VERSION ""

NS_ :

BS_:

BU_: VMCU TECU OBDScanT2 IC3 HPCU EMS ECUspare2 ECUspare1 DACU CIOM BBM

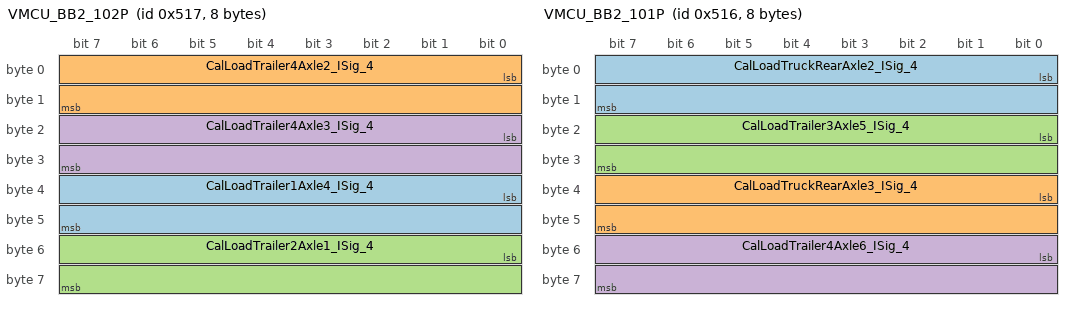
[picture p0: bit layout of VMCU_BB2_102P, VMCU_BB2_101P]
BO_ 1303 VMCU_BB2_102P: 8 VMCU
 SG_ CalLoadTrailer1Axle4_ISig_4 : 32|16@1+ (0.5,0) [0|32767.5] "kg"  IC3,CIOM,BBM
 SG_ CalLoadTrailer4Axle2_ISig_4 : 0|16@1+ (0.5,0) [0|32767.5] "kg"  CIOM,IC3
 SG_ CalLoadTrailer2Axle1_ISig_4 : 48|16@1+ (0.5,0) [0|32767.5] "kg"  CIOM,BBM,IC3
 SG_ CalLoadTrailer4Axle3_ISig_4 : 16|16@1+ (0.5,0) [0|32767.5] "kg"  CIOM,IC3

BO_ 1302 VMCU_BB2_101P: 8 VMCU
 SG_ CalLoadTruckRearAxle2_ISig_4 : 0|16@1+ (0.5,0) [0|32767.5] "kg"  BBM,IC3,CIOM
 SG_ CalLoadTruckRearAxle3_ISig_4 : 32|16@1+ (0.5,0) [0|32767.5] "kg"  BBM,CIOM,IC3
 SG_ CalLoadTrailer3Axle5_ISig_4 : 16|16@1+ (0.5,0) [0|32767.5] "kg"  IC3,CIOM
 SG_ CalLoadTrailer4Axle6_ISig_4 : 48|16@1+ (0.5,0) [0|32767.5] "kg"  IC3,CIOM

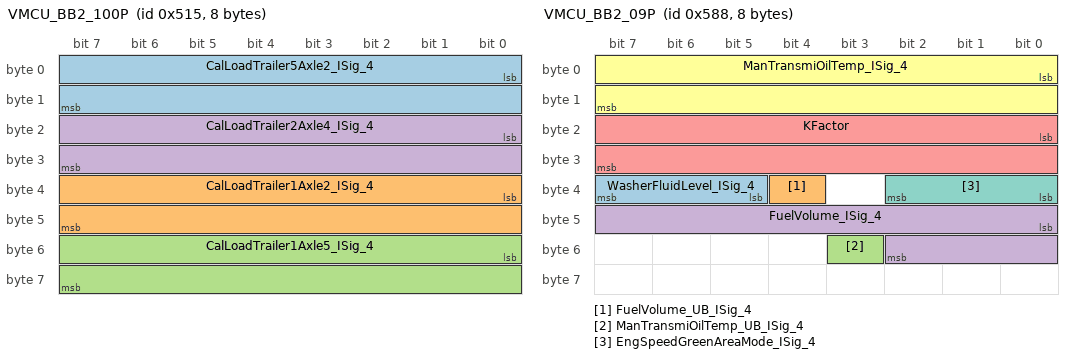
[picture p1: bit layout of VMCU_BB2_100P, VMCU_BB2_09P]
BO_ 1301 VMCU_BB2_100P: 8 VMCU
 SG_ CalLoadTrailer5Axle2_ISig_4 : 0|16@1+ (0.5,0) [0|32767.5] "kg"  CIOM,IC3
 SG_ CalLoadTrailer1Axle2_ISig_4 : 32|16@1+ (0.5,0) [0|32767.5] "kg"  IC3,CIOM,BBM
 SG_ CalLoadTrailer1Axle5_ISig_4 : 48|16@1+ (0.5,0) [0|32767.5] "kg"  IC3,CIOM
 SG_ CalLoadTrailer2Axle4_ISig_4 : 16|16@1+ (0.5,0) [0|32767.5] "kg"  CIOM,BBM,IC3

BO_ 1416 VMCU_BB2_09P: 8 VMCU
 SG_ WasherFluidLevel_ISig_4 : 37|3@1+ (1,0) [0|0] ""  IC3
 SG_ FuelVolume_UB_ISig_4 : 36|1@1+ (1,0) [0|0] ""  IC3
 SG_ ManTransmiOilTemp_UB_ISig_4 : 51|1@1+ (1,0) [0|0] ""  IC3
 SG_ FuelVolume_ISig_4 : 40|11@1+ (1,0) [0|2047] "l"  IC3
 SG_ KFactor : 16|16@1+ (1,0) [0|65535] "NotApplicable"  EMS,TECU,BBM,DACU
 SG_ ManTransmiOilTemp_ISig_4 : 0|16@1+ (0.03125,-273) [-273|1774.96875] "DegreeC"  IC3
 SG_ EngSpeedGreenAreaMode_ISig_4 : 32|3@1+ (1,0) [0|0] ""  IC3

BO_ 1050 VMCU_BB2_08P: 8 VMCU
 SG_ CabRoofSignLightFeedback_stat : 52|2@1+ (1,0) [0|0] ""  CIOM
 SG_ CabExtraSideWrknLightFdbk_stat_I : 4|2@1+ (1,0) [0|0] ""  CIOM,BBM
 SG_ CabWrknLightChassisFdbk_stat_ISi : 10|2@1+ (1,0) [0|0] ""  BBM,CIOM
 SG_ CabTrailerBodyLgthnFdbk_stat : 8|2@1+ (1,0) [0|0] ""  CIOM
 SG_ DiffLockInterWhlStatusSplitBox_I : 56|2@1+ (1,0) [0|0] ""  BBM
 SG_ BodyOrCabWorkingLightFdbk_stat_I : 0|2@1+ (1,0) [0|0] ""  CIOM,BBM
 SG_ WheelBasedVehicleSpeedLowRes_ISi : 32|8@1+ (1,0) [0|255] "Km_per_h"  CIOM
 SG_ AirDryerCoolingFanSpeed_rqst : 16|16@1+ (1,0) [0|65535] "rpm"  EMS
 SG_ CabFrontSpotFeedback_Status : 6|2@1+ (1,0) [0|0] ""  CIOM
 SG_ CabTiltEnableStatus : 2|2@1+ (1,0) [0|0] ""  CIOM
 SG_ TransmReverseDirectionSw_stat_IS : 58|2@1+ (1,0) [0|0] ""  BBM
 SG_ CabRoofSpotFeedback_Status : 12|2@1+ (1,0) [0|0] ""  CIOM
 SG_ CabBeaconLightFeedback_Status_IS : 50|2@1+ (1,0) [0|0] ""  CIOM,BBM
 SG_ ExtraAxleSteeringFunctionStat_IS : 60|3@1+ (1,0) [0|0] ""  CIOM
 SG_ AirDryerCoolingFanSpeed_rqst_UB : 48|1@1+ (1,0) [0|0] ""  EMS
 SG_ CabTiltLockStatus_ISig_4 : 14|2@1+ (1,0) [0|0] ""  BBM,IC3
 SG_ PositionLightRearLamp_stat_ISig_ : 45|3@1+ (1,0) [0|0] ""  IC3

BO_ 931 VMCU_BB2_07P: 8 VMCU
 SG_ Pto1BadCondition : 4|4@1+ (1,0) [0|0] ""  BBM,IC3
 SG_ PtosStatus_UB_ISig_4 : 40|1@1+ (1,0) [0|0] ""  EMS,CIOM,BBM,IC3
 SG_ Pto4BadCondition : 12|4@1+ (1,0) [0|0] ""  IC3,BBM
 SG_ Pto2BadCondition : 8|4@1+ (1,0) [0|0] ""  IC3,BBM
 SG_ PtoRequest : 18|2@1+ (1,0) [0|0] ""  EMS
 SG_ Pto2ConsentRequest : 32|2@1+ (1,0) [0|0] ""  TECU
 SG_ PBStatusDisplay_cmd_ISig_4 : 42|2@1+ (1,0) [0|0] ""  IC3
 SG_ Pto4DrivingRequest : 28|2@1+ (1,0) [0|0] ""  BBM
 SG_ Pto3Indication : 58|2@1+ (1,0) [0|0] ""  CIOM
 SG_ Pto2Status_ISig_4 : 22|2@1+ (1,0) [0|0] ""  IC3,TECU,CIOM,BBM
 SG_ Pto4Status_ISig_4 : 34|2@1+ (1,0) [0|0] ""  CIOM,IC3,BBM
 SG_ RampLevelRequestACK_ISig_4 : 44|2@1+ (1,0) [0|0] ""  CIOM
 SG_ Pto3BadCondition : 0|4@1+ (1,0) [0|0] ""  IC3,BBM
 SG_ PtosStatus_ISig_4 : 36|2@1+ (1,0) [0|0] ""  BBM,CIOM,EMS,IC3
 SG_ FrontWheelDriveAutoStatus_ISig_4 : 46|2@1+ (1,0) [0|0] ""  BBM,IC3
 SG_ Pto1ConsentRequest : 24|2@1+ (1,0) [0|0] ""  TECU
 SG_ Pto4Indication : 60|2@1+ (1,0) [0|0] ""  CIOM
 SG_ Pto1FeedbackStatus_UB_ISig_4 : 41|1@1+ (1,0) [0|0] ""  BBM,IC3
 SG_ Pto1Indication : 53|2@1+ (1,0) [0|0] ""  CIOM
 SG_ Pto3Status_ISig_4 : 16|2@1+ (1,0) [0|0] ""  BBM,IC3,CIOM
 SG_ Pto2Indication : 56|2@1+ (1,0) [0|0] ""  CIOM
 SG_ Pto1FeedbackStatus_ISig_4 : 38|2@1+ (1,0) [0|0] ""  BBM
 SG_ TransferCaseOrSplitboxPTOMode_IS : 26|2@1+ (1,0) [0|0] ""  TECU,BBM
 SG_ DirIndRearLamp_Stat_ISig_4 : 50|3@1+ (1,0) [0|0] ""  IC3
 SG_ Pto1Status_ISig_4 : 20|2@1+ (1,0) [0|0] ""  CIOM,TECU,BBM,IC3
 SG_ Pto3DrivingRequest : 30|2@1+ (1,0) [0|0] ""  BBM

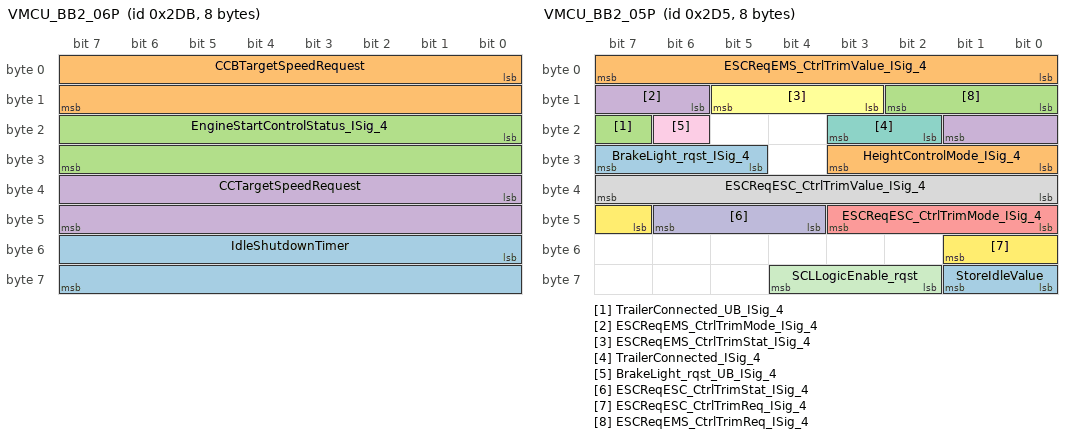
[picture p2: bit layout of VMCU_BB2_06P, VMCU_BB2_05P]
BO_ 731 VMCU_BB2_06P: 8 VMCU
 SG_ IdleShutdownTimer : 48|16@1+ (1,0) [0|65535] "s"  IC3
 SG_ CCBTargetSpeedRequest : 0|16@1+ (0.00390625,0) [0|255.99609375] "Km_per_h"  EMS,TECU
 SG_ EngineStartControlStatus_ISig_4 : 16|16@1+ (1,0) [0|0] ""  IC3,BBM
 SG_ CCTargetSpeedRequest : 32|16@1+ (0.00390625,0) [0|255.99609375] "Km_per_h"  TECU,EMS

BO_ 725 VMCU_BB2_05P: 8 VMCU
 SG_ StoreIdleValue : 56|2@1+ (1,0) [0|0] ""  IC3,EMS
 SG_ HeightControlMode_ISig_4 : 24|4@1+ (1,0) [0|0] ""  IC3
 SG_ TrailerConnected_UB_ISig_4 : 23|1@1+ (1,0) [0|0] ""  IC3,EMS,DACU,TECU,BBM
 SG_ ESCReqEMS_CtrlTrimMode_ISig_4 : 14|4@1+ (1,0) [0|0] ""  EMS,TECU,IC3
 SG_ ESCReqESC_CtrlTrimMode_ISig_4 : 40|4@1+ (1,0) [0|0] ""  CIOM,IC3,BBM
 SG_ ESCReqEMS_CtrlTrimStat_ISig_4 : 11|3@1+ (1,0) [0|0] ""  IC3,EMS,TECU
 SG_ TrailerConnected_ISig_4 : 18|2@1+ (1,0) [0|0] ""  TECU,IC3,EMS,DACU,BBM
 SG_ ESCReqESC_CtrlTrimValue_ISig_4 : 32|8@1+ (10,0) [0|2550] ""  BBM,IC3,CIOM
 SG_ BrakeLight_rqst_UB_ISig_4 : 22|1@1+ (1,0) [0|0] ""  DACU,BBM
 SG_ ESCReqESC_CtrlTrimStat_ISig_4 : 44|3@1+ (1,0) [0|0] ""  CIOM,BBM,IC3
 SG_ SCLLogicEnable_rqst : 58|3@1+ (1,0) [0|0] ""  CIOM
 SG_ ESCReqESC_CtrlTrimReq_ISig_4 : 47|3@1+ (1,0) [0|0] ""  IC3,CIOM,BBM
 SG_ BrakeLight_rqst_ISig_4 : 29|3@1+ (1,0) [0|0] ""  DACU,BBM
 SG_ ESCReqEMS_CtrlTrimValue_ISig_4 : 0|8@1+ (10,0) [0|2550] ""  IC3,TECU,EMS
 SG_ ESCReqEMS_CtrlTrimReq_ISig_4 : 8|3@1+ (1,0) [0|0] ""  IC3,TECU,EMS

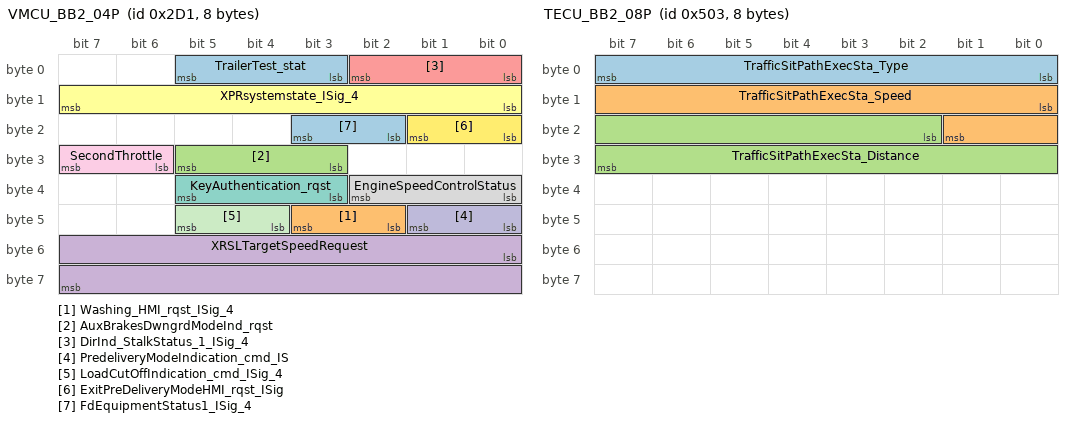
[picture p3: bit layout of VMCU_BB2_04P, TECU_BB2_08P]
BO_ 721 VMCU_BB2_04P: 8 VMCU
 SG_ TrailerTest_stat : 3|3@1+ (1,0) [0|0] ""  IC3
 SG_ Washing_HMI_rqst_ISig_4 : 42|2@1+ (1,0) [0|0] ""  CIOM
 SG_ AuxBrakesDwngrdModeInd_rqst : 27|3@1+ (1,0) [0|0] ""  IC3
 SG_ XRSLTargetSpeedRequest : 48|16@1+ (0.00390625,0) [0|255.99609375] "Km_per_h"  EMS
 SG_ DirInd_StalkStatus_1_ISig_4 : 0|3@1+ (1,0) [0|0] ""  IC3
 SG_ XPRsystemstate_ISig_4 : 8|8@1+ (1,0) [0|255] "NotApplicable"  DACU,BBM
 SG_ KeyAuthentication_rqst : 35|3@1+ (1,0) [0|0] ""  CIOM
 SG_ EngineSpeedControlStatus : 32|3@1+ (1,0) [0|0] ""  CIOM,IC3,BBM
 SG_ SecondThrottle : 30|2@1+ (1,0) [0|0] ""  EMS,DACU,BBM
 SG_ PredeliveryModeIndication_cmd_IS : 40|2@1+ (1,0) [0|0] ""  IC3,CIOM
 SG_ LoadCutOffIndication_cmd_ISig_4 : 44|2@1+ (1,0) [0|0] ""  IC3
 SG_ ExitPreDeliveryModeHMI_rqst_ISig : 16|2@1+ (1,0) [0|0] ""  CIOM
 SG_ FdEquipmentStatus1_ISig_4 : 18|2@1+ (1,0) [0|0] ""  BBM,IC3,CIOM

BO_ 534 VMCU_BB2_03P: 8 VMCU
 SG_ ParkBrakeAlert_ISig_4 : 42|2@1+ (1,0) [0|0] ""  IC3,BBM
 SG_ IntLightMode_CoreRqst_IL_Mode : 48|3@1+ (1,0) [0|0] ""  IC3,CIOM
 SG_ WiperModeStatus_UB_ISig_4 : 55|1@1+ (1,0) [0|0] ""  CIOM,BBM,IC3,DACU
 SG_ SteeringColumnLockErrInd_rqst : 27|3@1+ (1,0) [0|0] ""  IC3
 SG_ ParkingLight_Indication : 30|2@1+ (1,0) [0|0] ""  CIOM
 SG_ DaytimeRunningLight_Indication : 16|2@1+ (1,0) [0|0] ""  CIOM
 SG_ EPBBackupMode_ISig_4 : 44|4@1+ (1,0) [0|0] ""  IC3
 SG_ WiperModeStatus_ISig_4 : 32|3@1+ (1,0) [0|0] ""  CIOM,DACU,IC3,BBM
 SG_ FrontFog_Indication_ISig_4 : 22|2@1+ (1,0) [0|0] ""  CIOM
 SG_ PBReleaseAcceptance_stat_ISig_4 : 37|3@1+ (1,0) [0|0] ""  IC3
 SG_ ParkingBrake_stat_UB_ISig_4 : 54|1@1+ (1,0) [0|0] ""  IC3,EMS,CIOM,DACU,TECU,BBM
 SG_ DrivingLightPlus_Indication : 8|2@1+ (1,0) [0|0] ""  CIOM
 SG_ IntLightMode_CoreRqst_EventFlag : 51|1@1+ (1,0) [0|0] ""  CIOM,IC3
 SG_ ParkingBrake_stat_ISig_4 : 40|2@1+ (1,0) [0|0] ""  EMS,DACU,IC3,CIOM,BBM,TECU
 SG_ DrivingLight_Indication : 4|2@1+ (1,0) [0|0] ""  CIOM
 SG_ MirrorHeatingMode_ISig_4 : 24|3@1+ (1,0) [0|0] ""  CIOM
 SG_ RearFog_Indication : 35|2@1+ (1,0) [0|0] ""  CIOM
 SG_ InteriorLightLevelInd_cmd : 56|8@1+ (1,0) [0|255] "Percent"  CIOM

BO_ 532 VMCU_BB2_02P: 8 VMCU
 SG_ LevelControlInformation_UB_ISig_ : 22|1@1+ (1,0) [0|0] ""  CIOM,IC3,TECU
 SG_ LiftAxle2LiftFuncSelected_ISig_4 : 11|3@1+ (1,0) [0|0] ""  IC3
 SG_ StopLevelChangeAck_ISig_4 : 6|2@1+ (1,0) [0|0] ""  CIOM
 SG_ HeightAdjustmentAllowed_ISig_4 : 38|2@1+ (1,0) [0|0] ""  CIOM
 SG_ LiftAxle2LowerACK_ISig_4 : 27|3@1+ (1,0) [0|0] ""  IC3
 SG_ LiftAxle2UpRequestACK_ISig_4 : 0|3@1+ (1,0) [0|0] ""  CIOM,IC3
 SG_ RideHeightStatus_ISig_4 : 44|4@1+ (1,0) [0|0] ""  CIOM,BBM
 SG_ RideHeightOutsideTargetRange_ISi : 32|3@1+ (1,0) [0|0] ""  IC3,CIOM
 SG_ LoadDistributionFuncSelected_ISi : 56|4@1+ (1,0) [0|0] ""  CIOM
 SG_ RideHeightStorageAck_ISig_4 : 30|2@1+ (1,0) [0|0] ""  CIOM
 SG_ LiftAxle2AutoLiftSelected_ISig_4 : 54|2@1+ (1,0) [0|0] ""  IC3
 SG_ LiftAxle1UpRequestACK_ISig_4 : 3|3@1+ (1,0) [0|0] ""  IC3,CIOM
 SG_ LiftAxle1PositionStatus_ISig_4 : 16|3@1+ (1,0) [0|0] ""  BBM,CIOM,TECU,DACU,IC3
 SG_ LiftAxle1LowerACK_ISig_4 : 24|3@1+ (1,0) [0|0] ""  IC3
 SG_ LiftAxle1AutoLiftSelected_ISig_4 : 52|2@1+ (1,0) [0|0] ""  IC3
 SG_ LiftAxle2PositionStatus_ISig_4 : 19|3@1+ (1,0) [0|0] ""  IC3,BBM,CIOM
 SG_ LevelControlInformation_ISig_4 : 48|4@1+ (1,0) [0|0] ""  TECU,IC3,CIOM
 SG_ LiftAxle1LiftFuncSelected_ISig_4 : 8|3@1+ (1,0) [0|0] ""  IC3
 SG_ LoadDistributionChangeACK_ISig_4 : 35|3@1+ (1,0) [0|0] ""  CIOM,IC3
 SG_ RampLevelStorageAck_ISig_4 : 14|2@1+ (1,0) [0|0] ""  CIOM
 SG_ LoadDistributionSelected_ISig_4 : 60|4@1+ (1,0) [0|0] ""  BBM,CIOM
 SG_ RideHeightFunctionStatus_ISig_4 : 40|4@1+ (1,0) [0|0] ""  CIOM

BO_ 520 VMCU_BB2_01P: 8 VMCU
 SG_ GearSplit_Status_UB_ISig_4 : 13|1@1+ (1,0) [0|0] ""  IC3,BBM
 SG_ TransmLowRangeSenseSwitch_ISig_4 : 34|2@1+ (1,0) [0|0] ""  IC3,EMS
 SG_ TransmSystemPowerDown_rqst : 30|2@1+ (1,0) [0|0] ""  TECU
 SG_ TransmissionNeutralSwitch_ISig_4 : 8|2@1+ (1,0) [0|0] ""  BBM,EMS
 SG_ SecuredNeutralPosition_ISig_4 : 36|2@1+ (1,0) [0|0] ""  EMS,IC3,BBM
 SG_ EngineStopRequest_ISig_4 : 4|2@1+ (1,0) [0|0] ""  EMS
 SG_ TransmissionNeutralSwitch_UB_ISi : 32|1@1+ (1,0) [0|0] ""  EMS,BBM
 SG_ ReverseGearEngaged_ISig_4 : 0|2@1+ (1,0) [0|0] ""  DACU,EMS,CIOM,BBM,IC3
 SG_ TransmSystemPowerDown_rqst_UB : 33|1@1+ (1,0) [0|0] ""  TECU
 SG_ EngineCrankRequest : 14|2@1+ (1,0) [0|0] ""  EMS
 SG_ ParkBrakeActuationStatus_UB_ISig : 39|1@1+ (1,0) [0|0] ""  IC3,TECU,BBM
 SG_ ParkBrakeActuationStatus_ISig_4 : 40|3@1+ (1,0) [0|0] ""  TECU,DACU,BBM,IC3
 SG_ EnginePreheat_rqst : 28|2@1+ (1,0) [0|0] ""  EMS
 SG_ ReverseGearEngaged_UB_ISig_4 : 12|1@1+ (1,0) [0|0] ""  EMS,DACU,IC3,CIOM,BBM
 SG_ AcceleratorPedalPositionBackup : 56|8@1+ (0.4,0) [0|102] "Percent"  EMS,TECU
 SG_ KeyPosition_ISig_4 : 16|3@1+ (1,0) [0|0] ""  CIOM,IC3
 SG_ GearSplit_Status_ISig_4 : 2|2@1+ (1,0) [0|0] ""  IC3,BBM
 SG_ FerryFunctionSwitchChangeACK_ISi : 45|2@1+ (1,0) [0|0] ""  CIOM
 SG_ SecuredNeutralPosition_UB_ISig_4 : 38|1@1+ (1,0) [0|0] ""  BBM,IC3,EMS
 SG_ DirectionIndication_cmd : 24|4@1+ (1,0) [0|0] ""  IC3
 SG_ IdleShutdownWarning : 6|2@1+ (1,0) [0|0] ""  IC3
 SG_ BackToDriveReqACK_ISig_4 : 43|2@1+ (1,0) [0|0] ""  CIOM
 SG_ EngineSystemPowerDownRequest_ISi : 22|2@1+ (1,0) [0|0] ""  EMS,IC3

BO_ 2671902706 TesterFuncDiagMsg_BB2: 8 VMCU
 SG_ FuncDiagDataTester_ISig_4 : 0|64@1+ (1,0) [0|0] ""  IC3,BBM,HPCU,EMS,DACU,CIOM,TECU

BO_ 1283 TECU_BB2_08P: 8 TECU
 SG_ TrafficSitPathExecSta_Type : 0|8@1+ (1,0) [0|0] ""  DACU
 SG_ TrafficSitPathExecSta_Speed : 8|10@1+ (0.25,0) [0|255.75] "Km_per_h"  DACU
 SG_ TrafficSitPathExecSta_Distance : 18|14@1+ (1,0) [0|16383] "m"  DACU

BO_ 1463 TECU_BB2_07P: 8 TECU
 SG_ TECU_Available_Log_ISig_4 : 0|8@1+ (1,0) [0|0] ""  IC3

BO_ 1446 TECU_BB2_06S_FCM: 8 CIOM
 SG_ TECU_BB2_06S_FCS : 0|64@1+ (1,0) [0|0] ""  TECU

BO_ 1445 TECU_BB2_06S: 11 TECU
 SG_ ECU5VIN_stat : 0|88@1+ (1,0) [0|0] ""  CIOM

BO_ 939 TECU_BB2_05S_FCM: 8 CIOM
 SG_ TECU_BB2_05S_FCS : 0|64@1+ (1,0) [0|0] ""  TECU

BO_ 938 TECU_BB2_05S: 16 TECU
 SG_ KeyID_EncryptedGBUnlockAuth : 0|128@1+ (1,0) [0|0] ""  CIOM

BO_ 1480 TECU_BB2_04S_FCM: 8 IC3
 SG_ TECU_BB2_04S_FCS : 0|64@1+ (1,0) [0|0] ""  TECU

BO_ 1479 TECU_BB2_04S: 284 TECU
 SG_ HillDataPkgTECU_ISig_4 : 0|2272@1+ (1,0) [0|0] ""  IC3

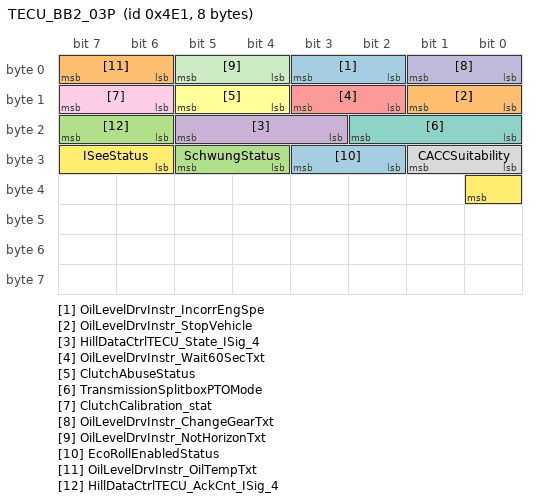
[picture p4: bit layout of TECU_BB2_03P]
BO_ 1249 TECU_BB2_03P: 8 TECU
 SG_ OilLevelDrvInstr_IncorrEngSpe : 2|2@1+ (1,0) [0|0] ""  IC3
 SG_ OilLevelDrvInstr_StopVehicle : 8|2@1+ (1,0) [0|0] ""  IC3
 SG_ SchwungStatus : 28|2@1+ (1,0) [0|0] ""  VMCU
 SG_ HillDataCtrlTECU_State_ISig_4 : 19|3@1+ (1,0) [0|0] ""  IC3
 SG_ OilLevelDrvInstr_Wait60SecTxt : 10|2@1+ (1,0) [0|0] ""  IC3
 SG_ ClutchAbuseStatus : 12|2@1+ (1,0) [0|0] ""  IC3
 SG_ TransmissionSplitboxPTOMode : 16|3@1+ (1,0) [0|0] ""  IC3
 SG_ CACCSuitability : 24|2@1+ (1,0) [0|0] ""  DACU
 SG_ ClutchCalibration_stat : 14|2@1+ (1,0) [0|0] ""  IC3
 SG_ OilLevelDrvInstr_ChangeGearTxt : 0|2@1+ (1,0) [0|0] ""  IC3
 SG_ OilLevelDrvInstr_NotHorizonTxt : 4|2@1+ (1,0) [0|0] ""  IC3
 SG_ ISeeStatus : 30|3@1+ (1,0) [0|0] ""  IC3,DACU
 SG_ EcoRollEnabledStatus : 26|2@1+ (1,0) [0|0] ""  IC3
 SG_ OilLevelDrvInstr_OilTempTxt : 6|2@1+ (1,0) [0|0] ""  IC3
 SG_ HillDataCtrlTECU_AckCnt_ISig_4 : 22|2@1+ (1,0) [0|3] ""  IC3

CM_ SG_ 1303 CalLoadTrailer1Axle4_ISig_4 "65024 - 65279 Error ; 65280 - 65535 Not available";
CM_ SG_ 1303 CalLoadTrailer4Axle2_ISig_4 "65024 - 65279 Error ; 65280 - 65535 Not available";
CM_ SG_ 1303 CalLoadTrailer2Axle1_ISig_4 "65024 - 65279 Error ; 65280 - 65535 Not available";
CM_ SG_ 1303 CalLoadTrailer4Axle3_ISig_4 "65024 - 65279 Error ; 65280 - 65535 Not available";
CM_ SG_ 1302 CalLoadTruckRearAxle2_ISig_4 "65024 - 65279 Error ; 65280 - 65535 Not available";
CM_ SG_ 1302 CalLoadTruckRearAxle3_ISig_4 "65024 - 65279 Error ; 65280 - 65535 Not available";
CM_ SG_ 1302 CalLoadTrailer3Axle5_ISig_4 "65024 - 65279 Error ; 65280 - 65535 Not available";
CM_ SG_ 1302 CalLoadTrailer4Axle6_ISig_4 "65024 - 65279 Error ; 65280 - 65535 Not available";
CM_ SG_ 1301 CalLoadTrailer5Axle2_ISig_4 "65024 - 65279 Error ; 65280 - 65535 Not available";
CM_ SG_ 1301 CalLoadTrailer1Axle2_ISig_4 "65024 - 65279 Error ; 65280 - 65535 Not available";
CM_ SG_ 1301 CalLoadTrailer1Axle5_ISig_4 "65024 - 65279 Error ; 65280 - 65535 Not available";
CM_ SG_ 1301 CalLoadTrailer2Axle4_ISig_4 "65024 - 65279 Error ; 65280 - 65535 Not available";
CM_ SG_ 1416 KFactor "65024 - 65279 Error ; 65280 - 65535 Not available";
CM_ SG_ 1416 ManTransmiOilTemp_ISig_4 "65024 - 65279 Error ; 65280 - 65535 Not available";
CM_ SG_ 1050 WheelBasedVehicleSpeedLowRes_ISi "254 Error ; 255 Not available";
CM_ SG_ 1050 AirDryerCoolingFanSpeed_rqst "65024 - 65279 Error ; 65280 - 65535 Not available";
CM_ SG_ 731 CCBTargetSpeedRequest "65024 - 65279 Error ; 65280 - 65535 Not available";
CM_ SG_ 731 EngineStartControlStatus_ISig_4 "65534 Error ; 65535 Not available";
CM_ SG_ 731 CCTargetSpeedRequest "65024 - 65279 Error ; 65280 - 65535 Not available";
CM_ SG_ 725 ESCReqESC_CtrlTrimValue_ISig_4 "254 Error ; 255 Not available";
CM_ SG_ 725 ESCReqEMS_CtrlTrimValue_ISig_4 "254 Error ; 255 Not available";
CM_ SG_ 721 XRSLTargetSpeedRequest "65024 - 65279 Error ; 65280 - 65535 Not available";
BA_DEF_ BO_  "GenMsgStartDelayTime" INT 0 0;
BA_DEF_ BO_  "GenMsgDelayTime" INT 0 0;
BA_DEF_ BO_  "GenMsgCycleTime" INT 0 0;
BA_DEF_ BO_  "GenMsgSendType" ENUM  "Cyclic","NotUsed","NotUsed","NotUsed","NotUsed","NotUsed","NotUsed","IfActive","NoMsgSendType","NotUsed";
BA_DEF_ SG_  "GenSigStartValue" INT 0 0;
BA_DEF_ SG_  "GenSigCycleTimeActive" INT 0 0;
BA_DEF_ SG_  "GenSigCycleTime" INT 0 0;
BA_DEF_ SG_  "GenSigSendType" ENUM  "Cyclic","OnWrite","OnWriteWithRepetition","OnChange","OnChangeWithRepetition","IfActive","IfActiveWithRepetition","NoSigSendType","NotUsed","NotUsed","NotUsed","NotUsed","NotUsed";
BA_DEF_ BO_  "VFrameFormat" ENUM  "StandardCAN","ExtendedCAN","reserved","J1939PG","reserved","reserved","reserved","reserved","reserved","reserved","reserved","reserved","reserved","reserved","StandardCAN_FD","ExtendedCAN_FD";
BA_DEF_ SG_  "SigType" ENUM  "Default","Range","RangeSigned","ASCII","Discrete","Control","ReferencePGN","DTC","StringDelimiter","StringLength","StringLengthControl";
BA_DEF_ SG_  "SeToolVersion_SIGNAL" STRING ;
BA_DEF_ SG_  "SeToolUniqueID_SIGNAL" STRING ;
BA_DEF_ SG_  "SeToolOwnerSigGroup_SIGNAL" STRING ;
BA_DEF_ SG_  "SeToolOwnerSigGroupID_SIGNAL" STRING ;
BA_DEF_ SG_  "SeToolName_SIGNAL" STRING ;
BA_DEF_ SG_  "SeToolItemID_SIGNAL" STRING ;
BA_DEF_ SG_  "SeToolAncestorID_SIGNAL" STRING ;
BA_DEF_ SG_  "Platform_VMCU1_Sig" ENUM  "No","Yes";
BA_DEF_ SG_  "Platform_FactoryIf_Sig" ENUM  "No","Yes";
BA_DEF_ BO_  "NmAsrMessage" ENUM  "No","Yes";
BA_DEF_ SG_  "NeedsUpdateBit" ENUM  "No","Yes";
BA_DEF_ SG_  "MmAnSignal" ENUM  "No","Yes";
BA_DEF_ SG_  "GenSigMaxLatency" INT 0 65535;
BA_DEF_ SG_  "GenSigILSupport" ENUM  "Yes","No";
BA_DEF_ BO_  "GenMsgILSupport" ENUM  "No","Yes";
BA_DEF_ BO_  "DiagUUDTResponse" ENUM  "No","Yes";
BA_DEF_ BO_  "DiagState" ENUM  "No","Yes";
BA_DEF_ BO_  "DiagResponse" ENUM  "No","Yes";
BA_DEF_ BO_  "DiagRequest" ENUM  "No","Yes";
BA_DEF_ BO_  "DiagConnection" HEX 0 65535;
BA_DEF_ BO_  "CanTpSTmin" INT 0 255;
BA_DEF_ BO_  "CanTpFcFrameId" HEX 0 2147483647;
BA_DEF_ BO_  "CanTpBs" INT 0 255;
BA_DEF_ SG_  "SystemSignalLongSymbol" STRING ;
BA_DEF_REL_ BU_SG_REL_  "GenSigTimeoutTime" INT 0 65535;
BA_DEF_REL_ BU_SG_REL_  "GenSigFirstTimeoutTime" INT 0 65535;
BA_DEF_DEF_  "GenMsgStartDelayTime" 0;
BA_DEF_DEF_  "GenMsgDelayTime" 0;
BA_DEF_DEF_  "GenMsgCycleTime" 0;
BA_DEF_DEF_  "GenMsgSendType" "Cyclic";
BA_DEF_DEF_  "GenSigStartValue" 0;
BA_DEF_DEF_  "GenSigCycleTimeActive" 0;
BA_DEF_DEF_  "GenSigCycleTime" 0;
BA_DEF_DEF_  "GenSigSendType" "Cyclic";
BA_DEF_DEF_  "VFrameFormat" "ExtendedCAN";
BA_DEF_DEF_  "SigType" "Default";
BA_DEF_DEF_  "SeToolVersion_SIGNAL" "";
BA_DEF_DEF_  "SeToolUniqueID_SIGNAL" "";
BA_DEF_DEF_  "SeToolOwnerSigGroup_SIGNAL" "";
BA_DEF_DEF_  "SeToolOwnerSigGroupID_SIGNAL" "";
BA_DEF_DEF_  "SeToolName_SIGNAL" "";
BA_DEF_DEF_  "SeToolItemID_SIGNAL" "";
BA_DEF_DEF_  "SeToolAncestorID_SIGNAL" "";
BA_DEF_DEF_  "Platform_VMCU1_Sig" "No";
BA_DEF_DEF_  "Platform_FactoryIf_Sig" "No";
BA_DEF_DEF_  "NmAsrMessage" "No";
BA_DEF_DEF_  "NeedsUpdateBit" "No";
BA_DEF_DEF_  "MmAnSignal" "No";
BA_DEF_DEF_  "GenSigMaxLatency" 0;
BA_DEF_DEF_  "GenSigILSupport" "Yes";
BA_DEF_DEF_  "GenMsgILSupport" "Yes";
BA_DEF_DEF_  "DiagUUDTResponse" "No";
BA_DEF_DEF_  "DiagState" "No";
BA_DEF_DEF_  "DiagResponse" "No";
BA_DEF_DEF_  "DiagRequest" "No";
BA_DEF_DEF_  "DiagConnection" 0;
BA_DEF_DEF_  "CanTpSTmin" 0;
BA_DEF_DEF_  "CanTpFcFrameId" 2147483647;
BA_DEF_DEF_  "CanTpBs" 255;
BA_DEF_DEF_REL_ "GenSigTimeoutTime" 0;
BA_DEF_DEF_REL_ "GenSigFirstTimeoutTime" 0;
BA_DEF_DEF_  "SystemSignalLongSymbol" "";
BA_ "VFrameFormat" BO_ 1303 0;
BA_ "GenMsgCycleTime" BO_ 1303 1000;
BA_ "GenMsgStartDelayTime" BO_ 1303 120;
BA_ "VFrameFormat" BO_ 1302 0;
BA_ "GenMsgCycleTime" BO_ 1302 1000;
BA_ "GenMsgStartDelayTime" BO_ 1302 115;
BA_ "VFrameFormat" BO_ 1301 0;
BA_ "GenMsgCycleTime" BO_ 1301 1000;
BA_ "GenMsgStartDelayTime" BO_ 1301 105;
BA_ "VFrameFormat" BO_ 1416 0;
BA_ "GenMsgCycleTime" BO_ 1416 500;
BA_ "GenMsgStartDelayTime" BO_ 1416 125;
BA_ "VFrameFormat" BO_ 1050 0;
BA_ "GenMsgCycleTime" BO_ 1050 100;
BA_ "GenMsgStartDelayTime" BO_ 1050 65;
BA_ "VFrameFormat" BO_ 931 0;
BA_ "GenMsgCycleTime" BO_ 931 75;
BA_ "GenMsgStartDelayTime" BO_ 931 25;
BA_ "VFrameFormat" BO_ 731 0;
BA_ "GenMsgCycleTime" BO_ 731 45;
BA_ "GenMsgStartDelayTime" BO_ 731 5;
BA_ "VFrameFormat" BO_ 725 0;
BA_ "GenMsgCycleTime" BO_ 725 45;
BA_ "GenMsgStartDelayTime" BO_ 725 10;
BA_ "VFrameFormat" BO_ 721 0;
BA_ "GenMsgCycleTime" BO_ 721 45;
BA_ "GenMsgStartDelayTime" BO_ 721 25;
BA_ "VFrameFormat" BO_ 534 0;
BA_ "GenMsgCycleTime" BO_ 534 25;
BA_ "GenMsgStartDelayTime" BO_ 534 5;
BA_ "VFrameFormat" BO_ 532 0;
BA_ "GenMsgCycleTime" BO_ 532 25;
BA_ "GenMsgStartDelayTime" BO_ 532 10;
BA_ "VFrameFormat" BO_ 520 0;
BA_ "GenMsgCycleTime" BO_ 520 20;
BA_ "DiagConnection" BO_ 2671902706 62182;
BA_ "DiagState" BO_ 2671902706 1;
BA_ "GenMsgILSupport" BO_ 2671902706 0;
BA_ "GenMsgSendType" BO_ 2671902706 8;
BA_ "VFrameFormat" BO_ 1283 0;
BA_ "GenMsgCycleTime" BO_ 1283 100;
BA_ "GenMsgStartDelayTime" BO_ 1283 15;
BA_ "VFrameFormat" BO_ 1463 0;
BA_ "GenMsgCycleTime" BO_ 1463 5000;
BA_ "GenMsgStartDelayTime" BO_ 1463 235;
BA_ "GenMsgILSupport" BO_ 1446 0;
BA_ "VFrameFormat" BO_ 1446 0;
BA_ "GenMsgSendType" BO_ 1446 8;
BA_ "CanTpFcFrameId" BO_ 1445 1446;
BA_ "VFrameFormat" BO_ 1445 0;
BA_ "GenMsgSendType" BO_ 1445 8;
BA_ "GenMsgDelayTime" BO_ 1445 110;
BA_ "GenMsgILSupport" BO_ 939 0;
BA_ "VFrameFormat" BO_ 939 0;
BA_ "GenMsgSendType" BO_ 939 8;
BA_ "CanTpFcFrameId" BO_ 938 939;
BA_ "VFrameFormat" BO_ 938 0;
BA_ "GenMsgSendType" BO_ 938 8;
BA_ "GenMsgDelayTime" BO_ 938 20;
BA_ "CanTpSTmin" BO_ 1480 5;
BA_ "GenMsgILSupport" BO_ 1480 0;
BA_ "VFrameFormat" BO_ 1480 0;
BA_ "GenMsgSendType" BO_ 1480 8;
BA_ "CanTpFcFrameId" BO_ 1479 1480;
BA_ "CanTpSTmin" BO_ 1479 5;
BA_ "VFrameFormat" BO_ 1479 0;
BA_ "GenMsgSendType" BO_ 1479 8;
BA_ "GenMsgDelayTime" BO_ 1479 2290;
BA_ "GenMsgStartDelayTime" BO_ 1479 50;
BA_ "VFrameFormat" BO_ 1249 0;
BA_ "GenMsgCycleTime" BO_ 1249 500;
BA_ "GenMsgStartDelayTime" BO_ 1249 100;
BA_ "GenSigCycleTime" SG_ 1303 CalLoadTrailer1Axle4_ISig_4 100;
BA_ "GenSigCycleTimeActive" SG_ 1303 CalLoadTrailer1Axle4_ISig_4 100;
BA_ "GenSigStartValue" SG_ 1303 CalLoadTrailer1Axle4_ISig_4 65535;
BA_ "GenSigCycleTime" SG_ 1303 CalLoadTrailer4Axle2_ISig_4 100;
BA_ "GenSigCycleTimeActive" SG_ 1303 CalLoadTrailer4Axle2_ISig_4 100;
BA_ "GenSigStartValue" SG_ 1303 CalLoadTrailer4Axle2_ISig_4 65535;
BA_ "GenSigCycleTime" SG_ 1303 CalLoadTrailer2Axle1_ISig_4 100;
BA_ "GenSigCycleTimeActive" SG_ 1303 CalLoadTrailer2Axle1_ISig_4 100;
BA_ "GenSigStartValue" SG_ 1303 CalLoadTrailer2Axle1_ISig_4 65535;
BA_ "GenSigCycleTime" SG_ 1303 CalLoadTrailer4Axle3_ISig_4 100;
BA_ "GenSigCycleTimeActive" SG_ 1303 CalLoadTrailer4Axle3_ISig_4 100;
BA_ "GenSigStartValue" SG_ 1303 CalLoadTrailer4Axle3_ISig_4 65535;
BA_ "GenSigCycleTime" SG_ 1302 CalLoadTruckRearAxle2_ISig_4 100;
BA_ "GenSigCycleTimeActive" SG_ 1302 CalLoadTruckRearAxle2_ISig_4 100;
BA_ "GenSigStartValue" SG_ 1302 CalLoadTruckRearAxle2_ISig_4 65535;
BA_ "GenSigCycleTime" SG_ 1302 CalLoadTruckRearAxle3_ISig_4 100;
BA_ "GenSigCycleTimeActive" SG_ 1302 CalLoadTruckRearAxle3_ISig_4 100;
BA_ "GenSigStartValue" SG_ 1302 CalLoadTruckRearAxle3_ISig_4 65535;
BA_ "GenSigCycleTime" SG_ 1302 CalLoadTrailer3Axle5_ISig_4 100;
BA_ "GenSigCycleTimeActive" SG_ 1302 CalLoadTrailer3Axle5_ISig_4 100;
BA_ "GenSigStartValue" SG_ 1302 CalLoadTrailer3Axle5_ISig_4 65535;
BA_ "GenSigCycleTime" SG_ 1302 CalLoadTrailer4Axle6_ISig_4 100;
BA_ "GenSigCycleTimeActive" SG_ 1302 CalLoadTrailer4Axle6_ISig_4 100;
BA_ "GenSigStartValue" SG_ 1302 CalLoadTrailer4Axle6_ISig_4 65535;
BA_ "GenSigCycleTime" SG_ 1301 CalLoadTrailer5Axle2_ISig_4 100;
BA_ "GenSigCycleTimeActive" SG_ 1301 CalLoadTrailer5Axle2_ISig_4 100;
BA_ "GenSigStartValue" SG_ 1301 CalLoadTrailer5Axle2_ISig_4 65535;
BA_ "GenSigCycleTime" SG_ 1301 CalLoadTrailer1Axle2_ISig_4 100;
BA_ "GenSigCycleTimeActive" SG_ 1301 CalLoadTrailer1Axle2_ISig_4 100;
BA_ "GenSigStartValue" SG_ 1301 CalLoadTrailer1Axle2_ISig_4 65535;
BA_ "GenSigCycleTime" SG_ 1301 CalLoadTrailer1Axle5_ISig_4 100;
BA_ "GenSigCycleTimeActive" SG_ 1301 CalLoadTrailer1Axle5_ISig_4 100;
BA_ "GenSigStartValue" SG_ 1301 CalLoadTrailer1Axle5_ISig_4 65535;
BA_ "GenSigCycleTime" SG_ 1301 CalLoadTrailer2Axle4_ISig_4 100;
BA_ "GenSigCycleTimeActive" SG_ 1301 CalLoadTrailer2Axle4_ISig_4 100;
BA_ "GenSigStartValue" SG_ 1301 CalLoadTrailer2Axle4_ISig_4 65535;
BA_ "GenSigCycleTime" SG_ 1416 WasherFluidLevel_ISig_4 100;
BA_ "GenSigCycleTimeActive" SG_ 1416 WasherFluidLevel_ISig_4 100;
BA_ "GenSigStartValue" SG_ 1416 WasherFluidLevel_ISig_4 7;
BA_ "GenSigMaxLatency" SG_ 1416 WasherFluidLevel_ISig_4 1110;
BA_ "Platform_VMCU1_Sig" SG_ 1416 WasherFluidLevel_ISig_4 1;
BA_ "SeToolAncestorID_SIGNAL" SG_ 1416 WasherFluidLevel_ISig_4 "x0000001D04104D03";
BA_ "SeToolItemID_SIGNAL" SG_ 1416 WasherFluidLevel_ISig_4 "x0000001D0435D527";
BA_ "SeToolName_SIGNAL" SG_ 1416 WasherFluidLevel_ISig_4 "WasherFluidLevel";
BA_ "SeToolVersion_SIGNAL" SG_ 1416 WasherFluidLevel_ISig_4 "3";
BA_ "GenSigSendType" SG_ 1416 FuelVolume_UB_ISig_4 7;
BA_ "Platform_VMCU1_Sig" SG_ 1416 FuelVolume_UB_ISig_4 1;
BA_ "GenSigSendType" SG_ 1416 ManTransmiOilTemp_UB_ISig_4 7;
BA_ "Platform_VMCU1_Sig" SG_ 1416 ManTransmiOilTemp_UB_ISig_4 1;
BA_ "GenSigCycleTime" SG_ 1416 FuelVolume_ISig_4 100;
BA_ "GenSigCycleTimeActive" SG_ 1416 FuelVolume_ISig_4 100;
BA_ "GenSigStartValue" SG_ 1416 FuelVolume_ISig_4 2047;
BA_ "NeedsUpdateBit" SG_ 1416 FuelVolume_ISig_4 1;
BA_ "Platform_VMCU1_Sig" SG_ 1416 FuelVolume_ISig_4 1;
BA_ "GenSigCycleTime" SG_ 1416 KFactor 100;
BA_ "GenSigCycleTimeActive" SG_ 1416 KFactor 100;
BA_ "GenSigStartValue" SG_ 1416 KFactor 65535;
BA_ "GenSigMaxLatency" SG_ 1416 KFactor 511;
BA_ "Platform_FactoryIf_Sig" SG_ 1416 KFactor 1;
BA_ "Platform_VMCU1_Sig" SG_ 1416 KFactor 1;
BA_ "SeToolAncestorID_SIGNAL" SG_ 1416 KFactor "x0000001D0416ED52";
BA_ "SeToolItemID_SIGNAL" SG_ 1416 KFactor "x0000001D041B55DB";
BA_ "SeToolName_SIGNAL" SG_ 1416 KFactor "K-Factor";
BA_ "SeToolVersion_SIGNAL" SG_ 1416 KFactor "2";
BA_ "GenSigCycleTime" SG_ 1416 ManTransmiOilTemp_ISig_4 100;
BA_ "GenSigCycleTimeActive" SG_ 1416 ManTransmiOilTemp_ISig_4 100;
BA_ "GenSigStartValue" SG_ 1416 ManTransmiOilTemp_ISig_4 65535;
BA_ "NeedsUpdateBit" SG_ 1416 ManTransmiOilTemp_ISig_4 1;
BA_ "Platform_VMCU1_Sig" SG_ 1416 ManTransmiOilTemp_ISig_4 1;
BA_ "GenSigCycleTime" SG_ 1416 EngSpeedGreenAreaMode_ISig_4 100;
BA_ "GenSigCycleTimeActive" SG_ 1416 EngSpeedGreenAreaMode_ISig_4 100;
BA_ "GenSigStartValue" SG_ 1416 EngSpeedGreenAreaMode_ISig_4 7;
BA_ "Platform_VMCU1_Sig" SG_ 1416 EngSpeedGreenAreaMode_ISig_4 1;
BA_ "GenSigCycleTime" SG_ 1050 CabRoofSignLightFeedback_stat 100;
BA_ "GenSigCycleTimeActive" SG_ 1050 CabRoofSignLightFeedback_stat 100;
BA_ "GenSigStartValue" SG_ 1050 CabRoofSignLightFeedback_stat 3;
BA_ "Platform_VMCU1_Sig" SG_ 1050 CabRoofSignLightFeedback_stat 1;
BA_ "SeToolAncestorID_SIGNAL" SG_ 1050 CabRoofSignLightFeedback_stat "x0000001D041B0A30";
BA_ "SeToolItemID_SIGNAL" SG_ 1050 CabRoofSignLightFeedback_stat "x0000001D041B0A30";
BA_ "SeToolName_SIGNAL" SG_ 1050 CabRoofSignLightFeedback_stat "CabRoofSignLightFeedback_Status";
BA_ "SeToolVersion_SIGNAL" SG_ 1050 CabRoofSignLightFeedback_stat "1";
BA_ "GenSigCycleTime" SG_ 1050 CabExtraSideWrknLightFdbk_stat_I 100;
BA_ "GenSigCycleTimeActive" SG_ 1050 CabExtraSideWrknLightFdbk_stat_I 100;
BA_ "GenSigStartValue" SG_ 1050 CabExtraSideWrknLightFdbk_stat_I 3;
BA_ "GenSigMaxLatency" SG_ 1050 CabExtraSideWrknLightFdbk_stat_I 112;
BA_ "Platform_VMCU1_Sig" SG_ 1050 CabExtraSideWrknLightFdbk_stat_I 1;
BA_ "SeToolAncestorID_SIGNAL" SG_ 1050 CabExtraSideWrknLightFdbk_stat_I "x0000001D041B0A4B";
BA_ "SeToolItemID_SIGNAL" SG_ 1050 CabExtraSideWrknLightFdbk_stat_I "x0000001D041B0A4B";
BA_ "SeToolName_SIGNAL" SG_ 1050 CabExtraSideWrknLightFdbk_stat_I "CabExtraSideWorkingFeedback_Status";
BA_ "SeToolVersion_SIGNAL" SG_ 1050 CabExtraSideWrknLightFdbk_stat_I "1";
BA_ "SystemSignalLongSymbol" SG_ 1050 CabExtraSideWrknLightFdbk_stat_I "CabExtraSideWrknLightFdbk_stat_ISig_4";
BA_ "GenSigCycleTime" SG_ 1050 CabWrknLightChassisFdbk_stat_ISi 100;
BA_ "GenSigCycleTimeActive" SG_ 1050 CabWrknLightChassisFdbk_stat_ISi 100;
BA_ "GenSigStartValue" SG_ 1050 CabWrknLightChassisFdbk_stat_ISi 3;
BA_ "GenSigMaxLatency" SG_ 1050 CabWrknLightChassisFdbk_stat_ISi 112;
BA_ "Platform_VMCU1_Sig" SG_ 1050 CabWrknLightChassisFdbk_stat_ISi 1;
BA_ "SeToolAncestorID_SIGNAL" SG_ 1050 CabWrknLightChassisFdbk_stat_ISi "x0000001D041B0A49";
BA_ "SeToolItemID_SIGNAL" SG_ 1050 CabWrknLightChassisFdbk_stat_ISi "x0000001D041B0A49";
BA_ "SeToolName_SIGNAL" SG_ 1050 CabWrknLightChassisFdbk_stat_ISi "CabWorkingLightChassisFeedback_Status";
BA_ "SeToolVersion_SIGNAL" SG_ 1050 CabWrknLightChassisFdbk_stat_ISi "1";
BA_ "SystemSignalLongSymbol" SG_ 1050 CabWrknLightChassisFdbk_stat_ISi "CabWrknLightChassisFdbk_stat_ISig_4";
BA_ "GenSigCycleTime" SG_ 1050 CabTrailerBodyLgthnFdbk_stat 100;
BA_ "GenSigCycleTimeActive" SG_ 1050 CabTrailerBodyLgthnFdbk_stat 100;
BA_ "GenSigStartValue" SG_ 1050 CabTrailerBodyLgthnFdbk_stat 3;
BA_ "GenSigMaxLatency" SG_ 1050 CabTrailerBodyLgthnFdbk_stat 112;
BA_ "Platform_VMCU1_Sig" SG_ 1050 CabTrailerBodyLgthnFdbk_stat 1;
BA_ "SeToolAncestorID_SIGNAL" SG_ 1050 CabTrailerBodyLgthnFdbk_stat "x0000001D04206B2D";
BA_ "SeToolItemID_SIGNAL" SG_ 1050 CabTrailerBodyLgthnFdbk_stat "x0000001D04206B2D";
BA_ "SeToolName_SIGNAL" SG_ 1050 CabTrailerBodyLgthnFdbk_stat "CabTrailerBodyLightingFeedback_Status";
BA_ "SeToolVersion_SIGNAL" SG_ 1050 CabTrailerBodyLgthnFdbk_stat "1";
BA_ "GenSigCycleTime" SG_ 1050 DiffLockInterWhlStatusSplitBox_I 100;
BA_ "GenSigCycleTimeActive" SG_ 1050 DiffLockInterWhlStatusSplitBox_I 100;
BA_ "GenSigStartValue" SG_ 1050 DiffLockInterWhlStatusSplitBox_I 3;
BA_ "Platform_VMCU1_Sig" SG_ 1050 DiffLockInterWhlStatusSplitBox_I 1;
BA_ "SystemSignalLongSymbol" SG_ 1050 DiffLockInterWhlStatusSplitBox_I "DiffLockInterWhlStatusSplitBox_ISig_4";
BA_ "GenSigCycleTime" SG_ 1050 BodyOrCabWorkingLightFdbk_stat_I 100;
BA_ "GenSigCycleTimeActive" SG_ 1050 BodyOrCabWorkingLightFdbk_stat_I 100;
BA_ "GenSigStartValue" SG_ 1050 BodyOrCabWorkingLightFdbk_stat_I 3;
BA_ "GenSigMaxLatency" SG_ 1050 BodyOrCabWorkingLightFdbk_stat_I 112;
BA_ "Platform_VMCU1_Sig" SG_ 1050 BodyOrCabWorkingLightFdbk_stat_I 1;
BA_ "SeToolAncestorID_SIGNAL" SG_ 1050 BodyOrCabWorkingLightFdbk_stat_I "x0000001D041B0A46";
BA_ "SeToolItemID_SIGNAL" SG_ 1050 BodyOrCabWorkingLightFdbk_stat_I "x0000001D041B0A46";
BA_ "SeToolName_SIGNAL" SG_ 1050 BodyOrCabWorkingLightFdbk_stat_I "CabBody/CabWorkingLightFeedback_Status";
BA_ "SeToolVersion_SIGNAL" SG_ 1050 BodyOrCabWorkingLightFdbk_stat_I "1";
BA_ "SystemSignalLongSymbol" SG_ 1050 BodyOrCabWorkingLightFdbk_stat_I "BodyOrCabWorkingLightFdbk_stat_ISig_4";
BA_ "GenSigCycleTime" SG_ 1050 WheelBasedVehicleSpeedLowRes_ISi 100;
BA_ "GenSigCycleTimeActive" SG_ 1050 WheelBasedVehicleSpeedLowRes_ISi 100;
BA_ "GenSigStartValue" SG_ 1050 WheelBasedVehicleSpeedLowRes_ISi 255;
BA_ "GenSigMaxLatency" SG_ 1050 WheelBasedVehicleSpeedLowRes_ISi 112;
BA_ "Platform_VMCU1_Sig" SG_ 1050 WheelBasedVehicleSpeedLowRes_ISi 1;
BA_ "SeToolAncestorID_SIGNAL" SG_ 1050 WheelBasedVehicleSpeedLowRes_ISi "x0000001D041F9CE4";
BA_ "SeToolItemID_SIGNAL" SG_ 1050 WheelBasedVehicleSpeedLowRes_ISi "x0000001D041F9CE4";
BA_ "SeToolName_SIGNAL" SG_ 1050 WheelBasedVehicleSpeedLowRes_ISi "Wheel-BasedVehicleSpeedLowRes";
BA_ "SeToolVersion_SIGNAL" SG_ 1050 WheelBasedVehicleSpeedLowRes_ISi "1";
BA_ "SystemSignalLongSymbol" SG_ 1050 WheelBasedVehicleSpeedLowRes_ISi "WheelBasedVehicleSpeedLowRes_ISig_4";
BA_ "GenSigCycleTime" SG_ 1050 AirDryerCoolingFanSpeed_rqst 100;
BA_ "GenSigCycleTimeActive" SG_ 1050 AirDryerCoolingFanSpeed_rqst 100;
BA_ "GenSigStartValue" SG_ 1050 AirDryerCoolingFanSpeed_rqst 65535;
BA_ "GenSigMaxLatency" SG_ 1050 AirDryerCoolingFanSpeed_rqst 112;
BA_ "NeedsUpdateBit" SG_ 1050 AirDryerCoolingFanSpeed_rqst 1;
BA_ "Platform_VMCU1_Sig" SG_ 1050 AirDryerCoolingFanSpeed_rqst 1;
BA_ "SeToolAncestorID_SIGNAL" SG_ 1050 AirDryerCoolingFanSpeed_rqst "x0000001D0425B656";
BA_ "SeToolItemID_SIGNAL" SG_ 1050 AirDryerCoolingFanSpeed_rqst "x0000001D043C814A";
BA_ "SeToolName_SIGNAL" SG_ 1050 AirDryerCoolingFanSpeed_rqst "AirDryerCoolingFanSpeed_rqst";
BA_ "SeToolVersion_SIGNAL" SG_ 1050 AirDryerCoolingFanSpeed_rqst "2";
BA_ "GenSigCycleTime" SG_ 1050 CabFrontSpotFeedback_Status 100;
BA_ "GenSigCycleTimeActive" SG_ 1050 CabFrontSpotFeedback_Status 100;
BA_ "GenSigStartValue" SG_ 1050 CabFrontSpotFeedback_Status 3;
BA_ "GenSigMaxLatency" SG_ 1050 CabFrontSpotFeedback_Status 112;
BA_ "Platform_VMCU1_Sig" SG_ 1050 CabFrontSpotFeedback_Status 1;
BA_ "SeToolAncestorID_SIGNAL" SG_ 1050 CabFrontSpotFeedback_Status "x0000001D041B0A34";
BA_ "SeToolItemID_SIGNAL" SG_ 1050 CabFrontSpotFeedback_Status "x0000001D041B0A34";
BA_ "SeToolName_SIGNAL" SG_ 1050 CabFrontSpotFeedback_Status "CabFrontSpotFeedback_Status";
BA_ "SeToolVersion_SIGNAL" SG_ 1050 CabFrontSpotFeedback_Status "1";
BA_ "GenSigCycleTime" SG_ 1050 CabTiltEnableStatus 100;
BA_ "GenSigCycleTimeActive" SG_ 1050 CabTiltEnableStatus 100;
BA_ "GenSigStartValue" SG_ 1050 CabTiltEnableStatus 3;
BA_ "GenSigMaxLatency" SG_ 1050 CabTiltEnableStatus 112;
BA_ "Platform_VMCU1_Sig" SG_ 1050 CabTiltEnableStatus 1;
BA_ "SeToolAncestorID_SIGNAL" SG_ 1050 CabTiltEnableStatus "x0000001D04173E71";
BA_ "SeToolItemID_SIGNAL" SG_ 1050 CabTiltEnableStatus "x0000001D0419EA6D";
BA_ "SeToolName_SIGNAL" SG_ 1050 CabTiltEnableStatus "CabTiltEnableStatus";
BA_ "SeToolVersion_SIGNAL" SG_ 1050 CabTiltEnableStatus "2";
BA_ "GenSigCycleTime" SG_ 1050 TransmReverseDirectionSw_stat_IS 100;
BA_ "GenSigCycleTimeActive" SG_ 1050 TransmReverseDirectionSw_stat_IS 100;
BA_ "GenSigStartValue" SG_ 1050 TransmReverseDirectionSw_stat_IS 3;
BA_ "Platform_VMCU1_Sig" SG_ 1050 TransmReverseDirectionSw_stat_IS 1;
BA_ "SystemSignalLongSymbol" SG_ 1050 TransmReverseDirectionSw_stat_IS "TransmReverseDirectionSw_stat_ISig_4";
BA_ "GenSigCycleTime" SG_ 1050 CabRoofSpotFeedback_Status 100;
BA_ "GenSigCycleTimeActive" SG_ 1050 CabRoofSpotFeedback_Status 100;
BA_ "GenSigStartValue" SG_ 1050 CabRoofSpotFeedback_Status 3;
BA_ "GenSigMaxLatency" SG_ 1050 CabRoofSpotFeedback_Status 112;
BA_ "Platform_VMCU1_Sig" SG_ 1050 CabRoofSpotFeedback_Status 1;
BA_ "SeToolAncestorID_SIGNAL" SG_ 1050 CabRoofSpotFeedback_Status "x0000001D041B0A36";
BA_ "SeToolItemID_SIGNAL" SG_ 1050 CabRoofSpotFeedback_Status "x0000001D041B0A36";
BA_ "SeToolName_SIGNAL" SG_ 1050 CabRoofSpotFeedback_Status "CabRoofSpotFeedback_Status";
BA_ "SeToolVersion_SIGNAL" SG_ 1050 CabRoofSpotFeedback_Status "1";
BA_ "GenSigCycleTime" SG_ 1050 CabBeaconLightFeedback_Status_IS 100;
BA_ "GenSigCycleTimeActive" SG_ 1050 CabBeaconLightFeedback_Status_IS 100;
BA_ "GenSigStartValue" SG_ 1050 CabBeaconLightFeedback_Status_IS 3;
BA_ "GenSigMaxLatency" SG_ 1050 CabBeaconLightFeedback_Status_IS 112;
BA_ "Platform_VMCU1_Sig" SG_ 1050 CabBeaconLightFeedback_Status_IS 1;
BA_ "SeToolAncestorID_SIGNAL" SG_ 1050 CabBeaconLightFeedback_Status_IS "x0000001D041B0A09";
BA_ "SeToolItemID_SIGNAL" SG_ 1050 CabBeaconLightFeedback_Status_IS "x0000001D041B0A09";
BA_ "SeToolName_SIGNAL" SG_ 1050 CabBeaconLightFeedback_Status_IS "CabBeaconLightFeedback_Status";
BA_ "SeToolVersion_SIGNAL" SG_ 1050 CabBeaconLightFeedback_Status_IS "1";
BA_ "SystemSignalLongSymbol" SG_ 1050 CabBeaconLightFeedback_Status_IS "CabBeaconLightFeedback_Status_ISig_4";
BA_ "GenSigCycleTime" SG_ 1050 ExtraAxleSteeringFunctionStat_IS 100;
BA_ "GenSigCycleTimeActive" SG_ 1050 ExtraAxleSteeringFunctionStat_IS 100;
BA_ "GenSigStartValue" SG_ 1050 ExtraAxleSteeringFunctionStat_IS 7;
BA_ "Platform_VMCU1_Sig" SG_ 1050 ExtraAxleSteeringFunctionStat_IS 1;
BA_ "SystemSignalLongSymbol" SG_ 1050 ExtraAxleSteeringFunctionStat_IS "ExtraAxleSteeringFunctionStat_ISig_4";
BA_ "GenSigSendType" SG_ 1050 AirDryerCoolingFanSpeed_rqst_UB 7;
BA_ "GenSigCycleTime" SG_ 1050 AirDryerCoolingFanSpeed_rqst_UB 100;
BA_ "GenSigCycleTimeActive" SG_ 1050 AirDryerCoolingFanSpeed_rqst_UB 100;
BA_ "Platform_VMCU1_Sig" SG_ 1050 AirDryerCoolingFanSpeed_rqst_UB 1;
BA_ "GenSigCycleTime" SG_ 1050 CabTiltLockStatus_ISig_4 100;
BA_ "GenSigCycleTimeActive" SG_ 1050 CabTiltLockStatus_ISig_4 100;
BA_ "GenSigStartValue" SG_ 1050 CabTiltLockStatus_ISig_4 3;
BA_ "GenSigMaxLatency" SG_ 1050 CabTiltLockStatus_ISig_4 112;
BA_ "Platform_VMCU1_Sig" SG_ 1050 CabTiltLockStatus_ISig_4 1;
BA_ "SeToolAncestorID_SIGNAL" SG_ 1050 CabTiltLockStatus_ISig_4 "x0000001D04173E82";
BA_ "SeToolItemID_SIGNAL" SG_ 1050 CabTiltLockStatus_ISig_4 "x0000001D041D94E8";
BA_ "SeToolName_SIGNAL" SG_ 1050 CabTiltLockStatus_ISig_4 "CabTiltLockStatus";
BA_ "SeToolVersion_SIGNAL" SG_ 1050 CabTiltLockStatus_ISig_4 "2";
BA_ "GenSigCycleTime" SG_ 1050 PositionLightRearLamp_stat_ISig_ 100;
BA_ "GenSigCycleTimeActive" SG_ 1050 PositionLightRearLamp_stat_ISig_ 100;
BA_ "GenSigStartValue" SG_ 1050 PositionLightRearLamp_stat_ISig_ 7;
BA_ "Platform_VMCU1_Sig" SG_ 1050 PositionLightRearLamp_stat_ISig_ 1;
BA_ "SystemSignalLongSymbol" SG_ 1050 PositionLightRearLamp_stat_ISig_ "PositionLightRearLamp_stat_ISig_4";
BA_ "GenSigCycleTime" SG_ 931 Pto1BadCondition 100;
BA_ "GenSigCycleTimeActive" SG_ 931 Pto1BadCondition 100;
BA_ "GenSigStartValue" SG_ 931 Pto1BadCondition 15;
BA_ "GenSigMaxLatency" SG_ 931 Pto1BadCondition 110;
BA_ "Platform_VMCU1_Sig" SG_ 931 Pto1BadCondition 1;
BA_ "SeToolAncestorID_SIGNAL" SG_ 931 Pto1BadCondition "x0000001D042DDF2A";
BA_ "SeToolItemID_SIGNAL" SG_ 931 Pto1BadCondition "x0000001D042DDF2A";
BA_ "SeToolName_SIGNAL" SG_ 931 Pto1BadCondition "Pto1BadCondition";
BA_ "SeToolVersion_SIGNAL" SG_ 931 Pto1BadCondition "1";
BA_ "GenSigSendType" SG_ 931 PtosStatus_UB_ISig_4 7;
BA_ "Platform_VMCU1_Sig" SG_ 931 PtosStatus_UB_ISig_4 1;
BA_ "GenSigCycleTime" SG_ 931 Pto4BadCondition 100;
BA_ "GenSigCycleTimeActive" SG_ 931 Pto4BadCondition 100;
BA_ "GenSigStartValue" SG_ 931 Pto4BadCondition 15;
BA_ "GenSigMaxLatency" SG_ 931 Pto4BadCondition 110;
BA_ "Platform_VMCU1_Sig" SG_ 931 Pto4BadCondition 1;
BA_ "SeToolAncestorID_SIGNAL" SG_ 931 Pto4BadCondition "x0000001D042DE32A";
BA_ "SeToolItemID_SIGNAL" SG_ 931 Pto4BadCondition "x0000001D042DE32A";
BA_ "SeToolName_SIGNAL" SG_ 931 Pto4BadCondition "Pto4BadCondition";
BA_ "SeToolVersion_SIGNAL" SG_ 931 Pto4BadCondition "1";
BA_ "GenSigCycleTime" SG_ 931 Pto2BadCondition 100;
BA_ "GenSigCycleTimeActive" SG_ 931 Pto2BadCondition 100;
BA_ "GenSigStartValue" SG_ 931 Pto2BadCondition 15;
BA_ "GenSigMaxLatency" SG_ 931 Pto2BadCondition 110;
BA_ "Platform_VMCU1_Sig" SG_ 931 Pto2BadCondition 1;
BA_ "SeToolAncestorID_SIGNAL" SG_ 931 Pto2BadCondition "x0000001D042DE326";
BA_ "SeToolItemID_SIGNAL" SG_ 931 Pto2BadCondition "x0000001D042DE326";
BA_ "SeToolName_SIGNAL" SG_ 931 Pto2BadCondition "Pto2BadCondition";
BA_ "SeToolVersion_SIGNAL" SG_ 931 Pto2BadCondition "1";
BA_ "GenSigCycleTime" SG_ 931 PtoRequest 100;
BA_ "GenSigCycleTimeActive" SG_ 931 PtoRequest 100;
BA_ "GenSigStartValue" SG_ 931 PtoRequest 3;
BA_ "Platform_VMCU1_Sig" SG_ 931 PtoRequest 1;
BA_ "GenSigCycleTime" SG_ 931 Pto2ConsentRequest 100;
BA_ "GenSigCycleTimeActive" SG_ 931 Pto2ConsentRequest 100;
BA_ "GenSigStartValue" SG_ 931 Pto2ConsentRequest 3;
BA_ "GenSigMaxLatency" SG_ 931 Pto2ConsentRequest 110;
BA_ "Platform_VMCU1_Sig" SG_ 931 Pto2ConsentRequest 1;
BA_ "SeToolAncestorID_SIGNAL" SG_ 931 Pto2ConsentRequest "x0000001D04156EA0";
BA_ "SeToolItemID_SIGNAL" SG_ 931 Pto2ConsentRequest "x0000001D043A5C95";
BA_ "SeToolName_SIGNAL" SG_ 931 Pto2ConsentRequest "Pto2ConsentRequest";
BA_ "SeToolVersion_SIGNAL" SG_ 931 Pto2ConsentRequest "2";
BA_ "GenSigCycleTime" SG_ 931 PBStatusDisplay_cmd_ISig_4 100;
BA_ "GenSigCycleTimeActive" SG_ 931 PBStatusDisplay_cmd_ISig_4 100;
BA_ "GenSigStartValue" SG_ 931 PBStatusDisplay_cmd_ISig_4 3;
BA_ "Platform_VMCU1_Sig" SG_ 931 PBStatusDisplay_cmd_ISig_4 1;
BA_ "GenSigCycleTime" SG_ 931 Pto4DrivingRequest 100;
BA_ "GenSigCycleTimeActive" SG_ 931 Pto4DrivingRequest 100;
BA_ "GenSigStartValue" SG_ 931 Pto4DrivingRequest 3;
BA_ "GenSigMaxLatency" SG_ 931 Pto4DrivingRequest 110;
BA_ "Platform_VMCU1_Sig" SG_ 931 Pto4DrivingRequest 1;
BA_ "SeToolAncestorID_SIGNAL" SG_ 931 Pto4DrivingRequest "x0000001D041538FE";
BA_ "SeToolItemID_SIGNAL" SG_ 931 Pto4DrivingRequest "x0000001D041538FE";
BA_ "SeToolName_SIGNAL" SG_ 931 Pto4DrivingRequest "Pto4DrivingRequest";
BA_ "SeToolVersion_SIGNAL" SG_ 931 Pto4DrivingRequest "1";
BA_ "GenSigCycleTime" SG_ 931 Pto3Indication 100;
BA_ "GenSigCycleTimeActive" SG_ 931 Pto3Indication 100;
BA_ "GenSigStartValue" SG_ 931 Pto3Indication 3;
BA_ "Platform_VMCU1_Sig" SG_ 931 Pto3Indication 1;
BA_ "GenSigCycleTime" SG_ 931 Pto2Status_ISig_4 100;
BA_ "GenSigCycleTimeActive" SG_ 931 Pto2Status_ISig_4 100;
BA_ "GenSigStartValue" SG_ 931 Pto2Status_ISig_4 3;
BA_ "GenSigMaxLatency" SG_ 931 Pto2Status_ISig_4 110;
BA_ "Platform_VMCU1_Sig" SG_ 931 Pto2Status_ISig_4 1;
BA_ "SeToolAncestorID_SIGNAL" SG_ 931 Pto2Status_ISig_4 "x0000001D041534A5";
BA_ "SeToolItemID_SIGNAL" SG_ 931 Pto2Status_ISig_4 "x0000001D04321002";
BA_ "SeToolName_SIGNAL" SG_ 931 Pto2Status_ISig_4 "Pto2Status";
BA_ "SeToolVersion_SIGNAL" SG_ 931 Pto2Status_ISig_4 "3";
BA_ "GenSigCycleTime" SG_ 931 Pto4Status_ISig_4 100;
BA_ "GenSigCycleTimeActive" SG_ 931 Pto4Status_ISig_4 100;
BA_ "GenSigStartValue" SG_ 931 Pto4Status_ISig_4 3;
BA_ "GenSigMaxLatency" SG_ 931 Pto4Status_ISig_4 110;
BA_ "Platform_VMCU1_Sig" SG_ 931 Pto4Status_ISig_4 1;
BA_ "SeToolAncestorID_SIGNAL" SG_ 931 Pto4Status_ISig_4 "x0000001D041534AC";
BA_ "SeToolItemID_SIGNAL" SG_ 931 Pto4Status_ISig_4 "x0000001D04321056";
BA_ "SeToolName_SIGNAL" SG_ 931 Pto4Status_ISig_4 "Pto4Status";
BA_ "SeToolVersion_SIGNAL" SG_ 931 Pto4Status_ISig_4 "3";
BA_ "GenSigCycleTime" SG_ 931 RampLevelRequestACK_ISig_4 100;
BA_ "GenSigCycleTimeActive" SG_ 931 RampLevelRequestACK_ISig_4 100;
BA_ "GenSigStartValue" SG_ 931 RampLevelRequestACK_ISig_4 3;
BA_ "Platform_VMCU1_Sig" SG_ 931 RampLevelRequestACK_ISig_4 1;
BA_ "GenSigCycleTime" SG_ 931 Pto3BadCondition 100;
BA_ "GenSigCycleTimeActive" SG_ 931 Pto3BadCondition 100;
BA_ "GenSigStartValue" SG_ 931 Pto3BadCondition 15;
BA_ "GenSigMaxLatency" SG_ 931 Pto3BadCondition 110;
BA_ "Platform_VMCU1_Sig" SG_ 931 Pto3BadCondition 1;
BA_ "SeToolAncestorID_SIGNAL" SG_ 931 Pto3BadCondition "x0000001D042DE328";
BA_ "SeToolItemID_SIGNAL" SG_ 931 Pto3BadCondition "x0000001D042DE328";
BA_ "SeToolName_SIGNAL" SG_ 931 Pto3BadCondition "Pto3BadCondition";
BA_ "SeToolVersion_SIGNAL" SG_ 931 Pto3BadCondition "1";
BA_ "GenSigCycleTime" SG_ 931 PtosStatus_ISig_4 100;
BA_ "GenSigCycleTimeActive" SG_ 931 PtosStatus_ISig_4 100;
BA_ "GenSigStartValue" SG_ 931 PtosStatus_ISig_4 3;
BA_ "GenSigMaxLatency" SG_ 931 PtosStatus_ISig_4 110;
BA_ "NeedsUpdateBit" SG_ 931 PtosStatus_ISig_4 1;
BA_ "Platform_VMCU1_Sig" SG_ 931 PtosStatus_ISig_4 1;
BA_ "SeToolAncestorID_SIGNAL" SG_ 931 PtosStatus_ISig_4 "x0000001D042CA490";
BA_ "SeToolItemID_SIGNAL" SG_ 931 PtosStatus_ISig_4 "x0000001D042CA490";
BA_ "SeToolName_SIGNAL" SG_ 931 PtosStatus_ISig_4 "PtosStatus";
BA_ "SeToolVersion_SIGNAL" SG_ 931 PtosStatus_ISig_4 "1";
BA_ "GenSigCycleTime" SG_ 931 FrontWheelDriveAutoStatus_ISig_4 100;
BA_ "GenSigCycleTimeActive" SG_ 931 FrontWheelDriveAutoStatus_ISig_4 100;
BA_ "GenSigStartValue" SG_ 931 FrontWheelDriveAutoStatus_ISig_4 3;
BA_ "Platform_VMCU1_Sig" SG_ 931 FrontWheelDriveAutoStatus_ISig_4 1;
BA_ "GenSigCycleTime" SG_ 931 Pto1ConsentRequest 100;
BA_ "GenSigCycleTimeActive" SG_ 931 Pto1ConsentRequest 100;
BA_ "GenSigStartValue" SG_ 931 Pto1ConsentRequest 3;
BA_ "GenSigMaxLatency" SG_ 931 Pto1ConsentRequest 110;
BA_ "Platform_VMCU1_Sig" SG_ 931 Pto1ConsentRequest 1;
BA_ "SeToolAncestorID_SIGNAL" SG_ 931 Pto1ConsentRequest "x0000001D04156E9D";
BA_ "SeToolItemID_SIGNAL" SG_ 931 Pto1ConsentRequest "x0000001D043A5C3F";
BA_ "SeToolName_SIGNAL" SG_ 931 Pto1ConsentRequest "Pto1ConsentRequest";
BA_ "SeToolVersion_SIGNAL" SG_ 931 Pto1ConsentRequest "2";
BA_ "GenSigCycleTime" SG_ 931 Pto4Indication 100;
BA_ "GenSigCycleTimeActive" SG_ 931 Pto4Indication 100;
BA_ "GenSigStartValue" SG_ 931 Pto4Indication 3;
BA_ "Platform_VMCU1_Sig" SG_ 931 Pto4Indication 1;
BA_ "GenSigSendType" SG_ 931 Pto1FeedbackStatus_UB_ISig_4 7;
BA_ "Platform_VMCU1_Sig" SG_ 931 Pto1FeedbackStatus_UB_ISig_4 1;
BA_ "GenSigCycleTime" SG_ 931 Pto1Indication 100;
BA_ "GenSigCycleTimeActive" SG_ 931 Pto1Indication 100;
BA_ "GenSigStartValue" SG_ 931 Pto1Indication 3;
BA_ "Platform_VMCU1_Sig" SG_ 931 Pto1Indication 1;
BA_ "GenSigCycleTime" SG_ 931 Pto3Status_ISig_4 100;
BA_ "GenSigCycleTimeActive" SG_ 931 Pto3Status_ISig_4 100;
BA_ "GenSigStartValue" SG_ 931 Pto3Status_ISig_4 3;
BA_ "GenSigMaxLatency" SG_ 931 Pto3Status_ISig_4 110;
BA_ "Platform_VMCU1_Sig" SG_ 931 Pto3Status_ISig_4 1;
BA_ "SeToolAncestorID_SIGNAL" SG_ 931 Pto3Status_ISig_4 "x0000001D041534A7";
BA_ "SeToolItemID_SIGNAL" SG_ 931 Pto3Status_ISig_4 "x0000001D04321034";
BA_ "SeToolName_SIGNAL" SG_ 931 Pto3Status_ISig_4 "Pto3Status";
BA_ "SeToolVersion_SIGNAL" SG_ 931 Pto3Status_ISig_4 "3";
BA_ "GenSigCycleTime" SG_ 931 Pto2Indication 100;
BA_ "GenSigCycleTimeActive" SG_ 931 Pto2Indication 100;
BA_ "GenSigStartValue" SG_ 931 Pto2Indication 3;
BA_ "Platform_VMCU1_Sig" SG_ 931 Pto2Indication 1;
BA_ "GenSigCycleTime" SG_ 931 Pto1FeedbackStatus_ISig_4 100;
BA_ "GenSigCycleTimeActive" SG_ 931 Pto1FeedbackStatus_ISig_4 100;
BA_ "GenSigStartValue" SG_ 931 Pto1FeedbackStatus_ISig_4 3;
BA_ "GenSigMaxLatency" SG_ 931 Pto1FeedbackStatus_ISig_4 110;
BA_ "NeedsUpdateBit" SG_ 931 Pto1FeedbackStatus_ISig_4 1;
BA_ "Platform_VMCU1_Sig" SG_ 931 Pto1FeedbackStatus_ISig_4 1;
BA_ "SeToolAncestorID_SIGNAL" SG_ 931 Pto1FeedbackStatus_ISig_4 "x0000001D041538D8";
BA_ "SeToolItemID_SIGNAL" SG_ 931 Pto1FeedbackStatus_ISig_4 "x0000001D041538D8";
BA_ "SeToolName_SIGNAL" SG_ 931 Pto1FeedbackStatus_ISig_4 "Pto1FeedbackStatus";
BA_ "SeToolVersion_SIGNAL" SG_ 931 Pto1FeedbackStatus_ISig_4 "1";
BA_ "GenSigCycleTime" SG_ 931 TransferCaseOrSplitboxPTOMode_IS 100;
BA_ "GenSigCycleTimeActive" SG_ 931 TransferCaseOrSplitboxPTOMode_IS 100;
BA_ "GenSigStartValue" SG_ 931 TransferCaseOrSplitboxPTOMode_IS 3;
BA_ "Platform_VMCU1_Sig" SG_ 931 TransferCaseOrSplitboxPTOMode_IS 1;
BA_ "SeToolAncestorID_SIGNAL" SG_ 931 TransferCaseOrSplitboxPTOMode_IS "x0000001D0419DC89";
BA_ "SeToolItemID_SIGNAL" SG_ 931 TransferCaseOrSplitboxPTOMode_IS "x0000001D0419DC89";
BA_ "SeToolName_SIGNAL" SG_ 931 TransferCaseOrSplitboxPTOMode_IS "SplitBoxPtoStatus";
BA_ "SeToolVersion_SIGNAL" SG_ 931 TransferCaseOrSplitboxPTOMode_IS "1";
BA_ "SystemSignalLongSymbol" SG_ 931 TransferCaseOrSplitboxPTOMode_IS "TransferCaseOrSplitboxPTOMode_ISig_4";
BA_ "GenSigCycleTime" SG_ 931 DirIndRearLamp_Stat_ISig_4 100;
BA_ "GenSigCycleTimeActive" SG_ 931 DirIndRearLamp_Stat_ISig_4 100;
BA_ "GenSigStartValue" SG_ 931 DirIndRearLamp_Stat_ISig_4 7;
BA_ "Platform_VMCU1_Sig" SG_ 931 DirIndRearLamp_Stat_ISig_4 1;
BA_ "GenSigCycleTime" SG_ 931 Pto1Status_ISig_4 100;
BA_ "GenSigCycleTimeActive" SG_ 931 Pto1Status_ISig_4 100;
BA_ "GenSigStartValue" SG_ 931 Pto1Status_ISig_4 3;
BA_ "GenSigMaxLatency" SG_ 931 Pto1Status_ISig_4 110;
BA_ "Platform_VMCU1_Sig" SG_ 931 Pto1Status_ISig_4 1;
BA_ "SeToolAncestorID_SIGNAL" SG_ 931 Pto1Status_ISig_4 "x0000001D041534A3";
BA_ "SeToolItemID_SIGNAL" SG_ 931 Pto1Status_ISig_4 "x0000001D04320FF9";
BA_ "SeToolName_SIGNAL" SG_ 931 Pto1Status_ISig_4 "Pto1Status";
BA_ "SeToolVersion_SIGNAL" SG_ 931 Pto1Status_ISig_4 "3";
BA_ "GenSigCycleTime" SG_ 931 Pto3DrivingRequest 100;
BA_ "GenSigCycleTimeActive" SG_ 931 Pto3DrivingRequest 100;
BA_ "GenSigStartValue" SG_ 931 Pto3DrivingRequest 3;
BA_ "GenSigMaxLatency" SG_ 931 Pto3DrivingRequest 110;
BA_ "Platform_VMCU1_Sig" SG_ 931 Pto3DrivingRequest 1;
BA_ "SeToolAncestorID_SIGNAL" SG_ 931 Pto3DrivingRequest "x0000001D041538FC";
BA_ "SeToolItemID_SIGNAL" SG_ 931 Pto3DrivingRequest "x0000001D041538FC";
BA_ "SeToolName_SIGNAL" SG_ 931 Pto3DrivingRequest "Pto3DrivingRequest";
BA_ "SeToolVersion_SIGNAL" SG_ 931 Pto3DrivingRequest "1";
BA_ "GenSigCycleTime" SG_ 731 IdleShutdownTimer 100;
BA_ "GenSigCycleTimeActive" SG_ 731 IdleShutdownTimer 100;
BA_ "GenSigStartValue" SG_ 731 IdleShutdownTimer 65535;
BA_ "GenSigCycleTime" SG_ 731 CCBTargetSpeedRequest 100;
BA_ "GenSigCycleTimeActive" SG_ 731 CCBTargetSpeedRequest 100;
BA_ "GenSigStartValue" SG_ 731 CCBTargetSpeedRequest 65535;
BA_ "GenSigMaxLatency" SG_ 731 CCBTargetSpeedRequest 57;
BA_ "Platform_VMCU1_Sig" SG_ 731 CCBTargetSpeedRequest 1;
BA_ "SeToolAncestorID_SIGNAL" SG_ 731 CCBTargetSpeedRequest "x0000001D043FE028";
BA_ "SeToolItemID_SIGNAL" SG_ 731 CCBTargetSpeedRequest "x0000001D043FE028";
BA_ "SeToolName_SIGNAL" SG_ 731 CCBTargetSpeedRequest "CCBTargetSpeedRequest";
BA_ "SeToolVersion_SIGNAL" SG_ 731 CCBTargetSpeedRequest "1";
BA_ "GenSigCycleTime" SG_ 731 EngineStartControlStatus_ISig_4 100;
BA_ "GenSigCycleTimeActive" SG_ 731 EngineStartControlStatus_ISig_4 100;
BA_ "GenSigStartValue" SG_ 731 EngineStartControlStatus_ISig_4 65535;
BA_ "GenSigMaxLatency" SG_ 731 EngineStartControlStatus_ISig_4 57;
BA_ "Platform_VMCU1_Sig" SG_ 731 EngineStartControlStatus_ISig_4 1;
BA_ "SeToolAncestorID_SIGNAL" SG_ 731 EngineStartControlStatus_ISig_4 "x0000001D041E8EE9";
BA_ "SeToolItemID_SIGNAL" SG_ 731 EngineStartControlStatus_ISig_4 "x0000001D0425C909";
BA_ "SeToolName_SIGNAL" SG_ 731 EngineStartControlStatus_ISig_4 "EngineStartControlStatus";
BA_ "SeToolVersion_SIGNAL" SG_ 731 EngineStartControlStatus_ISig_4 "3";
BA_ "GenSigCycleTime" SG_ 731 CCTargetSpeedRequest 100;
BA_ "GenSigCycleTimeActive" SG_ 731 CCTargetSpeedRequest 100;
BA_ "GenSigStartValue" SG_ 731 CCTargetSpeedRequest 65535;
BA_ "GenSigMaxLatency" SG_ 731 CCTargetSpeedRequest 57;
BA_ "Platform_VMCU1_Sig" SG_ 731 CCTargetSpeedRequest 1;
BA_ "SeToolAncestorID_SIGNAL" SG_ 731 CCTargetSpeedRequest "x0000001D043FE024";
BA_ "SeToolItemID_SIGNAL" SG_ 731 CCTargetSpeedRequest "x0000001D043FE024";
BA_ "SeToolName_SIGNAL" SG_ 731 CCTargetSpeedRequest "CCTargetSpeedRequest";
BA_ "SeToolVersion_SIGNAL" SG_ 731 CCTargetSpeedRequest "1";
BA_ "GenSigCycleTime" SG_ 725 StoreIdleValue 100;
BA_ "GenSigCycleTimeActive" SG_ 725 StoreIdleValue 100;
BA_ "GenSigStartValue" SG_ 725 StoreIdleValue 3;
BA_ "Platform_VMCU1_Sig" SG_ 725 StoreIdleValue 1;
BA_ "GenSigCycleTime" SG_ 725 HeightControlMode_ISig_4 100;
BA_ "GenSigCycleTimeActive" SG_ 725 HeightControlMode_ISig_4 100;
BA_ "GenSigStartValue" SG_ 725 HeightControlMode_ISig_4 15;
BA_ "SeToolAncestorID_SIGNAL" SG_ 725 HeightControlMode_ISig_4 "x0000001D04348B44";
BA_ "SeToolItemID_SIGNAL" SG_ 725 HeightControlMode_ISig_4 "x0000001D04348B44";
BA_ "SeToolName_SIGNAL" SG_ 725 HeightControlMode_ISig_4 "LevelFunctionControlReq";
BA_ "SeToolVersion_SIGNAL" SG_ 725 HeightControlMode_ISig_4 "1";
BA_ "GenSigSendType" SG_ 725 TrailerConnected_UB_ISig_4 7;
BA_ "Platform_VMCU1_Sig" SG_ 725 TrailerConnected_UB_ISig_4 1;
BA_ "GenSigCycleTime" SG_ 725 ESCReqEMS_CtrlTrimMode_ISig_4 100;
BA_ "GenSigCycleTimeActive" SG_ 725 ESCReqEMS_CtrlTrimMode_ISig_4 100;
BA_ "GenSigStartValue" SG_ 725 ESCReqEMS_CtrlTrimMode_ISig_4 15;
BA_ "GenSigMaxLatency" SG_ 725 ESCReqEMS_CtrlTrimMode_ISig_4 56;
BA_ "Platform_VMCU1_Sig" SG_ 725 ESCReqEMS_CtrlTrimMode_ISig_4 1;
BA_ "SeToolAncestorID_SIGNAL" SG_ 725 ESCReqEMS_CtrlTrimMode_ISig_4 "x0000001D042A710F";
BA_ "SeToolItemID_SIGNAL" SG_ 725 ESCReqEMS_CtrlTrimMode_ISig_4 "x0000001D042A710F";
BA_ "SeToolName_SIGNAL" SG_ 725 ESCReqEMS_CtrlTrimMode_ISig_4 "CtrlTrimMode";
BA_ "SeToolOwnerSigGroupID_SIGNAL" SG_ 725 ESCReqEMS_CtrlTrimMode_ISig_4 "x0000001D043D5DDC";
BA_ "SeToolOwnerSigGroup_SIGNAL" SG_ 725 ESCReqEMS_CtrlTrimMode_ISig_4 "ESCReqEMS";
BA_ "SeToolVersion_SIGNAL" SG_ 725 ESCReqEMS_CtrlTrimMode_ISig_4 "1";
BA_ "GenSigCycleTime" SG_ 725 ESCReqESC_CtrlTrimMode_ISig_4 100;
BA_ "GenSigCycleTimeActive" SG_ 725 ESCReqESC_CtrlTrimMode_ISig_4 100;
BA_ "GenSigStartValue" SG_ 725 ESCReqESC_CtrlTrimMode_ISig_4 15;
BA_ "GenSigMaxLatency" SG_ 725 ESCReqESC_CtrlTrimMode_ISig_4 56;
BA_ "Platform_VMCU1_Sig" SG_ 725 ESCReqESC_CtrlTrimMode_ISig_4 1;
BA_ "SeToolAncestorID_SIGNAL" SG_ 725 ESCReqESC_CtrlTrimMode_ISig_4 "x0000001D042A710F";
BA_ "SeToolItemID_SIGNAL" SG_ 725 ESCReqESC_CtrlTrimMode_ISig_4 "x0000001D042A710F";
BA_ "SeToolName_SIGNAL" SG_ 725 ESCReqESC_CtrlTrimMode_ISig_4 "CtrlTrimMode";
BA_ "SeToolOwnerSigGroupID_SIGNAL" SG_ 725 ESCReqESC_CtrlTrimMode_ISig_4 "x0000001D043D5DD2";
BA_ "SeToolOwnerSigGroup_SIGNAL" SG_ 725 ESCReqESC_CtrlTrimMode_ISig_4 "ESCReqESC";
BA_ "SeToolVersion_SIGNAL" SG_ 725 ESCReqESC_CtrlTrimMode_ISig_4 "1";
BA_ "GenSigCycleTime" SG_ 725 ESCReqEMS_CtrlTrimStat_ISig_4 100;
BA_ "GenSigCycleTimeActive" SG_ 725 ESCReqEMS_CtrlTrimStat_ISig_4 100;
BA_ "GenSigStartValue" SG_ 725 ESCReqEMS_CtrlTrimStat_ISig_4 7;
BA_ "GenSigMaxLatency" SG_ 725 ESCReqEMS_CtrlTrimStat_ISig_4 56;
BA_ "Platform_VMCU1_Sig" SG_ 725 ESCReqEMS_CtrlTrimStat_ISig_4 1;
BA_ "SeToolAncestorID_SIGNAL" SG_ 725 ESCReqEMS_CtrlTrimStat_ISig_4 "x0000001D042A710D";
BA_ "SeToolItemID_SIGNAL" SG_ 725 ESCReqEMS_CtrlTrimStat_ISig_4 "x0000001D042A710D";
BA_ "SeToolName_SIGNAL" SG_ 725 ESCReqEMS_CtrlTrimStat_ISig_4 "CtrlTrimStat";
BA_ "SeToolOwnerSigGroupID_SIGNAL" SG_ 725 ESCReqEMS_CtrlTrimStat_ISig_4 "x0000001D043D5DDC";
BA_ "SeToolOwnerSigGroup_SIGNAL" SG_ 725 ESCReqEMS_CtrlTrimStat_ISig_4 "ESCReqEMS";
BA_ "SeToolVersion_SIGNAL" SG_ 725 ESCReqEMS_CtrlTrimStat_ISig_4 "1";
BA_ "GenSigCycleTime" SG_ 725 TrailerConnected_ISig_4 100;
BA_ "GenSigCycleTimeActive" SG_ 725 TrailerConnected_ISig_4 100;
BA_ "GenSigStartValue" SG_ 725 TrailerConnected_ISig_4 3;
BA_ "NeedsUpdateBit" SG_ 725 TrailerConnected_ISig_4 1;
BA_ "Platform_VMCU1_Sig" SG_ 725 TrailerConnected_ISig_4 1;
BA_ "GenSigCycleTime" SG_ 725 ESCReqESC_CtrlTrimValue_ISig_4 100;
BA_ "GenSigCycleTimeActive" SG_ 725 ESCReqESC_CtrlTrimValue_ISig_4 100;
BA_ "GenSigStartValue" SG_ 725 ESCReqESC_CtrlTrimValue_ISig_4 255;
BA_ "GenSigMaxLatency" SG_ 725 ESCReqESC_CtrlTrimValue_ISig_4 56;
BA_ "Platform_VMCU1_Sig" SG_ 725 ESCReqESC_CtrlTrimValue_ISig_4 1;
BA_ "SeToolAncestorID_SIGNAL" SG_ 725 ESCReqESC_CtrlTrimValue_ISig_4 "x0000001D042A7114";
BA_ "SeToolItemID_SIGNAL" SG_ 725 ESCReqESC_CtrlTrimValue_ISig_4 "x0000001D042A7114";
BA_ "SeToolName_SIGNAL" SG_ 725 ESCReqESC_CtrlTrimValue_ISig_4 "CtrlTrimValue";
BA_ "SeToolOwnerSigGroupID_SIGNAL" SG_ 725 ESCReqESC_CtrlTrimValue_ISig_4 "x0000001D043D5DD2";
BA_ "SeToolOwnerSigGroup_SIGNAL" SG_ 725 ESCReqESC_CtrlTrimValue_ISig_4 "ESCReqESC";
BA_ "SeToolVersion_SIGNAL" SG_ 725 ESCReqESC_CtrlTrimValue_ISig_4 "1";
BA_ "GenSigSendType" SG_ 725 BrakeLight_rqst_UB_ISig_4 7;
BA_ "Platform_VMCU1_Sig" SG_ 725 BrakeLight_rqst_UB_ISig_4 1;
BA_ "GenSigCycleTime" SG_ 725 ESCReqESC_CtrlTrimStat_ISig_4 100;
BA_ "GenSigCycleTimeActive" SG_ 725 ESCReqESC_CtrlTrimStat_ISig_4 100;
BA_ "GenSigStartValue" SG_ 725 ESCReqESC_CtrlTrimStat_ISig_4 7;
BA_ "GenSigMaxLatency" SG_ 725 ESCReqESC_CtrlTrimStat_ISig_4 56;
BA_ "Platform_VMCU1_Sig" SG_ 725 ESCReqESC_CtrlTrimStat_ISig_4 1;
BA_ "SeToolAncestorID_SIGNAL" SG_ 725 ESCReqESC_CtrlTrimStat_ISig_4 "x0000001D042A710D";
BA_ "SeToolItemID_SIGNAL" SG_ 725 ESCReqESC_CtrlTrimStat_ISig_4 "x0000001D042A710D";
BA_ "SeToolName_SIGNAL" SG_ 725 ESCReqESC_CtrlTrimStat_ISig_4 "CtrlTrimStat";
BA_ "SeToolOwnerSigGroupID_SIGNAL" SG_ 725 ESCReqESC_CtrlTrimStat_ISig_4 "x0000001D043D5DD2";
BA_ "SeToolOwnerSigGroup_SIGNAL" SG_ 725 ESCReqESC_CtrlTrimStat_ISig_4 "ESCReqESC";
BA_ "SeToolVersion_SIGNAL" SG_ 725 ESCReqESC_CtrlTrimStat_ISig_4 "1";
BA_ "GenSigCycleTime" SG_ 725 SCLLogicEnable_rqst 100;
BA_ "GenSigCycleTimeActive" SG_ 725 SCLLogicEnable_rqst 100;
BA_ "GenSigStartValue" SG_ 725 SCLLogicEnable_rqst 7;
BA_ "GenSigMaxLatency" SG_ 725 SCLLogicEnable_rqst 55;
BA_ "Platform_VMCU1_Sig" SG_ 725 SCLLogicEnable_rqst 1;
BA_ "SeToolAncestorID_SIGNAL" SG_ 725 SCLLogicEnable_rqst "x0000001D043B4FEF";
BA_ "SeToolItemID_SIGNAL" SG_ 725 SCLLogicEnable_rqst "x0000001D043FB671";
BA_ "SeToolName_SIGNAL" SG_ 725 SCLLogicEnable_rqst "SCLLogicEnable_rqst";
BA_ "SeToolVersion_SIGNAL" SG_ 725 SCLLogicEnable_rqst "2";
BA_ "GenSigCycleTime" SG_ 725 ESCReqESC_CtrlTrimReq_ISig_4 100;
BA_ "GenSigCycleTimeActive" SG_ 725 ESCReqESC_CtrlTrimReq_ISig_4 100;
BA_ "GenSigStartValue" SG_ 725 ESCReqESC_CtrlTrimReq_ISig_4 7;
BA_ "GenSigMaxLatency" SG_ 725 ESCReqESC_CtrlTrimReq_ISig_4 56;
BA_ "Platform_VMCU1_Sig" SG_ 725 ESCReqESC_CtrlTrimReq_ISig_4 1;
BA_ "SeToolAncestorID_SIGNAL" SG_ 725 ESCReqESC_CtrlTrimReq_ISig_4 "x0000001D042A710B";
BA_ "SeToolItemID_SIGNAL" SG_ 725 ESCReqESC_CtrlTrimReq_ISig_4 "x0000001D042A710B";
BA_ "SeToolName_SIGNAL" SG_ 725 ESCReqESC_CtrlTrimReq_ISig_4 "CtrlTrimReq";
BA_ "SeToolOwnerSigGroupID_SIGNAL" SG_ 725 ESCReqESC_CtrlTrimReq_ISig_4 "x0000001D043D5DD2";
BA_ "SeToolOwnerSigGroup_SIGNAL" SG_ 725 ESCReqESC_CtrlTrimReq_ISig_4 "ESCReqESC";
BA_ "SeToolVersion_SIGNAL" SG_ 725 ESCReqESC_CtrlTrimReq_ISig_4 "1";
BA_ "GenSigCycleTime" SG_ 725 BrakeLight_rqst_ISig_4 100;
BA_ "GenSigCycleTimeActive" SG_ 725 BrakeLight_rqst_ISig_4 100;
BA_ "GenSigStartValue" SG_ 725 BrakeLight_rqst_ISig_4 7;
BA_ "NeedsUpdateBit" SG_ 725 BrakeLight_rqst_ISig_4 1;
BA_ "Platform_VMCU1_Sig" SG_ 725 BrakeLight_rqst_ISig_4 1;
BA_ "GenSigCycleTime" SG_ 725 ESCReqEMS_CtrlTrimValue_ISig_4 100;
BA_ "GenSigCycleTimeActive" SG_ 725 ESCReqEMS_CtrlTrimValue_ISig_4 100;
BA_ "GenSigStartValue" SG_ 725 ESCReqEMS_CtrlTrimValue_ISig_4 255;
BA_ "GenSigMaxLatency" SG_ 725 ESCReqEMS_CtrlTrimValue_ISig_4 56;
BA_ "Platform_VMCU1_Sig" SG_ 725 ESCReqEMS_CtrlTrimValue_ISig_4 1;
BA_ "SeToolAncestorID_SIGNAL" SG_ 725 ESCReqEMS_CtrlTrimValue_ISig_4 "x0000001D042A7114";
BA_ "SeToolItemID_SIGNAL" SG_ 725 ESCReqEMS_CtrlTrimValue_ISig_4 "x0000001D042A7114";
BA_ "SeToolName_SIGNAL" SG_ 725 ESCReqEMS_CtrlTrimValue_ISig_4 "CtrlTrimValue";
BA_ "SeToolOwnerSigGroupID_SIGNAL" SG_ 725 ESCReqEMS_CtrlTrimValue_ISig_4 "x0000001D043D5DDC";
BA_ "SeToolOwnerSigGroup_SIGNAL" SG_ 725 ESCReqEMS_CtrlTrimValue_ISig_4 "ESCReqEMS";
BA_ "SeToolVersion_SIGNAL" SG_ 725 ESCReqEMS_CtrlTrimValue_ISig_4 "1";
BA_ "GenSigCycleTime" SG_ 725 ESCReqEMS_CtrlTrimReq_ISig_4 100;
BA_ "GenSigCycleTimeActive" SG_ 725 ESCReqEMS_CtrlTrimReq_ISig_4 100;
BA_ "GenSigStartValue" SG_ 725 ESCReqEMS_CtrlTrimReq_ISig_4 7;
BA_ "GenSigMaxLatency" SG_ 725 ESCReqEMS_CtrlTrimReq_ISig_4 56;
BA_ "Platform_VMCU1_Sig" SG_ 725 ESCReqEMS_CtrlTrimReq_ISig_4 1;
BA_ "SeToolAncestorID_SIGNAL" SG_ 725 ESCReqEMS_CtrlTrimReq_ISig_4 "x0000001D042A710B";
BA_ "SeToolItemID_SIGNAL" SG_ 725 ESCReqEMS_CtrlTrimReq_ISig_4 "x0000001D042A710B";
BA_ "SeToolName_SIGNAL" SG_ 725 ESCReqEMS_CtrlTrimReq_ISig_4 "CtrlTrimReq";
BA_ "SeToolOwnerSigGroupID_SIGNAL" SG_ 725 ESCReqEMS_CtrlTrimReq_ISig_4 "x0000001D043D5DDC";
BA_ "SeToolOwnerSigGroup_SIGNAL" SG_ 725 ESCReqEMS_CtrlTrimReq_ISig_4 "ESCReqEMS";
BA_ "SeToolVersion_SIGNAL" SG_ 725 ESCReqEMS_CtrlTrimReq_ISig_4 "1";
BA_ "GenSigCycleTime" SG_ 721 TrailerTest_stat 100;
BA_ "GenSigCycleTimeActive" SG_ 721 TrailerTest_stat 100;
BA_ "GenSigStartValue" SG_ 721 TrailerTest_stat 7;
BA_ "GenSigMaxLatency" SG_ 721 TrailerTest_stat 55;
BA_ "Platform_VMCU1_Sig" SG_ 721 TrailerTest_stat 1;
BA_ "SeToolAncestorID_SIGNAL" SG_ 721 TrailerTest_stat "x0000001D042E1ADE";
BA_ "SeToolItemID_SIGNAL" SG_ 721 TrailerTest_stat "x0000001D042E1ADE";
BA_ "SeToolName_SIGNAL" SG_ 721 TrailerTest_stat "TrailerTest_stat";
BA_ "SeToolVersion_SIGNAL" SG_ 721 TrailerTest_stat "1";
BA_ "GenSigCycleTime" SG_ 721 Washing_HMI_rqst_ISig_4 100;
BA_ "GenSigCycleTimeActive" SG_ 721 Washing_HMI_rqst_ISig_4 100;
BA_ "GenSigStartValue" SG_ 721 Washing_HMI_rqst_ISig_4 3;
BA_ "Platform_VMCU1_Sig" SG_ 721 Washing_HMI_rqst_ISig_4 1;
BA_ "GenSigCycleTime" SG_ 721 AuxBrakesDwngrdModeInd_rqst 100;
BA_ "GenSigCycleTimeActive" SG_ 721 AuxBrakesDwngrdModeInd_rqst 100;
BA_ "GenSigStartValue" SG_ 721 AuxBrakesDwngrdModeInd_rqst 7;
BA_ "GenSigMaxLatency" SG_ 721 AuxBrakesDwngrdModeInd_rqst 55;
BA_ "Platform_VMCU1_Sig" SG_ 721 AuxBrakesDwngrdModeInd_rqst 1;
BA_ "SeToolAncestorID_SIGNAL" SG_ 721 AuxBrakesDwngrdModeInd_rqst "x0000001D0414CED7";
BA_ "SeToolItemID_SIGNAL" SG_ 721 AuxBrakesDwngrdModeInd_rqst "x0000001D04327A04";
BA_ "SeToolName_SIGNAL" SG_ 721 AuxBrakesDwngrdModeInd_rqst "AuxBrakesDowngradedModeIndicationReq";
BA_ "SeToolVersion_SIGNAL" SG_ 721 AuxBrakesDwngrdModeInd_rqst "2";
BA_ "GenSigCycleTime" SG_ 721 XRSLTargetSpeedRequest 100;
BA_ "GenSigCycleTimeActive" SG_ 721 XRSLTargetSpeedRequest 100;
BA_ "GenSigStartValue" SG_ 721 XRSLTargetSpeedRequest 65535;
BA_ "Platform_FactoryIf_Sig" SG_ 721 XRSLTargetSpeedRequest 1;
BA_ "Platform_VMCU1_Sig" SG_ 721 XRSLTargetSpeedRequest 1;
BA_ "GenSigCycleTime" SG_ 721 DirInd_StalkStatus_1_ISig_4 100;
BA_ "GenSigCycleTimeActive" SG_ 721 DirInd_StalkStatus_1_ISig_4 100;
BA_ "GenSigStartValue" SG_ 721 DirInd_StalkStatus_1_ISig_4 7;
BA_ "SeToolAncestorID_SIGNAL" SG_ 721 DirInd_StalkStatus_1_ISig_4 "x0000001D04261502";
BA_ "SeToolItemID_SIGNAL" SG_ 721 DirInd_StalkStatus_1_ISig_4 "x0000001D043A8A48";
BA_ "SeToolName_SIGNAL" SG_ 721 DirInd_StalkStatus_1_ISig_4 "DirInd_StalkStatus_1";
BA_ "SeToolVersion_SIGNAL" SG_ 721 DirInd_StalkStatus_1_ISig_4 "3";
BA_ "GenSigCycleTime" SG_ 721 XPRsystemstate_ISig_4 100;
BA_ "GenSigCycleTimeActive" SG_ 721 XPRsystemstate_ISig_4 100;
BA_ "GenSigStartValue" SG_ 721 XPRsystemstate_ISig_4 255;
BA_ "Platform_VMCU1_Sig" SG_ 721 XPRsystemstate_ISig_4 1;
BA_ "GenSigCycleTime" SG_ 721 KeyAuthentication_rqst 100;
BA_ "GenSigCycleTimeActive" SG_ 721 KeyAuthentication_rqst 100;
BA_ "GenSigStartValue" SG_ 721 KeyAuthentication_rqst 7;
BA_ "Platform_VMCU1_Sig" SG_ 721 KeyAuthentication_rqst 1;
BA_ "GenSigCycleTime" SG_ 721 EngineSpeedControlStatus 100;
BA_ "GenSigCycleTimeActive" SG_ 721 EngineSpeedControlStatus 100;
BA_ "GenSigStartValue" SG_ 721 EngineSpeedControlStatus 7;
BA_ "GenSigMaxLatency" SG_ 721 EngineSpeedControlStatus 55;
BA_ "Platform_VMCU1_Sig" SG_ 721 EngineSpeedControlStatus 1;
BA_ "SeToolAncestorID_SIGNAL" SG_ 721 EngineSpeedControlStatus "x0000001D04154AB5";
BA_ "SeToolItemID_SIGNAL" SG_ 721 EngineSpeedControlStatus "x0000001D043DFB57";
BA_ "SeToolName_SIGNAL" SG_ 721 EngineSpeedControlStatus "EngineSpeedControlStatus";
BA_ "SeToolVersion_SIGNAL" SG_ 721 EngineSpeedControlStatus "2";
BA_ "GenSigCycleTime" SG_ 721 SecondThrottle 100;
BA_ "GenSigCycleTimeActive" SG_ 721 SecondThrottle 100;
BA_ "GenSigStartValue" SG_ 721 SecondThrottle 3;
BA_ "GenSigMaxLatency" SG_ 721 SecondThrottle 55;
BA_ "Platform_VMCU1_Sig" SG_ 721 SecondThrottle 1;
BA_ "SeToolAncestorID_SIGNAL" SG_ 721 SecondThrottle "x0000001D0425A500";
BA_ "SeToolItemID_SIGNAL" SG_ 721 SecondThrottle "x0000001D0425A500";
BA_ "SeToolName_SIGNAL" SG_ 721 SecondThrottle "SecondThrottle";
BA_ "SeToolVersion_SIGNAL" SG_ 721 SecondThrottle "1";
BA_ "GenSigCycleTime" SG_ 721 PredeliveryModeIndication_cmd_IS 100;
BA_ "GenSigCycleTimeActive" SG_ 721 PredeliveryModeIndication_cmd_IS 100;
BA_ "GenSigStartValue" SG_ 721 PredeliveryModeIndication_cmd_IS 3;
BA_ "Platform_VMCU1_Sig" SG_ 721 PredeliveryModeIndication_cmd_IS 1;
BA_ "SystemSignalLongSymbol" SG_ 721 PredeliveryModeIndication_cmd_IS "PredeliveryModeIndication_cmd_ISig_4";
BA_ "GenSigCycleTime" SG_ 721 LoadCutOffIndication_cmd_ISig_4 100;
BA_ "GenSigCycleTimeActive" SG_ 721 LoadCutOffIndication_cmd_ISig_4 100;
BA_ "GenSigStartValue" SG_ 721 LoadCutOffIndication_cmd_ISig_4 3;
BA_ "Platform_VMCU1_Sig" SG_ 721 LoadCutOffIndication_cmd_ISig_4 1;
BA_ "GenSigCycleTime" SG_ 721 ExitPreDeliveryModeHMI_rqst_ISig 100;
BA_ "GenSigCycleTimeActive" SG_ 721 ExitPreDeliveryModeHMI_rqst_ISig 100;
BA_ "GenSigStartValue" SG_ 721 ExitPreDeliveryModeHMI_rqst_ISig 3;
BA_ "Platform_VMCU1_Sig" SG_ 721 ExitPreDeliveryModeHMI_rqst_ISig 1;
BA_ "SystemSignalLongSymbol" SG_ 721 ExitPreDeliveryModeHMI_rqst_ISig "ExitPreDeliveryModeHMI_rqst_ISig_4";
BA_ "GenSigCycleTime" SG_ 721 FdEquipmentStatus1_ISig_4 100;
BA_ "GenSigCycleTimeActive" SG_ 721 FdEquipmentStatus1_ISig_4 100;
BA_ "GenSigStartValue" SG_ 721 FdEquipmentStatus1_ISig_4 3;
BA_ "GenSigMaxLatency" SG_ 721 FdEquipmentStatus1_ISig_4 55;
BA_ "Platform_VMCU1_Sig" SG_ 721 FdEquipmentStatus1_ISig_4 1;
BA_ "SeToolAncestorID_SIGNAL" SG_ 721 FdEquipmentStatus1_ISig_4 "x0000001D041709FA";
BA_ "SeToolItemID_SIGNAL" SG_ 721 FdEquipmentStatus1_ISig_4 "x0000001D041709FA";
BA_ "SeToolName_SIGNAL" SG_ 721 FdEquipmentStatus1_ISig_4 "FdEquipmentStatus1";
BA_ "SeToolVersion_SIGNAL" SG_ 721 FdEquipmentStatus1_ISig_4 "1";
BA_ "GenSigCycleTime" SG_ 534 ParkBrakeAlert_ISig_4 100;
BA_ "GenSigCycleTimeActive" SG_ 534 ParkBrakeAlert_ISig_4 100;
BA_ "GenSigStartValue" SG_ 534 ParkBrakeAlert_ISig_4 3;
BA_ "Platform_VMCU1_Sig" SG_ 534 ParkBrakeAlert_ISig_4 1;
BA_ "GenSigCycleTime" SG_ 534 IntLightMode_CoreRqst_IL_Mode 100;
BA_ "GenSigCycleTimeActive" SG_ 534 IntLightMode_CoreRqst_IL_Mode 100;
BA_ "GenSigStartValue" SG_ 534 IntLightMode_CoreRqst_IL_Mode 7;
BA_ "Platform_VMCU1_Sig" SG_ 534 IntLightMode_CoreRqst_IL_Mode 1;
BA_ "GenSigSendType" SG_ 534 WiperModeStatus_UB_ISig_4 7;
BA_ "Platform_VMCU1_Sig" SG_ 534 WiperModeStatus_UB_ISig_4 1;
BA_ "GenSigCycleTime" SG_ 534 SteeringColumnLockErrInd_rqst 100;
BA_ "GenSigCycleTimeActive" SG_ 534 SteeringColumnLockErrInd_rqst 100;
BA_ "GenSigStartValue" SG_ 534 SteeringColumnLockErrInd_rqst 7;
BA_ "GenSigMaxLatency" SG_ 534 SteeringColumnLockErrInd_rqst 29;
BA_ "Platform_VMCU1_Sig" SG_ 534 SteeringColumnLockErrInd_rqst 1;
BA_ "SeToolAncestorID_SIGNAL" SG_ 534 SteeringColumnLockErrInd_rqst "x0000001D0419C337";
BA_ "SeToolItemID_SIGNAL" SG_ 534 SteeringColumnLockErrInd_rqst "x0000001D0419C337";
BA_ "SeToolName_SIGNAL" SG_ 534 SteeringColumnLockErrInd_rqst "SteeringColumnLockErrorIndication_rqst";
BA_ "SeToolVersion_SIGNAL" SG_ 534 SteeringColumnLockErrInd_rqst "1";
BA_ "GenSigCycleTime" SG_ 534 ParkingLight_Indication 100;
BA_ "GenSigCycleTimeActive" SG_ 534 ParkingLight_Indication 100;
BA_ "GenSigStartValue" SG_ 534 ParkingLight_Indication 3;
BA_ "GenSigMaxLatency" SG_ 534 ParkingLight_Indication 29;
BA_ "Platform_VMCU1_Sig" SG_ 534 ParkingLight_Indication 1;
BA_ "SeToolAncestorID_SIGNAL" SG_ 534 ParkingLight_Indication "x0000001D041A7C03";
BA_ "SeToolItemID_SIGNAL" SG_ 534 ParkingLight_Indication "x0000001D043C4080";
BA_ "SeToolName_SIGNAL" SG_ 534 ParkingLight_Indication "ParkingLight_Indication";
BA_ "SeToolVersion_SIGNAL" SG_ 534 ParkingLight_Indication "3";
BA_ "GenSigCycleTime" SG_ 534 DaytimeRunningLight_Indication 100;
BA_ "GenSigCycleTimeActive" SG_ 534 DaytimeRunningLight_Indication 100;
BA_ "GenSigStartValue" SG_ 534 DaytimeRunningLight_Indication 3;
BA_ "GenSigMaxLatency" SG_ 534 DaytimeRunningLight_Indication 29;
BA_ "Platform_VMCU1_Sig" SG_ 534 DaytimeRunningLight_Indication 1;
BA_ "SeToolAncestorID_SIGNAL" SG_ 534 DaytimeRunningLight_Indication "x0000001D041A7C03";
BA_ "SeToolItemID_SIGNAL" SG_ 534 DaytimeRunningLight_Indication "x0000001D043C4080";
BA_ "SeToolName_SIGNAL" SG_ 534 DaytimeRunningLight_Indication "DaytimeRunningLight_Indication";
BA_ "SeToolVersion_SIGNAL" SG_ 534 DaytimeRunningLight_Indication "3";
BA_ "GenSigCycleTime" SG_ 534 EPBBackupMode_ISig_4 100;
BA_ "GenSigCycleTimeActive" SG_ 534 EPBBackupMode_ISig_4 100;
BA_ "GenSigStartValue" SG_ 534 EPBBackupMode_ISig_4 15;
BA_ "Platform_VMCU1_Sig" SG_ 534 EPBBackupMode_ISig_4 1;
BA_ "GenSigCycleTime" SG_ 534 WiperModeStatus_ISig_4 100;
BA_ "GenSigCycleTimeActive" SG_ 534 WiperModeStatus_ISig_4 100;
BA_ "GenSigStartValue" SG_ 534 WiperModeStatus_ISig_4 7;
BA_ "GenSigMaxLatency" SG_ 534 WiperModeStatus_ISig_4 29;
BA_ "NeedsUpdateBit" SG_ 534 WiperModeStatus_ISig_4 1;
BA_ "Platform_VMCU1_Sig" SG_ 534 WiperModeStatus_ISig_4 1;
BA_ "SeToolAncestorID_SIGNAL" SG_ 534 WiperModeStatus_ISig_4 "x0000001D0410D271";
BA_ "SeToolItemID_SIGNAL" SG_ 534 WiperModeStatus_ISig_4 "x0000001D0410D271";
BA_ "SeToolName_SIGNAL" SG_ 534 WiperModeStatus_ISig_4 "WiperModeStatus";
BA_ "SeToolVersion_SIGNAL" SG_ 534 WiperModeStatus_ISig_4 "1";
BA_ "GenSigCycleTime" SG_ 534 FrontFog_Indication_ISig_4 100;
BA_ "GenSigCycleTimeActive" SG_ 534 FrontFog_Indication_ISig_4 100;
BA_ "GenSigStartValue" SG_ 534 FrontFog_Indication_ISig_4 3;
BA_ "GenSigMaxLatency" SG_ 534 FrontFog_Indication_ISig_4 29;
BA_ "Platform_VMCU1_Sig" SG_ 534 FrontFog_Indication_ISig_4 1;
BA_ "SeToolAncestorID_SIGNAL" SG_ 534 FrontFog_Indication_ISig_4 "x0000001D041A7C03";
BA_ "SeToolItemID_SIGNAL" SG_ 534 FrontFog_Indication_ISig_4 "x0000001D043C4080";
BA_ "SeToolName_SIGNAL" SG_ 534 FrontFog_Indication_ISig_4 "FrontFog_Indication";
BA_ "SeToolVersion_SIGNAL" SG_ 534 FrontFog_Indication_ISig_4 "3";
BA_ "GenSigCycleTime" SG_ 534 PBReleaseAcceptance_stat_ISig_4 100;
BA_ "GenSigCycleTimeActive" SG_ 534 PBReleaseAcceptance_stat_ISig_4 100;
BA_ "GenSigStartValue" SG_ 534 PBReleaseAcceptance_stat_ISig_4 7;
BA_ "Platform_VMCU1_Sig" SG_ 534 PBReleaseAcceptance_stat_ISig_4 1;
BA_ "GenSigSendType" SG_ 534 ParkingBrake_stat_UB_ISig_4 7;
BA_ "Platform_VMCU1_Sig" SG_ 534 ParkingBrake_stat_UB_ISig_4 1;
BA_ "GenSigCycleTime" SG_ 534 DrivingLightPlus_Indication 100;
BA_ "GenSigCycleTimeActive" SG_ 534 DrivingLightPlus_Indication 100;
BA_ "GenSigStartValue" SG_ 534 DrivingLightPlus_Indication 3;
BA_ "GenSigMaxLatency" SG_ 534 DrivingLightPlus_Indication 29;
BA_ "Platform_VMCU1_Sig" SG_ 534 DrivingLightPlus_Indication 1;
BA_ "SeToolAncestorID_SIGNAL" SG_ 534 DrivingLightPlus_Indication "x0000001D041A7C03";
BA_ "SeToolItemID_SIGNAL" SG_ 534 DrivingLightPlus_Indication "x0000001D043C4080";
BA_ "SeToolName_SIGNAL" SG_ 534 DrivingLightPlus_Indication "DrivingLightPlus_Indication";
BA_ "SeToolVersion_SIGNAL" SG_ 534 DrivingLightPlus_Indication "3";
BA_ "GenSigCycleTime" SG_ 534 IntLightMode_CoreRqst_EventFlag 100;
BA_ "GenSigCycleTimeActive" SG_ 534 IntLightMode_CoreRqst_EventFlag 100;
BA_ "Platform_VMCU1_Sig" SG_ 534 IntLightMode_CoreRqst_EventFlag 1;
BA_ "GenSigCycleTime" SG_ 534 ParkingBrake_stat_ISig_4 100;
BA_ "GenSigCycleTimeActive" SG_ 534 ParkingBrake_stat_ISig_4 100;
BA_ "GenSigStartValue" SG_ 534 ParkingBrake_stat_ISig_4 3;
BA_ "NeedsUpdateBit" SG_ 534 ParkingBrake_stat_ISig_4 1;
BA_ "Platform_VMCU1_Sig" SG_ 534 ParkingBrake_stat_ISig_4 1;
BA_ "GenSigCycleTime" SG_ 534 DrivingLight_Indication 100;
BA_ "GenSigCycleTimeActive" SG_ 534 DrivingLight_Indication 100;
BA_ "GenSigStartValue" SG_ 534 DrivingLight_Indication 3;
BA_ "GenSigMaxLatency" SG_ 534 DrivingLight_Indication 29;
BA_ "Platform_VMCU1_Sig" SG_ 534 DrivingLight_Indication 1;
BA_ "SeToolAncestorID_SIGNAL" SG_ 534 DrivingLight_Indication "x0000001D041A7C03";
BA_ "SeToolItemID_SIGNAL" SG_ 534 DrivingLight_Indication "x0000001D043C4080";
BA_ "SeToolName_SIGNAL" SG_ 534 DrivingLight_Indication "DrivingLight_Indication";
BA_ "SeToolVersion_SIGNAL" SG_ 534 DrivingLight_Indication "3";
BA_ "GenSigCycleTime" SG_ 534 MirrorHeatingMode_ISig_4 100;
BA_ "GenSigCycleTimeActive" SG_ 534 MirrorHeatingMode_ISig_4 100;
BA_ "GenSigStartValue" SG_ 534 MirrorHeatingMode_ISig_4 7;
BA_ "GenSigMaxLatency" SG_ 534 MirrorHeatingMode_ISig_4 29;
BA_ "Platform_VMCU1_Sig" SG_ 534 MirrorHeatingMode_ISig_4 1;
BA_ "SeToolAncestorID_SIGNAL" SG_ 534 MirrorHeatingMode_ISig_4 "x0000001D0412C1DB";
BA_ "SeToolItemID_SIGNAL" SG_ 534 MirrorHeatingMode_ISig_4 "x0000001D0412C1DB";
BA_ "SeToolName_SIGNAL" SG_ 534 MirrorHeatingMode_ISig_4 "MirrorHeatingMode";
BA_ "SeToolVersion_SIGNAL" SG_ 534 MirrorHeatingMode_ISig_4 "1";
BA_ "GenSigCycleTime" SG_ 534 RearFog_Indication 100;
BA_ "GenSigCycleTimeActive" SG_ 534 RearFog_Indication 100;
BA_ "GenSigStartValue" SG_ 534 RearFog_Indication 3;
BA_ "GenSigMaxLatency" SG_ 534 RearFog_Indication 29;
BA_ "Platform_VMCU1_Sig" SG_ 534 RearFog_Indication 1;
BA_ "SeToolAncestorID_SIGNAL" SG_ 534 RearFog_Indication "x0000001D041A7C03";
BA_ "SeToolItemID_SIGNAL" SG_ 534 RearFog_Indication "x0000001D043C4080";
BA_ "SeToolName_SIGNAL" SG_ 534 RearFog_Indication "RearFog_Indication";
BA_ "SeToolVersion_SIGNAL" SG_ 534 RearFog_Indication "3";
BA_ "GenSigCycleTime" SG_ 534 InteriorLightLevelInd_cmd 100;
BA_ "GenSigCycleTimeActive" SG_ 534 InteriorLightLevelInd_cmd 100;
BA_ "GenSigStartValue" SG_ 534 InteriorLightLevelInd_cmd 255;
BA_ "Platform_VMCU1_Sig" SG_ 534 InteriorLightLevelInd_cmd 1;
BA_ "GenSigSendType" SG_ 532 LevelControlInformation_UB_ISig_ 7;
BA_ "Platform_VMCU1_Sig" SG_ 532 LevelControlInformation_UB_ISig_ 1;
BA_ "SystemSignalLongSymbol" SG_ 532 LevelControlInformation_UB_ISig_ "LevelControlInformation_UB_ISig_4";
BA_ "GenSigCycleTime" SG_ 532 LiftAxle2LiftFuncSelected_ISig_4 100;
BA_ "GenSigCycleTimeActive" SG_ 532 LiftAxle2LiftFuncSelected_ISig_4 100;
BA_ "GenSigStartValue" SG_ 532 LiftAxle2LiftFuncSelected_ISig_4 7;
BA_ "SeToolAncestorID_SIGNAL" SG_ 532 LiftAxle2LiftFuncSelected_ISig_4 "x0000001D04134C4B";
BA_ "SeToolItemID_SIGNAL" SG_ 532 LiftAxle2LiftFuncSelected_ISig_4 "x0000001D04134C4B";
BA_ "SeToolName_SIGNAL" SG_ 532 LiftAxle2LiftFuncSelected_ISig_4 "LiftAxle2LiftAutoFunctionSelected";
BA_ "SeToolVersion_SIGNAL" SG_ 532 LiftAxle2LiftFuncSelected_ISig_4 "1";
BA_ "GenSigCycleTime" SG_ 532 StopLevelChangeAck_ISig_4 100;
BA_ "GenSigCycleTimeActive" SG_ 532 StopLevelChangeAck_ISig_4 100;
BA_ "GenSigStartValue" SG_ 532 StopLevelChangeAck_ISig_4 3;
BA_ "GenSigMaxLatency" SG_ 532 StopLevelChangeAck_ISig_4 28;
BA_ "Platform_VMCU1_Sig" SG_ 532 StopLevelChangeAck_ISig_4 1;
BA_ "SeToolAncestorID_SIGNAL" SG_ 532 StopLevelChangeAck_ISig_4 "x0000001D0412ECBE";
BA_ "SeToolItemID_SIGNAL" SG_ 532 StopLevelChangeAck_ISig_4 "x0000001D0412ECBE";
BA_ "SeToolName_SIGNAL" SG_ 532 StopLevelChangeAck_ISig_4 "StopLevelChangeAck";
BA_ "SeToolVersion_SIGNAL" SG_ 532 StopLevelChangeAck_ISig_4 "1";
BA_ "GenSigCycleTime" SG_ 532 HeightAdjustmentAllowed_ISig_4 100;
BA_ "GenSigCycleTimeActive" SG_ 532 HeightAdjustmentAllowed_ISig_4 100;
BA_ "GenSigStartValue" SG_ 532 HeightAdjustmentAllowed_ISig_4 3;
BA_ "Platform_VMCU1_Sig" SG_ 532 HeightAdjustmentAllowed_ISig_4 1;
BA_ "GenSigCycleTime" SG_ 532 LiftAxle2LowerACK_ISig_4 100;
BA_ "GenSigCycleTimeActive" SG_ 532 LiftAxle2LowerACK_ISig_4 100;
BA_ "GenSigStartValue" SG_ 532 LiftAxle2LowerACK_ISig_4 7;
BA_ "GenSigCycleTime" SG_ 532 LiftAxle2UpRequestACK_ISig_4 100;
BA_ "GenSigCycleTimeActive" SG_ 532 LiftAxle2UpRequestACK_ISig_4 100;
BA_ "GenSigStartValue" SG_ 532 LiftAxle2UpRequestACK_ISig_4 7;
BA_ "GenSigMaxLatency" SG_ 532 LiftAxle2UpRequestACK_ISig_4 28;
BA_ "Platform_VMCU1_Sig" SG_ 532 LiftAxle2UpRequestACK_ISig_4 1;
BA_ "SeToolAncestorID_SIGNAL" SG_ 532 LiftAxle2UpRequestACK_ISig_4 "x0000001D043E0E16";
BA_ "SeToolItemID_SIGNAL" SG_ 532 LiftAxle2UpRequestACK_ISig_4 "x0000001D043E0E16";
BA_ "SeToolName_SIGNAL" SG_ 532 LiftAxle2UpRequestACK_ISig_4 "LiftAxle2UpRequestACK";
BA_ "SeToolVersion_SIGNAL" SG_ 532 LiftAxle2UpRequestACK_ISig_4 "1";
BA_ "GenSigCycleTime" SG_ 532 RideHeightStatus_ISig_4 100;
BA_ "GenSigCycleTimeActive" SG_ 532 RideHeightStatus_ISig_4 100;
BA_ "GenSigStartValue" SG_ 532 RideHeightStatus_ISig_4 15;
BA_ "GenSigMaxLatency" SG_ 532 RideHeightStatus_ISig_4 28;
BA_ "Platform_VMCU1_Sig" SG_ 532 RideHeightStatus_ISig_4 1;
BA_ "SeToolAncestorID_SIGNAL" SG_ 532 RideHeightStatus_ISig_4 "x0000001D041304DF";
BA_ "SeToolItemID_SIGNAL" SG_ 532 RideHeightStatus_ISig_4 "x0000001D0442415B";
BA_ "SeToolName_SIGNAL" SG_ 532 RideHeightStatus_ISig_4 "RideHeightStatus";
BA_ "SeToolVersion_SIGNAL" SG_ 532 RideHeightStatus_ISig_4 "3";
BA_ "GenSigCycleTime" SG_ 532 RideHeightOutsideTargetRange_ISi 100;
BA_ "GenSigCycleTimeActive" SG_ 532 RideHeightOutsideTargetRange_ISi 100;
BA_ "GenSigStartValue" SG_ 532 RideHeightOutsideTargetRange_ISi 7;
BA_ "GenSigMaxLatency" SG_ 532 RideHeightOutsideTargetRange_ISi 28;
BA_ "Platform_VMCU1_Sig" SG_ 532 RideHeightOutsideTargetRange_ISi 1;
BA_ "SeToolAncestorID_SIGNAL" SG_ 532 RideHeightOutsideTargetRange_ISi "x0000001D041F15D9";
BA_ "SeToolItemID_SIGNAL" SG_ 532 RideHeightOutsideTargetRange_ISi "x0000001D041F15D9";
BA_ "SeToolName_SIGNAL" SG_ 532 RideHeightOutsideTargetRange_ISi "RideHeightOutsideTargetRange";
BA_ "SeToolVersion_SIGNAL" SG_ 532 RideHeightOutsideTargetRange_ISi "1";
BA_ "SystemSignalLongSymbol" SG_ 532 RideHeightOutsideTargetRange_ISi "RideHeightOutsideTargetRange_ISig_4";
BA_ "GenSigCycleTime" SG_ 532 LoadDistributionFuncSelected_ISi 100;
BA_ "GenSigCycleTimeActive" SG_ 532 LoadDistributionFuncSelected_ISi 100;
BA_ "GenSigStartValue" SG_ 532 LoadDistributionFuncSelected_ISi 15;
BA_ "GenSigMaxLatency" SG_ 532 LoadDistributionFuncSelected_ISi 28;
BA_ "Platform_VMCU1_Sig" SG_ 532 LoadDistributionFuncSelected_ISi 1;
BA_ "SeToolAncestorID_SIGNAL" SG_ 532 LoadDistributionFuncSelected_ISi "x0000001D04355313";
BA_ "SeToolItemID_SIGNAL" SG_ 532 LoadDistributionFuncSelected_ISi "x0000001D043AB18A";
BA_ "SeToolName_SIGNAL" SG_ 532 LoadDistributionFuncSelected_ISi "LoadDistributionRequested";
BA_ "SeToolVersion_SIGNAL" SG_ 532 LoadDistributionFuncSelected_ISi "2";
BA_ "SystemSignalLongSymbol" SG_ 532 LoadDistributionFuncSelected_ISi "LoadDistributionFuncSelected_ISig_4";
BA_ "GenSigCycleTime" SG_ 532 RideHeightStorageAck_ISig_4 100;
BA_ "GenSigCycleTimeActive" SG_ 532 RideHeightStorageAck_ISig_4 100;
BA_ "GenSigStartValue" SG_ 532 RideHeightStorageAck_ISig_4 3;
BA_ "GenSigMaxLatency" SG_ 532 RideHeightStorageAck_ISig_4 28;
BA_ "Platform_VMCU1_Sig" SG_ 532 RideHeightStorageAck_ISig_4 1;
BA_ "SeToolAncestorID_SIGNAL" SG_ 532 RideHeightStorageAck_ISig_4 "x0000001D0421D044";
BA_ "SeToolItemID_SIGNAL" SG_ 532 RideHeightStorageAck_ISig_4 "x0000001D0421D044";
BA_ "SeToolName_SIGNAL" SG_ 532 RideHeightStorageAck_ISig_4 "RideHeightStorageAck";
BA_ "SeToolVersion_SIGNAL" SG_ 532 RideHeightStorageAck_ISig_4 "1";
BA_ "GenSigCycleTime" SG_ 532 LiftAxle2AutoLiftSelected_ISig_4 100;
BA_ "GenSigCycleTimeActive" SG_ 532 LiftAxle2AutoLiftSelected_ISig_4 100;
BA_ "GenSigStartValue" SG_ 532 LiftAxle2AutoLiftSelected_ISig_4 3;
BA_ "GenSigCycleTime" SG_ 532 LiftAxle1UpRequestACK_ISig_4 100;
BA_ "GenSigCycleTimeActive" SG_ 532 LiftAxle1UpRequestACK_ISig_4 100;
BA_ "GenSigStartValue" SG_ 532 LiftAxle1UpRequestACK_ISig_4 7;
BA_ "GenSigMaxLatency" SG_ 532 LiftAxle1UpRequestACK_ISig_4 28;
BA_ "Platform_VMCU1_Sig" SG_ 532 LiftAxle1UpRequestACK_ISig_4 1;
BA_ "SeToolAncestorID_SIGNAL" SG_ 532 LiftAxle1UpRequestACK_ISig_4 "x0000001D043E0DFD";
BA_ "SeToolItemID_SIGNAL" SG_ 532 LiftAxle1UpRequestACK_ISig_4 "x0000001D043E0DFD";
BA_ "SeToolName_SIGNAL" SG_ 532 LiftAxle1UpRequestACK_ISig_4 "LiftAxle1UpRequestACK";
BA_ "SeToolVersion_SIGNAL" SG_ 532 LiftAxle1UpRequestACK_ISig_4 "1";
BA_ "GenSigCycleTime" SG_ 532 LiftAxle1PositionStatus_ISig_4 100;
BA_ "GenSigCycleTimeActive" SG_ 532 LiftAxle1PositionStatus_ISig_4 100;
BA_ "GenSigStartValue" SG_ 532 LiftAxle1PositionStatus_ISig_4 7;
BA_ "GenSigMaxLatency" SG_ 532 LiftAxle1PositionStatus_ISig_4 28;
BA_ "Platform_VMCU1_Sig" SG_ 532 LiftAxle1PositionStatus_ISig_4 1;
BA_ "SeToolAncestorID_SIGNAL" SG_ 532 LiftAxle1PositionStatus_ISig_4 "x0000001D04131A08";
BA_ "SeToolItemID_SIGNAL" SG_ 532 LiftAxle1PositionStatus_ISig_4 "x0000001D0423C412";
BA_ "SeToolName_SIGNAL" SG_ 532 LiftAxle1PositionStatus_ISig_4 "LiftAxle1PositionStatus";
BA_ "SeToolVersion_SIGNAL" SG_ 532 LiftAxle1PositionStatus_ISig_4 "2";
BA_ "GenSigCycleTime" SG_ 532 LiftAxle1LowerACK_ISig_4 100;
BA_ "GenSigCycleTimeActive" SG_ 532 LiftAxle1LowerACK_ISig_4 100;
BA_ "GenSigStartValue" SG_ 532 LiftAxle1LowerACK_ISig_4 7;
BA_ "GenSigCycleTime" SG_ 532 LiftAxle1AutoLiftSelected_ISig_4 100;
BA_ "GenSigCycleTimeActive" SG_ 532 LiftAxle1AutoLiftSelected_ISig_4 100;
BA_ "GenSigStartValue" SG_ 532 LiftAxle1AutoLiftSelected_ISig_4 3;
BA_ "GenSigCycleTime" SG_ 532 LiftAxle2PositionStatus_ISig_4 100;
BA_ "GenSigCycleTimeActive" SG_ 532 LiftAxle2PositionStatus_ISig_4 100;
BA_ "GenSigStartValue" SG_ 532 LiftAxle2PositionStatus_ISig_4 7;
BA_ "GenSigMaxLatency" SG_ 532 LiftAxle2PositionStatus_ISig_4 28;
BA_ "Platform_VMCU1_Sig" SG_ 532 LiftAxle2PositionStatus_ISig_4 1;
BA_ "SeToolAncestorID_SIGNAL" SG_ 532 LiftAxle2PositionStatus_ISig_4 "x0000001D04131A0A";
BA_ "SeToolItemID_SIGNAL" SG_ 532 LiftAxle2PositionStatus_ISig_4 "x0000001D04295880";
BA_ "SeToolName_SIGNAL" SG_ 532 LiftAxle2PositionStatus_ISig_4 "LiftAxle2PositionStatus";
BA_ "SeToolVersion_SIGNAL" SG_ 532 LiftAxle2PositionStatus_ISig_4 "3";
BA_ "GenSigCycleTime" SG_ 532 LevelControlInformation_ISig_4 100;
BA_ "GenSigCycleTimeActive" SG_ 532 LevelControlInformation_ISig_4 100;
BA_ "GenSigStartValue" SG_ 532 LevelControlInformation_ISig_4 15;
BA_ "GenSigMaxLatency" SG_ 532 LevelControlInformation_ISig_4 28;
BA_ "NeedsUpdateBit" SG_ 532 LevelControlInformation_ISig_4 1;
BA_ "Platform_VMCU1_Sig" SG_ 532 LevelControlInformation_ISig_4 1;
BA_ "SeToolAncestorID_SIGNAL" SG_ 532 LevelControlInformation_ISig_4 "x0000001D04290369";
BA_ "SeToolItemID_SIGNAL" SG_ 532 LevelControlInformation_ISig_4 "x0000001D04290369";
BA_ "SeToolName_SIGNAL" SG_ 532 LevelControlInformation_ISig_4 "LevelControlInformation";
BA_ "SeToolVersion_SIGNAL" SG_ 532 LevelControlInformation_ISig_4 "1";
BA_ "GenSigCycleTime" SG_ 532 LiftAxle1LiftFuncSelected_ISig_4 100;
BA_ "GenSigCycleTimeActive" SG_ 532 LiftAxle1LiftFuncSelected_ISig_4 100;
BA_ "GenSigStartValue" SG_ 532 LiftAxle1LiftFuncSelected_ISig_4 7;
BA_ "SeToolAncestorID_SIGNAL" SG_ 532 LiftAxle1LiftFuncSelected_ISig_4 "x0000001D04134C43";
BA_ "SeToolItemID_SIGNAL" SG_ 532 LiftAxle1LiftFuncSelected_ISig_4 "x0000001D04134C43";
BA_ "SeToolName_SIGNAL" SG_ 532 LiftAxle1LiftFuncSelected_ISig_4 "LiftAxle1LiftAutoFunctionSelected";
BA_ "SeToolVersion_SIGNAL" SG_ 532 LiftAxle1LiftFuncSelected_ISig_4 "1";
BA_ "GenSigCycleTime" SG_ 532 LoadDistributionChangeACK_ISig_4 100;
BA_ "GenSigCycleTimeActive" SG_ 532 LoadDistributionChangeACK_ISig_4 100;
BA_ "GenSigStartValue" SG_ 532 LoadDistributionChangeACK_ISig_4 7;
BA_ "GenSigMaxLatency" SG_ 532 LoadDistributionChangeACK_ISig_4 28;
BA_ "Platform_VMCU1_Sig" SG_ 532 LoadDistributionChangeACK_ISig_4 1;
BA_ "SeToolAncestorID_SIGNAL" SG_ 532 LoadDistributionChangeACK_ISig_4 "x0000001D04176D2D";
BA_ "SeToolItemID_SIGNAL" SG_ 532 LoadDistributionChangeACK_ISig_4 "x0000001D0440C942";
BA_ "SeToolName_SIGNAL" SG_ 532 LoadDistributionChangeACK_ISig_4 "LoadDistributionChangeAck";
BA_ "SeToolVersion_SIGNAL" SG_ 532 LoadDistributionChangeACK_ISig_4 "2";
BA_ "GenSigCycleTime" SG_ 532 RampLevelStorageAck_ISig_4 100;
BA_ "GenSigCycleTimeActive" SG_ 532 RampLevelStorageAck_ISig_4 100;
BA_ "GenSigStartValue" SG_ 532 RampLevelStorageAck_ISig_4 3;
BA_ "GenSigMaxLatency" SG_ 532 RampLevelStorageAck_ISig_4 28;
BA_ "Platform_VMCU1_Sig" SG_ 532 RampLevelStorageAck_ISig_4 1;
BA_ "SeToolAncestorID_SIGNAL" SG_ 532 RampLevelStorageAck_ISig_4 "x0000001D0421FE10";
BA_ "SeToolItemID_SIGNAL" SG_ 532 RampLevelStorageAck_ISig_4 "x0000001D0421FE10";
BA_ "SeToolName_SIGNAL" SG_ 532 RampLevelStorageAck_ISig_4 "RampLevelStorageAck";
BA_ "SeToolVersion_SIGNAL" SG_ 532 RampLevelStorageAck_ISig_4 "1";
BA_ "GenSigCycleTime" SG_ 532 LoadDistributionSelected_ISig_4 100;
BA_ "GenSigCycleTimeActive" SG_ 532 LoadDistributionSelected_ISig_4 100;
BA_ "GenSigStartValue" SG_ 532 LoadDistributionSelected_ISig_4 15;
BA_ "GenSigMaxLatency" SG_ 532 LoadDistributionSelected_ISig_4 112;
BA_ "Platform_VMCU1_Sig" SG_ 532 LoadDistributionSelected_ISig_4 1;
BA_ "GenSigCycleTime" SG_ 532 RideHeightFunctionStatus_ISig_4 100;
BA_ "GenSigCycleTimeActive" SG_ 532 RideHeightFunctionStatus_ISig_4 100;
BA_ "GenSigStartValue" SG_ 532 RideHeightFunctionStatus_ISig_4 15;
BA_ "GenSigMaxLatency" SG_ 532 RideHeightFunctionStatus_ISig_4 28;
BA_ "Platform_VMCU1_Sig" SG_ 532 RideHeightFunctionStatus_ISig_4 1;
BA_ "SeToolAncestorID_SIGNAL" SG_ 532 RideHeightFunctionStatus_ISig_4 "x0000001D042186C7";
BA_ "SeToolItemID_SIGNAL" SG_ 532 RideHeightFunctionStatus_ISig_4 "x0000001D043FB877";
BA_ "SeToolName_SIGNAL" SG_ 532 RideHeightFunctionStatus_ISig_4 "RideHeightFunctionStatus";
BA_ "SeToolVersion_SIGNAL" SG_ 532 RideHeightFunctionStatus_ISig_4 "2";
BA_ "GenSigSendType" SG_ 520 GearSplit_Status_UB_ISig_4 7;
BA_ "Platform_VMCU1_Sig" SG_ 520 GearSplit_Status_UB_ISig_4 1;
BA_ "GenSigCycleTime" SG_ 520 TransmLowRangeSenseSwitch_ISig_4 100;
BA_ "GenSigCycleTimeActive" SG_ 520 TransmLowRangeSenseSwitch_ISig_4 100;
BA_ "GenSigStartValue" SG_ 520 TransmLowRangeSenseSwitch_ISig_4 3;
BA_ "Platform_VMCU1_Sig" SG_ 520 TransmLowRangeSenseSwitch_ISig_4 1;
BA_ "GenSigCycleTime" SG_ 520 TransmSystemPowerDown_rqst 100;
BA_ "GenSigCycleTimeActive" SG_ 520 TransmSystemPowerDown_rqst 100;
BA_ "GenSigStartValue" SG_ 520 TransmSystemPowerDown_rqst 3;
BA_ "GenSigMaxLatency" SG_ 520 TransmSystemPowerDown_rqst 26;
BA_ "NeedsUpdateBit" SG_ 520 TransmSystemPowerDown_rqst 1;
BA_ "Platform_VMCU1_Sig" SG_ 520 TransmSystemPowerDown_rqst 1;
BA_ "SeToolAncestorID_SIGNAL" SG_ 520 TransmSystemPowerDown_rqst "x0000001D0437CB03";
BA_ "SeToolItemID_SIGNAL" SG_ 520 TransmSystemPowerDown_rqst "x0000001D0437CB03";
BA_ "SeToolName_SIGNAL" SG_ 520 TransmSystemPowerDown_rqst "TransmissionSystemPowerDownRequest";
BA_ "SeToolVersion_SIGNAL" SG_ 520 TransmSystemPowerDown_rqst "1";
BA_ "GenSigCycleTime" SG_ 520 TransmissionNeutralSwitch_ISig_4 100;
BA_ "GenSigCycleTimeActive" SG_ 520 TransmissionNeutralSwitch_ISig_4 100;
BA_ "GenSigStartValue" SG_ 520 TransmissionNeutralSwitch_ISig_4 3;
BA_ "GenSigMaxLatency" SG_ 520 TransmissionNeutralSwitch_ISig_4 26;
BA_ "NeedsUpdateBit" SG_ 520 TransmissionNeutralSwitch_ISig_4 1;
BA_ "Platform_VMCU1_Sig" SG_ 520 TransmissionNeutralSwitch_ISig_4 1;
BA_ "SeToolAncestorID_SIGNAL" SG_ 520 TransmissionNeutralSwitch_ISig_4 "x0000001D0412E2B6";
BA_ "SeToolItemID_SIGNAL" SG_ 520 TransmissionNeutralSwitch_ISig_4 "x0000001D042FD0C5";
BA_ "SeToolName_SIGNAL" SG_ 520 TransmissionNeutralSwitch_ISig_4 "TransmissionNeutralSwitch";
BA_ "SeToolVersion_SIGNAL" SG_ 520 TransmissionNeutralSwitch_ISig_4 "2";
BA_ "GenSigCycleTime" SG_ 520 SecuredNeutralPosition_ISig_4 100;
BA_ "GenSigCycleTimeActive" SG_ 520 SecuredNeutralPosition_ISig_4 100;
BA_ "GenSigStartValue" SG_ 520 SecuredNeutralPosition_ISig_4 3;
BA_ "NeedsUpdateBit" SG_ 520 SecuredNeutralPosition_ISig_4 1;
BA_ "Platform_FactoryIf_Sig" SG_ 520 SecuredNeutralPosition_ISig_4 1;
BA_ "Platform_VMCU1_Sig" SG_ 520 SecuredNeutralPosition_ISig_4 1;
BA_ "SeToolAncestorID_SIGNAL" SG_ 520 SecuredNeutralPosition_ISig_4 "x0000001D04127A25";
BA_ "SeToolItemID_SIGNAL" SG_ 520 SecuredNeutralPosition_ISig_4 "x0000001D043C813E";
BA_ "SeToolName_SIGNAL" SG_ 520 SecuredNeutralPosition_ISig_4 "SecuredNeutralPosition";
BA_ "SeToolVersion_SIGNAL" SG_ 520 SecuredNeutralPosition_ISig_4 "2";
BA_ "GenSigCycleTime" SG_ 520 EngineStopRequest_ISig_4 100;
BA_ "GenSigCycleTimeActive" SG_ 520 EngineStopRequest_ISig_4 100;
BA_ "GenSigStartValue" SG_ 520 EngineStopRequest_ISig_4 3;
BA_ "GenSigMaxLatency" SG_ 520 EngineStopRequest_ISig_4 26;
BA_ "Platform_FactoryIf_Sig" SG_ 520 EngineStopRequest_ISig_4 1;
BA_ "Platform_VMCU1_Sig" SG_ 520 EngineStopRequest_ISig_4 1;
BA_ "SeToolAncestorID_SIGNAL" SG_ 520 EngineStopRequest_ISig_4 "x0000001D042883AC";
BA_ "SeToolItemID_SIGNAL" SG_ 520 EngineStopRequest_ISig_4 "x0000001D042883AC";
BA_ "SeToolName_SIGNAL" SG_ 520 EngineStopRequest_ISig_4 "EngineStopRequest";
BA_ "SeToolVersion_SIGNAL" SG_ 520 EngineStopRequest_ISig_4 "1";
BA_ "GenSigSendType" SG_ 520 TransmissionNeutralSwitch_UB_ISi 7;
BA_ "Platform_VMCU1_Sig" SG_ 520 TransmissionNeutralSwitch_UB_ISi 1;
BA_ "SystemSignalLongSymbol" SG_ 520 TransmissionNeutralSwitch_UB_ISi "TransmissionNeutralSwitch_UB_ISig_4";
BA_ "GenSigCycleTime" SG_ 520 ReverseGearEngaged_ISig_4 100;
BA_ "GenSigCycleTimeActive" SG_ 520 ReverseGearEngaged_ISig_4 100;
BA_ "GenSigStartValue" SG_ 520 ReverseGearEngaged_ISig_4 3;
BA_ "GenSigMaxLatency" SG_ 520 ReverseGearEngaged_ISig_4 26;
BA_ "NeedsUpdateBit" SG_ 520 ReverseGearEngaged_ISig_4 1;
BA_ "Platform_VMCU1_Sig" SG_ 520 ReverseGearEngaged_ISig_4 1;
BA_ "SeToolAncestorID_SIGNAL" SG_ 520 ReverseGearEngaged_ISig_4 "x0000001D0413A2F1";
BA_ "SeToolItemID_SIGNAL" SG_ 520 ReverseGearEngaged_ISig_4 "x0000001D0413A2F1";
BA_ "SeToolName_SIGNAL" SG_ 520 ReverseGearEngaged_ISig_4 "ReverseGearEngaged";
BA_ "SeToolVersion_SIGNAL" SG_ 520 ReverseGearEngaged_ISig_4 "1";
BA_ "GenSigSendType" SG_ 520 TransmSystemPowerDown_rqst_UB 7;
BA_ "Platform_VMCU1_Sig" SG_ 520 TransmSystemPowerDown_rqst_UB 1;
BA_ "GenSigCycleTime" SG_ 520 EngineCrankRequest 100;
BA_ "GenSigCycleTimeActive" SG_ 520 EngineCrankRequest 100;
BA_ "GenSigStartValue" SG_ 520 EngineCrankRequest 3;
BA_ "GenSigMaxLatency" SG_ 520 EngineCrankRequest 26;
BA_ "Platform_FactoryIf_Sig" SG_ 520 EngineCrankRequest 1;
BA_ "Platform_VMCU1_Sig" SG_ 520 EngineCrankRequest 1;
BA_ "SeToolAncestorID_SIGNAL" SG_ 520 EngineCrankRequest "x0000001D0418E20E";
BA_ "SeToolItemID_SIGNAL" SG_ 520 EngineCrankRequest "x0000001D0421DFDE";
BA_ "SeToolName_SIGNAL" SG_ 520 EngineCrankRequest "EngineCrankRequest";
BA_ "SeToolVersion_SIGNAL" SG_ 520 EngineCrankRequest "2";
BA_ "GenSigSendType" SG_ 520 ParkBrakeActuationStatus_UB_ISig 7;
BA_ "Platform_VMCU1_Sig" SG_ 520 ParkBrakeActuationStatus_UB_ISig 1;
BA_ "SystemSignalLongSymbol" SG_ 520 ParkBrakeActuationStatus_UB_ISig "ParkBrakeActuationStatus_UB_ISig_4";
BA_ "GenSigCycleTime" SG_ 520 ParkBrakeActuationStatus_ISig_4 100;
BA_ "GenSigCycleTimeActive" SG_ 520 ParkBrakeActuationStatus_ISig_4 100;
BA_ "GenSigStartValue" SG_ 520 ParkBrakeActuationStatus_ISig_4 7;
BA_ "NeedsUpdateBit" SG_ 520 ParkBrakeActuationStatus_ISig_4 1;
BA_ "Platform_VMCU1_Sig" SG_ 520 ParkBrakeActuationStatus_ISig_4 1;
BA_ "SeToolAncestorID_SIGNAL" SG_ 520 ParkBrakeActuationStatus_ISig_4 "x0000001D041497B7";
BA_ "SeToolItemID_SIGNAL" SG_ 520 ParkBrakeActuationStatus_ISig_4 "x0000001D0433084A";
BA_ "SeToolName_SIGNAL" SG_ 520 ParkBrakeActuationStatus_ISig_4 "ParkBrakeActuationStatus";
BA_ "SeToolVersion_SIGNAL" SG_ 520 ParkBrakeActuationStatus_ISig_4 "2";
BA_ "GenSigCycleTime" SG_ 520 EnginePreheat_rqst 100;
BA_ "GenSigCycleTimeActive" SG_ 520 EnginePreheat_rqst 100;
BA_ "GenSigStartValue" SG_ 520 EnginePreheat_rqst 3;
BA_ "GenSigMaxLatency" SG_ 520 EnginePreheat_rqst 26;
BA_ "Platform_VMCU1_Sig" SG_ 520 EnginePreheat_rqst 1;
BA_ "SeToolAncestorID_SIGNAL" SG_ 520 EnginePreheat_rqst "x0000001D0419A3FC";
BA_ "SeToolItemID_SIGNAL" SG_ 520 EnginePreheat_rqst "x0000001D04218951";
BA_ "SeToolName_SIGNAL" SG_ 520 EnginePreheat_rqst "EnginePreheat_rqst";
BA_ "SeToolVersion_SIGNAL" SG_ 520 EnginePreheat_rqst "2";
BA_ "GenSigSendType" SG_ 520 ReverseGearEngaged_UB_ISig_4 7;
BA_ "Platform_VMCU1_Sig" SG_ 520 ReverseGearEngaged_UB_ISig_4 1;
BA_ "GenSigCycleTime" SG_ 520 AcceleratorPedalPositionBackup 100;
BA_ "GenSigCycleTimeActive" SG_ 520 AcceleratorPedalPositionBackup 100;
BA_ "GenSigStartValue" SG_ 520 AcceleratorPedalPositionBackup 255;
BA_ "Platform_VMCU1_Sig" SG_ 520 AcceleratorPedalPositionBackup 1;
BA_ "GenSigCycleTime" SG_ 520 KeyPosition_ISig_4 100;
BA_ "GenSigCycleTimeActive" SG_ 520 KeyPosition_ISig_4 100;
BA_ "GenSigStartValue" SG_ 520 KeyPosition_ISig_4 7;
BA_ "GenSigMaxLatency" SG_ 520 KeyPosition_ISig_4 26;
BA_ "Platform_VMCU1_Sig" SG_ 520 KeyPosition_ISig_4 1;
BA_ "SeToolAncestorID_SIGNAL" SG_ 520 KeyPosition_ISig_4 "x0000001D0410D5F7";
BA_ "SeToolItemID_SIGNAL" SG_ 520 KeyPosition_ISig_4 "x0000001D0410D5F7";
BA_ "SeToolName_SIGNAL" SG_ 520 KeyPosition_ISig_4 "KeyPosition";
BA_ "SeToolVersion_SIGNAL" SG_ 520 KeyPosition_ISig_4 "1";
BA_ "GenSigCycleTime" SG_ 520 GearSplit_Status_ISig_4 100;
BA_ "GenSigCycleTimeActive" SG_ 520 GearSplit_Status_ISig_4 100;
BA_ "GenSigStartValue" SG_ 520 GearSplit_Status_ISig_4 3;
BA_ "NeedsUpdateBit" SG_ 520 GearSplit_Status_ISig_4 1;
BA_ "Platform_VMCU1_Sig" SG_ 520 GearSplit_Status_ISig_4 1;
BA_ "GenSigCycleTime" SG_ 520 FerryFunctionSwitchChangeACK_ISi 100;
BA_ "GenSigCycleTimeActive" SG_ 520 FerryFunctionSwitchChangeACK_ISi 100;
BA_ "GenSigStartValue" SG_ 520 FerryFunctionSwitchChangeACK_ISi 3;
BA_ "Platform_VMCU1_Sig" SG_ 520 FerryFunctionSwitchChangeACK_ISi 1;
BA_ "SystemSignalLongSymbol" SG_ 520 FerryFunctionSwitchChangeACK_ISi "FerryFunctionSwitchChangeACK_ISig_4";
BA_ "GenSigSendType" SG_ 520 SecuredNeutralPosition_UB_ISig_4 7;
BA_ "Platform_FactoryIf_Sig" SG_ 520 SecuredNeutralPosition_UB_ISig_4 1;
BA_ "Platform_VMCU1_Sig" SG_ 520 SecuredNeutralPosition_UB_ISig_4 1;
BA_ "GenSigCycleTime" SG_ 520 DirectionIndication_cmd 100;
BA_ "GenSigCycleTimeActive" SG_ 520 DirectionIndication_cmd 100;
BA_ "GenSigStartValue" SG_ 520 DirectionIndication_cmd 15;
BA_ "GenSigMaxLatency" SG_ 520 DirectionIndication_cmd 26;
BA_ "Platform_VMCU1_Sig" SG_ 520 DirectionIndication_cmd 1;
BA_ "SeToolAncestorID_SIGNAL" SG_ 520 DirectionIndication_cmd "x0000001D042C9D17";
BA_ "SeToolItemID_SIGNAL" SG_ 520 DirectionIndication_cmd "x0000001D0433EF63";
BA_ "SeToolName_SIGNAL" SG_ 520 DirectionIndication_cmd "DirectionIndication_cmd";
BA_ "SeToolVersion_SIGNAL" SG_ 520 DirectionIndication_cmd "2";
BA_ "GenSigCycleTime" SG_ 520 IdleShutdownWarning 100;
BA_ "GenSigCycleTimeActive" SG_ 520 IdleShutdownWarning 100;
BA_ "GenSigStartValue" SG_ 520 IdleShutdownWarning 3;
BA_ "GenSigMaxLatency" SG_ 520 IdleShutdownWarning 26;
BA_ "Platform_VMCU1_Sig" SG_ 520 IdleShutdownWarning 1;
BA_ "SeToolAncestorID_SIGNAL" SG_ 520 IdleShutdownWarning "x0000001D0417E7DE";
BA_ "SeToolItemID_SIGNAL" SG_ 520 IdleShutdownWarning "x0000001D0417E7DE";
BA_ "SeToolName_SIGNAL" SG_ 520 IdleShutdownWarning "IdleShutdownWarning";
BA_ "SeToolVersion_SIGNAL" SG_ 520 IdleShutdownWarning "1";
BA_ "GenSigCycleTime" SG_ 520 BackToDriveReqACK_ISig_4 100;
BA_ "GenSigCycleTimeActive" SG_ 520 BackToDriveReqACK_ISig_4 100;
BA_ "GenSigStartValue" SG_ 520 BackToDriveReqACK_ISig_4 3;
BA_ "Platform_VMCU1_Sig" SG_ 520 BackToDriveReqACK_ISig_4 1;
BA_ "GenSigCycleTime" SG_ 520 EngineSystemPowerDownRequest_ISi 100;
BA_ "GenSigCycleTimeActive" SG_ 520 EngineSystemPowerDownRequest_ISi 100;
BA_ "GenSigStartValue" SG_ 520 EngineSystemPowerDownRequest_ISi 3;
BA_ "GenSigMaxLatency" SG_ 520 EngineSystemPowerDownRequest_ISi 26;
BA_ "Platform_FactoryIf_Sig" SG_ 520 EngineSystemPowerDownRequest_ISi 1;
BA_ "Platform_VMCU1_Sig" SG_ 520 EngineSystemPowerDownRequest_ISi 1;
BA_ "SeToolAncestorID_SIGNAL" SG_ 520 EngineSystemPowerDownRequest_ISi "x0000001D0436C642";
BA_ "SeToolItemID_SIGNAL" SG_ 520 EngineSystemPowerDownRequest_ISi "x0000001D0436C642";
BA_ "SeToolName_SIGNAL" SG_ 520 EngineSystemPowerDownRequest_ISi "EngineSystemPowerDownRequest";
BA_ "SeToolVersion_SIGNAL" SG_ 520 EngineSystemPowerDownRequest_ISi "1";
BA_ "SystemSignalLongSymbol" SG_ 520 EngineSystemPowerDownRequest_ISi "EngineSystemPowerDownRequest_ISig_4";
BA_ "GenSigSendType" SG_ 2671902706 FuncDiagDataTester_ISig_4 7;
BA_ "Platform_VMCU1_Sig" SG_ 2671902706 FuncDiagDataTester_ISig_4 1;
BA_ "GenSigCycleTime" SG_ 1283 TrafficSitPathExecSta_Type 100;
BA_ "GenSigCycleTimeActive" SG_ 1283 TrafficSitPathExecSta_Type 100;
BA_ "GenSigStartValue" SG_ 1283 TrafficSitPathExecSta_Type 255;
BA_ "GenSigCycleTime" SG_ 1283 TrafficSitPathExecSta_Speed 100;
BA_ "GenSigCycleTimeActive" SG_ 1283 TrafficSitPathExecSta_Speed 100;
BA_ "GenSigStartValue" SG_ 1283 TrafficSitPathExecSta_Speed 1023;
BA_ "GenSigCycleTime" SG_ 1283 TrafficSitPathExecSta_Distance 100;
BA_ "GenSigCycleTimeActive" SG_ 1283 TrafficSitPathExecSta_Distance 100;
BA_ "GenSigStartValue" SG_ 1283 TrafficSitPathExecSta_Distance 16383;
BA_ "GenSigCycleTime" SG_ 1463 TECU_Available_Log_ISig_4 100;
BA_ "GenSigCycleTimeActive" SG_ 1463 TECU_Available_Log_ISig_4 100;
BA_ "GenSigStartValue" SG_ 1463 TECU_Available_Log_ISig_4 255;
BA_ "GenSigSendType" SG_ 1446 TECU_BB2_06S_FCS 7;
BA_ "GenSigSendType" SG_ 1445 ECU5VIN_stat 1;
BA_ "GenSigMaxLatency" SG_ 1445 ECU5VIN_stat 1000;
BA_ "GenSigSendType" SG_ 939 TECU_BB2_05S_FCS 7;
BA_ "GenSigSendType" SG_ 938 KeyID_EncryptedGBUnlockAuth 1;
BA_ "GenSigMaxLatency" SG_ 938 KeyID_EncryptedGBUnlockAuth 1000;
BA_ "GenSigSendType" SG_ 1480 TECU_BB2_04S_FCS 7;
BA_ "Platform_VMCU1_Sig" SG_ 1480 TECU_BB2_04S_FCS 1;
BA_ "GenSigSendType" SG_ 1479 HillDataPkgTECU_ISig_4 1;
BA_ "GenSigMaxLatency" SG_ 1479 HillDataPkgTECU_ISig_4 2500;
BA_ "Platform_VMCU1_Sig" SG_ 1479 HillDataPkgTECU_ISig_4 1;
BA_ "GenSigCycleTime" SG_ 1249 OilLevelDrvInstr_IncorrEngSpe 100;
BA_ "GenSigCycleTimeActive" SG_ 1249 OilLevelDrvInstr_IncorrEngSpe 100;
BA_ "GenSigStartValue" SG_ 1249 OilLevelDrvInstr_IncorrEngSpe 3;
BA_ "Platform_VMCU1_Sig" SG_ 1249 OilLevelDrvInstr_IncorrEngSpe 1;
BA_ "GenSigCycleTime" SG_ 1249 OilLevelDrvInstr_StopVehicle 100;
BA_ "GenSigCycleTimeActive" SG_ 1249 OilLevelDrvInstr_StopVehicle 100;
BA_ "GenSigStartValue" SG_ 1249 OilLevelDrvInstr_StopVehicle 3;
BA_ "Platform_VMCU1_Sig" SG_ 1249 OilLevelDrvInstr_StopVehicle 1;
BA_ "GenSigCycleTime" SG_ 1249 SchwungStatus 100;
BA_ "GenSigCycleTimeActive" SG_ 1249 SchwungStatus 100;
BA_ "GenSigStartValue" SG_ 1249 SchwungStatus 3;
BA_ "GenSigCycleTime" SG_ 1249 HillDataCtrlTECU_State_ISig_4 100;
BA_ "GenSigCycleTimeActive" SG_ 1249 HillDataCtrlTECU_State_ISig_4 100;
BA_ "GenSigStartValue" SG_ 1249 HillDataCtrlTECU_State_ISig_4 7;
BA_ "Platform_VMCU1_Sig" SG_ 1249 HillDataCtrlTECU_State_ISig_4 1;
BA_ "GenSigCycleTime" SG_ 1249 OilLevelDrvInstr_Wait60SecTxt 100;
BA_ "GenSigCycleTimeActive" SG_ 1249 OilLevelDrvInstr_Wait60SecTxt 100;
BA_ "GenSigStartValue" SG_ 1249 OilLevelDrvInstr_Wait60SecTxt 3;
BA_ "Platform_VMCU1_Sig" SG_ 1249 OilLevelDrvInstr_Wait60SecTxt 1;
BA_ "GenSigCycleTime" SG_ 1249 ClutchAbuseStatus 100;
BA_ "GenSigCycleTimeActive" SG_ 1249 ClutchAbuseStatus 100;
BA_ "GenSigStartValue" SG_ 1249 ClutchAbuseStatus 3;
BA_ "Platform_VMCU1_Sig" SG_ 1249 ClutchAbuseStatus 1;
BA_ "GenSigCycleTime" SG_ 1249 TransmissionSplitboxPTOMode 100;
BA_ "GenSigCycleTimeActive" SG_ 1249 TransmissionSplitboxPTOMode 100;
BA_ "GenSigStartValue" SG_ 1249 TransmissionSplitboxPTOMode 7;
BA_ "GenSigCycleTime" SG_ 1249 CACCSuitability 100;
BA_ "GenSigCycleTimeActive" SG_ 1249 CACCSuitability 100;
BA_ "GenSigStartValue" SG_ 1249 CACCSuitability 3;
BA_ "GenSigCycleTime" SG_ 1249 ClutchCalibration_stat 100;
BA_ "GenSigCycleTimeActive" SG_ 1249 ClutchCalibration_stat 100;
BA_ "GenSigStartValue" SG_ 1249 ClutchCalibration_stat 3;
BA_ "GenSigCycleTime" SG_ 1249 OilLevelDrvInstr_ChangeGearTxt 100;
BA_ "GenSigCycleTimeActive" SG_ 1249 OilLevelDrvInstr_ChangeGearTxt 100;
BA_ "GenSigStartValue" SG_ 1249 OilLevelDrvInstr_ChangeGearTxt 3;
BA_ "Platform_VMCU1_Sig" SG_ 1249 OilLevelDrvInstr_ChangeGearTxt 1;
BA_ "GenSigCycleTime" SG_ 1249 OilLevelDrvInstr_NotHorizonTxt 100;
BA_ "GenSigCycleTimeActive" SG_ 1249 OilLevelDrvInstr_NotHorizonTxt 100;
BA_ "GenSigStartValue" SG_ 1249 OilLevelDrvInstr_NotHorizonTxt 3;
BA_ "Platform_VMCU1_Sig" SG_ 1249 OilLevelDrvInstr_NotHorizonTxt 1;
BA_ "GenSigCycleTime" SG_ 1249 ISeeStatus 100;
BA_ "GenSigCycleTimeActive" SG_ 1249 ISeeStatus 100;
BA_ "GenSigStartValue" SG_ 1249 ISeeStatus 7;
BA_ "GenSigCycleTime" SG_ 1249 EcoRollEnabledStatus 100;
BA_ "GenSigCycleTimeActive" SG_ 1249 EcoRollEnabledStatus 100;
BA_ "GenSigStartValue" SG_ 1249 EcoRollEnabledStatus 3;
BA_ "GenSigCycleTime" SG_ 1249 OilLevelDrvInstr_OilTempTxt 100;
BA_ "GenSigCycleTimeActive" SG_ 1249 OilLevelDrvInstr_OilTempTxt 100;
BA_ "GenSigStartValue" SG_ 1249 OilLevelDrvInstr_OilTempTxt 3;
BA_ "Platform_VMCU1_Sig" SG_ 1249 OilLevelDrvInstr_OilTempTxt 1;
BA_ "GenSigCycleTime" SG_ 1249 HillDataCtrlTECU_AckCnt_ISig_4 100;
BA_ "GenSigCycleTimeActive" SG_ 1249 HillDataCtrlTECU_AckCnt_ISig_4 100;
BA_ "Platform_VMCU1_Sig" SG_ 1249 HillDataCtrlTECU_AckCnt_ISig_4 1;
BA_REL_ "GenSigFirstTimeoutTime" BU_SG_REL_ IC3 SG_ 1303 CalLoadTrailer1Axle4_ISig_4 24000;
BA_REL_ "GenSigTimeoutTime" BU_SG_REL_ IC3 SG_ 1303 CalLoadTrailer1Axle4_ISig_4 6000;
BA_REL_ "GenSigFirstTimeoutTime" BU_SG_REL_ CIOM SG_ 1303 CalLoadTrailer1Axle4_ISig_4 24000;
BA_REL_ "GenSigTimeoutTime" BU_SG_REL_ CIOM SG_ 1303 CalLoadTrailer1Axle4_ISig_4 6000;
BA_REL_ "GenSigFirstTimeoutTime" BU_SG_REL_ BBM SG_ 1303 CalLoadTrailer1Axle4_ISig_4 24000;
BA_REL_ "GenSigTimeoutTime" BU_SG_REL_ BBM SG_ 1303 CalLoadTrailer1Axle4_ISig_4 6000;
BA_REL_ "GenSigFirstTimeoutTime" BU_SG_REL_ CIOM SG_ 1303 CalLoadTrailer4Axle2_ISig_4 24000;
BA_REL_ "GenSigTimeoutTime" BU_SG_REL_ CIOM SG_ 1303 CalLoadTrailer4Axle2_ISig_4 6000;
BA_REL_ "GenSigFirstTimeoutTime" BU_SG_REL_ IC3 SG_ 1303 CalLoadTrailer4Axle2_ISig_4 24000;
BA_REL_ "GenSigTimeoutTime" BU_SG_REL_ IC3 SG_ 1303 CalLoadTrailer4Axle2_ISig_4 6000;
BA_REL_ "GenSigFirstTimeoutTime" BU_SG_REL_ CIOM SG_ 1303 CalLoadTrailer2Axle1_ISig_4 24000;
BA_REL_ "GenSigTimeoutTime" BU_SG_REL_ CIOM SG_ 1303 CalLoadTrailer2Axle1_ISig_4 6000;
BA_REL_ "GenSigFirstTimeoutTime" BU_SG_REL_ BBM SG_ 1303 CalLoadTrailer2Axle1_ISig_4 24000;
BA_REL_ "GenSigTimeoutTime" BU_SG_REL_ BBM SG_ 1303 CalLoadTrailer2Axle1_ISig_4 6000;
BA_REL_ "GenSigFirstTimeoutTime" BU_SG_REL_ IC3 SG_ 1303 CalLoadTrailer2Axle1_ISig_4 24000;
BA_REL_ "GenSigTimeoutTime" BU_SG_REL_ IC3 SG_ 1303 CalLoadTrailer2Axle1_ISig_4 6000;
BA_REL_ "GenSigFirstTimeoutTime" BU_SG_REL_ CIOM SG_ 1303 CalLoadTrailer4Axle3_ISig_4 24000;
BA_REL_ "GenSigTimeoutTime" BU_SG_REL_ CIOM SG_ 1303 CalLoadTrailer4Axle3_ISig_4 6000;
BA_REL_ "GenSigFirstTimeoutTime" BU_SG_REL_ IC3 SG_ 1303 CalLoadTrailer4Axle3_ISig_4 24000;
BA_REL_ "GenSigTimeoutTime" BU_SG_REL_ IC3 SG_ 1303 CalLoadTrailer4Axle3_ISig_4 6000;
BA_REL_ "GenSigFirstTimeoutTime" BU_SG_REL_ BBM SG_ 1302 CalLoadTruckRearAxle2_ISig_4 24000;
BA_REL_ "GenSigTimeoutTime" BU_SG_REL_ BBM SG_ 1302 CalLoadTruckRearAxle2_ISig_4 6000;
BA_REL_ "GenSigFirstTimeoutTime" BU_SG_REL_ IC3 SG_ 1302 CalLoadTruckRearAxle2_ISig_4 24000;
BA_REL_ "GenSigTimeoutTime" BU_SG_REL_ IC3 SG_ 1302 CalLoadTruckRearAxle2_ISig_4 6000;
BA_REL_ "GenSigFirstTimeoutTime" BU_SG_REL_ CIOM SG_ 1302 CalLoadTruckRearAxle2_ISig_4 24000;
BA_REL_ "GenSigTimeoutTime" BU_SG_REL_ CIOM SG_ 1302 CalLoadTruckRearAxle2_ISig_4 6000;
BA_REL_ "GenSigFirstTimeoutTime" BU_SG_REL_ BBM SG_ 1302 CalLoadTruckRearAxle3_ISig_4 24000;
BA_REL_ "GenSigTimeoutTime" BU_SG_REL_ BBM SG_ 1302 CalLoadTruckRearAxle3_ISig_4 6000;
BA_REL_ "GenSigFirstTimeoutTime" BU_SG_REL_ CIOM SG_ 1302 CalLoadTruckRearAxle3_ISig_4 24000;
BA_REL_ "GenSigTimeoutTime" BU_SG_REL_ CIOM SG_ 1302 CalLoadTruckRearAxle3_ISig_4 6000;
BA_REL_ "GenSigFirstTimeoutTime" BU_SG_REL_ IC3 SG_ 1302 CalLoadTruckRearAxle3_ISig_4 24000;
BA_REL_ "GenSigTimeoutTime" BU_SG_REL_ IC3 SG_ 1302 CalLoadTruckRearAxle3_ISig_4 6000;
BA_REL_ "GenSigFirstTimeoutTime" BU_SG_REL_ IC3 SG_ 1302 CalLoadTrailer3Axle5_ISig_4 24000;
BA_REL_ "GenSigTimeoutTime" BU_SG_REL_ IC3 SG_ 1302 CalLoadTrailer3Axle5_ISig_4 6000;
BA_REL_ "GenSigFirstTimeoutTime" BU_SG_REL_ CIOM SG_ 1302 CalLoadTrailer3Axle5_ISig_4 24000;
BA_REL_ "GenSigTimeoutTime" BU_SG_REL_ CIOM SG_ 1302 CalLoadTrailer3Axle5_ISig_4 6000;
BA_REL_ "GenSigFirstTimeoutTime" BU_SG_REL_ IC3 SG_ 1302 CalLoadTrailer4Axle6_ISig_4 24000;
BA_REL_ "GenSigTimeoutTime" BU_SG_REL_ IC3 SG_ 1302 CalLoadTrailer4Axle6_ISig_4 6000;
BA_REL_ "GenSigFirstTimeoutTime" BU_SG_REL_ CIOM SG_ 1302 CalLoadTrailer4Axle6_ISig_4 24000;
BA_REL_ "GenSigTimeoutTime" BU_SG_REL_ CIOM SG_ 1302 CalLoadTrailer4Axle6_ISig_4 6000;
BA_REL_ "GenSigFirstTimeoutTime" BU_SG_REL_ CIOM SG_ 1301 CalLoadTrailer5Axle2_ISig_4 24000;
BA_REL_ "GenSigTimeoutTime" BU_SG_REL_ CIOM SG_ 1301 CalLoadTrailer5Axle2_ISig_4 6000;
BA_REL_ "GenSigFirstTimeoutTime" BU_SG_REL_ IC3 SG_ 1301 CalLoadTrailer5Axle2_ISig_4 24000;
BA_REL_ "GenSigTimeoutTime" BU_SG_REL_ IC3 SG_ 1301 CalLoadTrailer5Axle2_ISig_4 6000;
BA_REL_ "GenSigFirstTimeoutTime" BU_SG_REL_ IC3 SG_ 1301 CalLoadTrailer1Axle2_ISig_4 24000;
BA_REL_ "GenSigTimeoutTime" BU_SG_REL_ IC3 SG_ 1301 CalLoadTrailer1Axle2_ISig_4 6000;
BA_REL_ "GenSigFirstTimeoutTime" BU_SG_REL_ CIOM SG_ 1301 CalLoadTrailer1Axle2_ISig_4 24000;
BA_REL_ "GenSigTimeoutTime" BU_SG_REL_ CIOM SG_ 1301 CalLoadTrailer1Axle2_ISig_4 6000;
BA_REL_ "GenSigFirstTimeoutTime" BU_SG_REL_ BBM SG_ 1301 CalLoadTrailer1Axle2_ISig_4 24000;
BA_REL_ "GenSigTimeoutTime" BU_SG_REL_ BBM SG_ 1301 CalLoadTrailer1Axle2_ISig_4 6000;
BA_REL_ "GenSigFirstTimeoutTime" BU_SG_REL_ IC3 SG_ 1301 CalLoadTrailer1Axle5_ISig_4 24000;
BA_REL_ "GenSigTimeoutTime" BU_SG_REL_ IC3 SG_ 1301 CalLoadTrailer1Axle5_ISig_4 6000;
BA_REL_ "GenSigFirstTimeoutTime" BU_SG_REL_ CIOM SG_ 1301 CalLoadTrailer1Axle5_ISig_4 24000;
BA_REL_ "GenSigTimeoutTime" BU_SG_REL_ CIOM SG_ 1301 CalLoadTrailer1Axle5_ISig_4 6000;
BA_REL_ "GenSigFirstTimeoutTime" BU_SG_REL_ CIOM SG_ 1301 CalLoadTrailer2Axle4_ISig_4 24000;
BA_REL_ "GenSigTimeoutTime" BU_SG_REL_ CIOM SG_ 1301 CalLoadTrailer2Axle4_ISig_4 6000;
BA_REL_ "GenSigFirstTimeoutTime" BU_SG_REL_ BBM SG_ 1301 CalLoadTrailer2Axle4_ISig_4 24000;
BA_REL_ "GenSigTimeoutTime" BU_SG_REL_ BBM SG_ 1301 CalLoadTrailer2Axle4_ISig_4 6000;
BA_REL_ "GenSigFirstTimeoutTime" BU_SG_REL_ IC3 SG_ 1301 CalLoadTrailer2Axle4_ISig_4 24000;
BA_REL_ "GenSigTimeoutTime" BU_SG_REL_ IC3 SG_ 1301 CalLoadTrailer2Axle4_ISig_4 6000;
BA_REL_ "GenSigFirstTimeoutTime" BU_SG_REL_ IC3 SG_ 1416 WasherFluidLevel_ISig_4 12000;
BA_REL_ "GenSigTimeoutTime" BU_SG_REL_ IC3 SG_ 1416 WasherFluidLevel_ISig_4 3000;
BA_REL_ "GenSigFirstTimeoutTime" BU_SG_REL_ IC3 SG_ 1416 FuelVolume_ISig_4 12000;
BA_REL_ "GenSigTimeoutTime" BU_SG_REL_ IC3 SG_ 1416 FuelVolume_ISig_4 3000;
BA_REL_ "GenSigFirstTimeoutTime" BU_SG_REL_ EMS SG_ 1416 KFactor 12000;
BA_REL_ "GenSigTimeoutTime" BU_SG_REL_ EMS SG_ 1416 KFactor 3000;
BA_REL_ "GenSigFirstTimeoutTime" BU_SG_REL_ TECU SG_ 1416 KFactor 12000;
BA_REL_ "GenSigTimeoutTime" BU_SG_REL_ TECU SG_ 1416 KFactor 3000;
BA_REL_ "GenSigFirstTimeoutTime" BU_SG_REL_ BBM SG_ 1416 KFactor 12000;
BA_REL_ "GenSigTimeoutTime" BU_SG_REL_ BBM SG_ 1416 KFactor 3000;
BA_REL_ "GenSigFirstTimeoutTime" BU_SG_REL_ DACU SG_ 1416 KFactor 12000;
BA_REL_ "GenSigTimeoutTime" BU_SG_REL_ DACU SG_ 1416 KFactor 3000;
BA_REL_ "GenSigFirstTimeoutTime" BU_SG_REL_ IC3 SG_ 1416 ManTransmiOilTemp_ISig_4 12000;
BA_REL_ "GenSigTimeoutTime" BU_SG_REL_ IC3 SG_ 1416 ManTransmiOilTemp_ISig_4 3000;
BA_REL_ "GenSigFirstTimeoutTime" BU_SG_REL_ IC3 SG_ 1416 EngSpeedGreenAreaMode_ISig_4 12000;
BA_REL_ "GenSigTimeoutTime" BU_SG_REL_ IC3 SG_ 1416 EngSpeedGreenAreaMode_ISig_4 3000;
BA_REL_ "GenSigFirstTimeoutTime" BU_SG_REL_ CIOM SG_ 1050 CabRoofSignLightFeedback_stat 6000;
BA_REL_ "GenSigTimeoutTime" BU_SG_REL_ CIOM SG_ 1050 CabRoofSignLightFeedback_stat 6000;
BA_REL_ "GenSigFirstTimeoutTime" BU_SG_REL_ CIOM SG_ 1050 CabExtraSideWrknLightFdbk_stat_I 6000;
BA_REL_ "GenSigTimeoutTime" BU_SG_REL_ CIOM SG_ 1050 CabExtraSideWrknLightFdbk_stat_I 6000;
BA_REL_ "GenSigFirstTimeoutTime" BU_SG_REL_ BBM SG_ 1050 CabExtraSideWrknLightFdbk_stat_I 3000;
BA_REL_ "GenSigTimeoutTime" BU_SG_REL_ BBM SG_ 1050 CabExtraSideWrknLightFdbk_stat_I 600;
BA_REL_ "GenSigFirstTimeoutTime" BU_SG_REL_ BBM SG_ 1050 CabWrknLightChassisFdbk_stat_ISi 3000;
BA_REL_ "GenSigTimeoutTime" BU_SG_REL_ BBM SG_ 1050 CabWrknLightChassisFdbk_stat_ISi 600;
BA_REL_ "GenSigFirstTimeoutTime" BU_SG_REL_ CIOM SG_ 1050 CabWrknLightChassisFdbk_stat_ISi 6000;
BA_REL_ "GenSigTimeoutTime" BU_SG_REL_ CIOM SG_ 1050 CabWrknLightChassisFdbk_stat_ISi 6000;
BA_REL_ "GenSigFirstTimeoutTime" BU_SG_REL_ CIOM SG_ 1050 CabTrailerBodyLgthnFdbk_stat 6000;
BA_REL_ "GenSigTimeoutTime" BU_SG_REL_ CIOM SG_ 1050 CabTrailerBodyLgthnFdbk_stat 6000;
BA_REL_ "GenSigFirstTimeoutTime" BU_SG_REL_ BBM SG_ 1050 DiffLockInterWhlStatusSplitBox_I 3000;
BA_REL_ "GenSigTimeoutTime" BU_SG_REL_ BBM SG_ 1050 DiffLockInterWhlStatusSplitBox_I 600;
BA_REL_ "GenSigFirstTimeoutTime" BU_SG_REL_ CIOM SG_ 1050 BodyOrCabWorkingLightFdbk_stat_I 6000;
BA_REL_ "GenSigTimeoutTime" BU_SG_REL_ CIOM SG_ 1050 BodyOrCabWorkingLightFdbk_stat_I 6000;
BA_REL_ "GenSigFirstTimeoutTime" BU_SG_REL_ BBM SG_ 1050 BodyOrCabWorkingLightFdbk_stat_I 3000;
BA_REL_ "GenSigTimeoutTime" BU_SG_REL_ BBM SG_ 1050 BodyOrCabWorkingLightFdbk_stat_I 600;
BA_REL_ "GenSigFirstTimeoutTime" BU_SG_REL_ CIOM SG_ 1050 WheelBasedVehicleSpeedLowRes_ISi 6000;
BA_REL_ "GenSigTimeoutTime" BU_SG_REL_ CIOM SG_ 1050 WheelBasedVehicleSpeedLowRes_ISi 6000;
BA_REL_ "GenSigFirstTimeoutTime" BU_SG_REL_ EMS SG_ 1050 AirDryerCoolingFanSpeed_rqst 6000;
BA_REL_ "GenSigTimeoutTime" BU_SG_REL_ EMS SG_ 1050 AirDryerCoolingFanSpeed_rqst 1500;
BA_REL_ "GenSigFirstTimeoutTime" BU_SG_REL_ CIOM SG_ 1050 CabFrontSpotFeedback_Status 6000;
BA_REL_ "GenSigTimeoutTime" BU_SG_REL_ CIOM SG_ 1050 CabFrontSpotFeedback_Status 6000;
BA_REL_ "GenSigFirstTimeoutTime" BU_SG_REL_ CIOM SG_ 1050 CabTiltEnableStatus 6000;
BA_REL_ "GenSigTimeoutTime" BU_SG_REL_ CIOM SG_ 1050 CabTiltEnableStatus 6000;
BA_REL_ "GenSigFirstTimeoutTime" BU_SG_REL_ BBM SG_ 1050 TransmReverseDirectionSw_stat_IS 3000;
BA_REL_ "GenSigTimeoutTime" BU_SG_REL_ BBM SG_ 1050 TransmReverseDirectionSw_stat_IS 600;
BA_REL_ "GenSigFirstTimeoutTime" BU_SG_REL_ CIOM SG_ 1050 CabRoofSpotFeedback_Status 6000;
BA_REL_ "GenSigTimeoutTime" BU_SG_REL_ CIOM SG_ 1050 CabRoofSpotFeedback_Status 6000;
BA_REL_ "GenSigFirstTimeoutTime" BU_SG_REL_ CIOM SG_ 1050 CabBeaconLightFeedback_Status_IS 6000;
BA_REL_ "GenSigTimeoutTime" BU_SG_REL_ CIOM SG_ 1050 CabBeaconLightFeedback_Status_IS 6000;
BA_REL_ "GenSigFirstTimeoutTime" BU_SG_REL_ BBM SG_ 1050 CabBeaconLightFeedback_Status_IS 3000;
BA_REL_ "GenSigTimeoutTime" BU_SG_REL_ BBM SG_ 1050 CabBeaconLightFeedback_Status_IS 600;
BA_REL_ "GenSigFirstTimeoutTime" BU_SG_REL_ CIOM SG_ 1050 ExtraAxleSteeringFunctionStat_IS 6000;
BA_REL_ "GenSigTimeoutTime" BU_SG_REL_ CIOM SG_ 1050 ExtraAxleSteeringFunctionStat_IS 6000;
BA_REL_ "GenSigFirstTimeoutTime" BU_SG_REL_ BBM SG_ 1050 CabTiltLockStatus_ISig_4 3000;
BA_REL_ "GenSigTimeoutTime" BU_SG_REL_ BBM SG_ 1050 CabTiltLockStatus_ISig_4 600;
BA_REL_ "GenSigFirstTimeoutTime" BU_SG_REL_ IC3 SG_ 1050 CabTiltLockStatus_ISig_4 3000;
BA_REL_ "GenSigTimeoutTime" BU_SG_REL_ IC3 SG_ 1050 CabTiltLockStatus_ISig_4 600;
BA_REL_ "GenSigFirstTimeoutTime" BU_SG_REL_ IC3 SG_ 1050 PositionLightRearLamp_stat_ISig_ 3000;
BA_REL_ "GenSigTimeoutTime" BU_SG_REL_ IC3 SG_ 1050 PositionLightRearLamp_stat_ISig_ 600;
BA_REL_ "GenSigFirstTimeoutTime" BU_SG_REL_ BBM SG_ 931 Pto1BadCondition 3000;
BA_REL_ "GenSigTimeoutTime" BU_SG_REL_ BBM SG_ 931 Pto1BadCondition 450;
BA_REL_ "GenSigFirstTimeoutTime" BU_SG_REL_ IC3 SG_ 931 Pto1BadCondition 3000;
BA_REL_ "GenSigTimeoutTime" BU_SG_REL_ IC3 SG_ 931 Pto1BadCondition 450;
BA_REL_ "GenSigFirstTimeoutTime" BU_SG_REL_ IC3 SG_ 931 Pto4BadCondition 3000;
BA_REL_ "GenSigTimeoutTime" BU_SG_REL_ IC3 SG_ 931 Pto4BadCondition 450;
BA_REL_ "GenSigFirstTimeoutTime" BU_SG_REL_ BBM SG_ 931 Pto4BadCondition 3000;
BA_REL_ "GenSigTimeoutTime" BU_SG_REL_ BBM SG_ 931 Pto4BadCondition 450;
BA_REL_ "GenSigFirstTimeoutTime" BU_SG_REL_ IC3 SG_ 931 Pto2BadCondition 3000;
BA_REL_ "GenSigTimeoutTime" BU_SG_REL_ IC3 SG_ 931 Pto2BadCondition 450;
BA_REL_ "GenSigFirstTimeoutTime" BU_SG_REL_ BBM SG_ 931 Pto2BadCondition 3000;
BA_REL_ "GenSigTimeoutTime" BU_SG_REL_ BBM SG_ 931 Pto2BadCondition 450;
BA_REL_ "GenSigFirstTimeoutTime" BU_SG_REL_ EMS SG_ 931 PtoRequest 3000;
BA_REL_ "GenSigTimeoutTime" BU_SG_REL_ EMS SG_ 931 PtoRequest 450;
BA_REL_ "GenSigFirstTimeoutTime" BU_SG_REL_ TECU SG_ 931 Pto2ConsentRequest 3000;
BA_REL_ "GenSigTimeoutTime" BU_SG_REL_ TECU SG_ 931 Pto2ConsentRequest 450;
BA_REL_ "GenSigFirstTimeoutTime" BU_SG_REL_ IC3 SG_ 931 PBStatusDisplay_cmd_ISig_4 3000;
BA_REL_ "GenSigTimeoutTime" BU_SG_REL_ IC3 SG_ 931 PBStatusDisplay_cmd_ISig_4 450;
BA_REL_ "GenSigFirstTimeoutTime" BU_SG_REL_ BBM SG_ 931 Pto4DrivingRequest 3000;
BA_REL_ "GenSigTimeoutTime" BU_SG_REL_ BBM SG_ 931 Pto4DrivingRequest 450;
BA_REL_ "GenSigFirstTimeoutTime" BU_SG_REL_ CIOM SG_ 931 Pto3Indication 3000;
BA_REL_ "GenSigTimeoutTime" BU_SG_REL_ CIOM SG_ 931 Pto3Indication 450;
BA_REL_ "GenSigFirstTimeoutTime" BU_SG_REL_ IC3 SG_ 931 Pto2Status_ISig_4 3000;
BA_REL_ "GenSigTimeoutTime" BU_SG_REL_ IC3 SG_ 931 Pto2Status_ISig_4 450;
BA_REL_ "GenSigFirstTimeoutTime" BU_SG_REL_ TECU SG_ 931 Pto2Status_ISig_4 3000;
BA_REL_ "GenSigTimeoutTime" BU_SG_REL_ TECU SG_ 931 Pto2Status_ISig_4 450;
BA_REL_ "GenSigFirstTimeoutTime" BU_SG_REL_ CIOM SG_ 931 Pto2Status_ISig_4 3000;
BA_REL_ "GenSigTimeoutTime" BU_SG_REL_ CIOM SG_ 931 Pto2Status_ISig_4 450;
BA_REL_ "GenSigFirstTimeoutTime" BU_SG_REL_ BBM SG_ 931 Pto2Status_ISig_4 3000;
BA_REL_ "GenSigTimeoutTime" BU_SG_REL_ BBM SG_ 931 Pto2Status_ISig_4 450;
BA_REL_ "GenSigFirstTimeoutTime" BU_SG_REL_ CIOM SG_ 931 Pto4Status_ISig_4 3000;
BA_REL_ "GenSigTimeoutTime" BU_SG_REL_ CIOM SG_ 931 Pto4Status_ISig_4 450;
BA_REL_ "GenSigFirstTimeoutTime" BU_SG_REL_ IC3 SG_ 931 Pto4Status_ISig_4 3000;
BA_REL_ "GenSigTimeoutTime" BU_SG_REL_ IC3 SG_ 931 Pto4Status_ISig_4 450;
BA_REL_ "GenSigFirstTimeoutTime" BU_SG_REL_ BBM SG_ 931 Pto4Status_ISig_4 3000;
BA_REL_ "GenSigTimeoutTime" BU_SG_REL_ BBM SG_ 931 Pto4Status_ISig_4 450;
BA_REL_ "GenSigFirstTimeoutTime" BU_SG_REL_ CIOM SG_ 931 RampLevelRequestACK_ISig_4 3000;
BA_REL_ "GenSigTimeoutTime" BU_SG_REL_ CIOM SG_ 931 RampLevelRequestACK_ISig_4 450;
BA_REL_ "GenSigFirstTimeoutTime" BU_SG_REL_ IC3 SG_ 931 Pto3BadCondition 3000;
BA_REL_ "GenSigTimeoutTime" BU_SG_REL_ IC3 SG_ 931 Pto3BadCondition 450;
BA_REL_ "GenSigFirstTimeoutTime" BU_SG_REL_ BBM SG_ 931 Pto3BadCondition 3000;
BA_REL_ "GenSigTimeoutTime" BU_SG_REL_ BBM SG_ 931 Pto3BadCondition 450;
BA_REL_ "GenSigFirstTimeoutTime" BU_SG_REL_ BBM SG_ 931 PtosStatus_ISig_4 3000;
BA_REL_ "GenSigTimeoutTime" BU_SG_REL_ BBM SG_ 931 PtosStatus_ISig_4 600;
BA_REL_ "GenSigFirstTimeoutTime" BU_SG_REL_ CIOM SG_ 931 PtosStatus_ISig_4 3000;
BA_REL_ "GenSigTimeoutTime" BU_SG_REL_ CIOM SG_ 931 PtosStatus_ISig_4 600;
BA_REL_ "GenSigFirstTimeoutTime" BU_SG_REL_ EMS SG_ 931 PtosStatus_ISig_4 3000;
BA_REL_ "GenSigTimeoutTime" BU_SG_REL_ EMS SG_ 931 PtosStatus_ISig_4 600;
BA_REL_ "GenSigFirstTimeoutTime" BU_SG_REL_ IC3 SG_ 931 PtosStatus_ISig_4 3000;
BA_REL_ "GenSigTimeoutTime" BU_SG_REL_ IC3 SG_ 931 PtosStatus_ISig_4 450;
BA_REL_ "GenSigFirstTimeoutTime" BU_SG_REL_ BBM SG_ 931 FrontWheelDriveAutoStatus_ISig_4 3000;
BA_REL_ "GenSigTimeoutTime" BU_SG_REL_ BBM SG_ 931 FrontWheelDriveAutoStatus_ISig_4 450;
BA_REL_ "GenSigFirstTimeoutTime" BU_SG_REL_ IC3 SG_ 931 FrontWheelDriveAutoStatus_ISig_4 3000;
BA_REL_ "GenSigTimeoutTime" BU_SG_REL_ IC3 SG_ 931 FrontWheelDriveAutoStatus_ISig_4 450;
BA_REL_ "GenSigFirstTimeoutTime" BU_SG_REL_ TECU SG_ 931 Pto1ConsentRequest 3000;
BA_REL_ "GenSigTimeoutTime" BU_SG_REL_ TECU SG_ 931 Pto1ConsentRequest 450;
BA_REL_ "GenSigFirstTimeoutTime" BU_SG_REL_ CIOM SG_ 931 Pto4Indication 3000;
BA_REL_ "GenSigTimeoutTime" BU_SG_REL_ CIOM SG_ 931 Pto4Indication 450;
BA_REL_ "GenSigFirstTimeoutTime" BU_SG_REL_ CIOM SG_ 931 Pto1Indication 3000;
BA_REL_ "GenSigTimeoutTime" BU_SG_REL_ CIOM SG_ 931 Pto1Indication 450;
BA_REL_ "GenSigFirstTimeoutTime" BU_SG_REL_ BBM SG_ 931 Pto3Status_ISig_4 3000;
BA_REL_ "GenSigTimeoutTime" BU_SG_REL_ BBM SG_ 931 Pto3Status_ISig_4 450;
BA_REL_ "GenSigFirstTimeoutTime" BU_SG_REL_ IC3 SG_ 931 Pto3Status_ISig_4 3000;
BA_REL_ "GenSigTimeoutTime" BU_SG_REL_ IC3 SG_ 931 Pto3Status_ISig_4 450;
BA_REL_ "GenSigFirstTimeoutTime" BU_SG_REL_ CIOM SG_ 931 Pto3Status_ISig_4 3000;
BA_REL_ "GenSigTimeoutTime" BU_SG_REL_ CIOM SG_ 931 Pto3Status_ISig_4 450;
BA_REL_ "GenSigFirstTimeoutTime" BU_SG_REL_ CIOM SG_ 931 Pto2Indication 3000;
BA_REL_ "GenSigTimeoutTime" BU_SG_REL_ CIOM SG_ 931 Pto2Indication 450;
BA_REL_ "GenSigFirstTimeoutTime" BU_SG_REL_ BBM SG_ 931 Pto1FeedbackStatus_ISig_4 3000;
BA_REL_ "GenSigTimeoutTime" BU_SG_REL_ BBM SG_ 931 Pto1FeedbackStatus_ISig_4 500;
BA_REL_ "GenSigFirstTimeoutTime" BU_SG_REL_ TECU SG_ 931 TransferCaseOrSplitboxPTOMode_IS 3000;
BA_REL_ "GenSigTimeoutTime" BU_SG_REL_ TECU SG_ 931 TransferCaseOrSplitboxPTOMode_IS 450;
BA_REL_ "GenSigFirstTimeoutTime" BU_SG_REL_ BBM SG_ 931 TransferCaseOrSplitboxPTOMode_IS 3000;
BA_REL_ "GenSigTimeoutTime" BU_SG_REL_ BBM SG_ 931 TransferCaseOrSplitboxPTOMode_IS 450;
BA_REL_ "GenSigFirstTimeoutTime" BU_SG_REL_ IC3 SG_ 931 DirIndRearLamp_Stat_ISig_4 3000;
BA_REL_ "GenSigTimeoutTime" BU_SG_REL_ IC3 SG_ 931 DirIndRearLamp_Stat_ISig_4 450;
BA_REL_ "GenSigFirstTimeoutTime" BU_SG_REL_ CIOM SG_ 931 Pto1Status_ISig_4 3000;
BA_REL_ "GenSigTimeoutTime" BU_SG_REL_ CIOM SG_ 931 Pto1Status_ISig_4 450;
BA_REL_ "GenSigFirstTimeoutTime" BU_SG_REL_ TECU SG_ 931 Pto1Status_ISig_4 3000;
BA_REL_ "GenSigTimeoutTime" BU_SG_REL_ TECU SG_ 931 Pto1Status_ISig_4 450;
BA_REL_ "GenSigFirstTimeoutTime" BU_SG_REL_ BBM SG_ 931 Pto1Status_ISig_4 3000;
BA_REL_ "GenSigTimeoutTime" BU_SG_REL_ BBM SG_ 931 Pto1Status_ISig_4 450;
BA_REL_ "GenSigFirstTimeoutTime" BU_SG_REL_ IC3 SG_ 931 Pto1Status_ISig_4 3000;
BA_REL_ "GenSigTimeoutTime" BU_SG_REL_ IC3 SG_ 931 Pto1Status_ISig_4 450;
BA_REL_ "GenSigFirstTimeoutTime" BU_SG_REL_ BBM SG_ 931 Pto3DrivingRequest 3000;
BA_REL_ "GenSigTimeoutTime" BU_SG_REL_ BBM SG_ 931 Pto3DrivingRequest 450;
BA_REL_ "GenSigFirstTimeoutTime" BU_SG_REL_ IC3 SG_ 731 IdleShutdownTimer 3000;
BA_REL_ "GenSigTimeoutTime" BU_SG_REL_ IC3 SG_ 731 IdleShutdownTimer 270;
BA_REL_ "GenSigFirstTimeoutTime" BU_SG_REL_ EMS SG_ 731 CCBTargetSpeedRequest 3000;
BA_REL_ "GenSigTimeoutTime" BU_SG_REL_ EMS SG_ 731 CCBTargetSpeedRequest 270;
BA_REL_ "GenSigFirstTimeoutTime" BU_SG_REL_ TECU SG_ 731 CCBTargetSpeedRequest 3000;
BA_REL_ "GenSigTimeoutTime" BU_SG_REL_ TECU SG_ 731 CCBTargetSpeedRequest 270;
BA_REL_ "GenSigFirstTimeoutTime" BU_SG_REL_ IC3 SG_ 731 EngineStartControlStatus_ISig_4 3000;
BA_REL_ "GenSigTimeoutTime" BU_SG_REL_ IC3 SG_ 731 EngineStartControlStatus_ISig_4 270;
BA_REL_ "GenSigFirstTimeoutTime" BU_SG_REL_ BBM SG_ 731 EngineStartControlStatus_ISig_4 3000;
BA_REL_ "GenSigTimeoutTime" BU_SG_REL_ BBM SG_ 731 EngineStartControlStatus_ISig_4 270;
BA_REL_ "GenSigFirstTimeoutTime" BU_SG_REL_ TECU SG_ 731 CCTargetSpeedRequest 3000;
BA_REL_ "GenSigTimeoutTime" BU_SG_REL_ TECU SG_ 731 CCTargetSpeedRequest 270;
BA_REL_ "GenSigFirstTimeoutTime" BU_SG_REL_ EMS SG_ 731 CCTargetSpeedRequest 3000;
BA_REL_ "GenSigTimeoutTime" BU_SG_REL_ EMS SG_ 731 CCTargetSpeedRequest 270;
BA_REL_ "GenSigFirstTimeoutTime" BU_SG_REL_ IC3 SG_ 725 StoreIdleValue 3000;
BA_REL_ "GenSigTimeoutTime" BU_SG_REL_ IC3 SG_ 725 StoreIdleValue 270;
BA_REL_ "GenSigFirstTimeoutTime" BU_SG_REL_ EMS SG_ 725 StoreIdleValue 3000;
BA_REL_ "GenSigTimeoutTime" BU_SG_REL_ EMS SG_ 725 StoreIdleValue 270;
BA_REL_ "GenSigFirstTimeoutTime" BU_SG_REL_ IC3 SG_ 725 HeightControlMode_ISig_4 3000;
BA_REL_ "GenSigTimeoutTime" BU_SG_REL_ IC3 SG_ 725 HeightControlMode_ISig_4 270;
BA_REL_ "GenSigFirstTimeoutTime" BU_SG_REL_ EMS SG_ 725 ESCReqEMS_CtrlTrimMode_ISig_4 3000;
BA_REL_ "GenSigTimeoutTime" BU_SG_REL_ EMS SG_ 725 ESCReqEMS_CtrlTrimMode_ISig_4 270;
BA_REL_ "GenSigFirstTimeoutTime" BU_SG_REL_ TECU SG_ 725 ESCReqEMS_CtrlTrimMode_ISig_4 3000;
BA_REL_ "GenSigTimeoutTime" BU_SG_REL_ TECU SG_ 725 ESCReqEMS_CtrlTrimMode_ISig_4 300;
BA_REL_ "GenSigFirstTimeoutTime" BU_SG_REL_ IC3 SG_ 725 ESCReqEMS_CtrlTrimMode_ISig_4 3000;
BA_REL_ "GenSigTimeoutTime" BU_SG_REL_ IC3 SG_ 725 ESCReqEMS_CtrlTrimMode_ISig_4 270;
BA_REL_ "GenSigFirstTimeoutTime" BU_SG_REL_ CIOM SG_ 725 ESCReqESC_CtrlTrimMode_ISig_4 3000;
BA_REL_ "GenSigTimeoutTime" BU_SG_REL_ CIOM SG_ 725 ESCReqESC_CtrlTrimMode_ISig_4 270;
BA_REL_ "GenSigFirstTimeoutTime" BU_SG_REL_ IC3 SG_ 725 ESCReqESC_CtrlTrimMode_ISig_4 3000;
BA_REL_ "GenSigTimeoutTime" BU_SG_REL_ IC3 SG_ 725 ESCReqESC_CtrlTrimMode_ISig_4 270;
BA_REL_ "GenSigFirstTimeoutTime" BU_SG_REL_ BBM SG_ 725 ESCReqESC_CtrlTrimMode_ISig_4 3000;
BA_REL_ "GenSigTimeoutTime" BU_SG_REL_ BBM SG_ 725 ESCReqESC_CtrlTrimMode_ISig_4 270;
BA_REL_ "GenSigFirstTimeoutTime" BU_SG_REL_ IC3 SG_ 725 ESCReqEMS_CtrlTrimStat_ISig_4 3000;
BA_REL_ "GenSigTimeoutTime" BU_SG_REL_ IC3 SG_ 725 ESCReqEMS_CtrlTrimStat_ISig_4 270;
BA_REL_ "GenSigFirstTimeoutTime" BU_SG_REL_ EMS SG_ 725 ESCReqEMS_CtrlTrimStat_ISig_4 3000;
BA_REL_ "GenSigTimeoutTime" BU_SG_REL_ EMS SG_ 725 ESCReqEMS_CtrlTrimStat_ISig_4 270;
BA_REL_ "GenSigFirstTimeoutTime" BU_SG_REL_ TECU SG_ 725 ESCReqEMS_CtrlTrimStat_ISig_4 3000;
BA_REL_ "GenSigTimeoutTime" BU_SG_REL_ TECU SG_ 725 ESCReqEMS_CtrlTrimStat_ISig_4 300;
BA_REL_ "GenSigFirstTimeoutTime" BU_SG_REL_ TECU SG_ 725 TrailerConnected_ISig_4 3000;
BA_REL_ "GenSigTimeoutTime" BU_SG_REL_ TECU SG_ 725 TrailerConnected_ISig_4 500;
BA_REL_ "GenSigFirstTimeoutTime" BU_SG_REL_ IC3 SG_ 725 TrailerConnected_ISig_4 3000;
BA_REL_ "GenSigTimeoutTime" BU_SG_REL_ IC3 SG_ 725 TrailerConnected_ISig_4 500;
BA_REL_ "GenSigFirstTimeoutTime" BU_SG_REL_ EMS SG_ 725 TrailerConnected_ISig_4 3000;
BA_REL_ "GenSigTimeoutTime" BU_SG_REL_ EMS SG_ 725 TrailerConnected_ISig_4 500;
BA_REL_ "GenSigFirstTimeoutTime" BU_SG_REL_ DACU SG_ 725 TrailerConnected_ISig_4 3000;
BA_REL_ "GenSigTimeoutTime" BU_SG_REL_ DACU SG_ 725 TrailerConnected_ISig_4 500;
BA_REL_ "GenSigFirstTimeoutTime" BU_SG_REL_ BBM SG_ 725 TrailerConnected_ISig_4 3000;
BA_REL_ "GenSigTimeoutTime" BU_SG_REL_ BBM SG_ 725 TrailerConnected_ISig_4 500;
BA_REL_ "GenSigFirstTimeoutTime" BU_SG_REL_ BBM SG_ 725 ESCReqESC_CtrlTrimValue_ISig_4 3000;
BA_REL_ "GenSigTimeoutTime" BU_SG_REL_ BBM SG_ 725 ESCReqESC_CtrlTrimValue_ISig_4 270;
BA_REL_ "GenSigFirstTimeoutTime" BU_SG_REL_ IC3 SG_ 725 ESCReqESC_CtrlTrimValue_ISig_4 3000;
BA_REL_ "GenSigTimeoutTime" BU_SG_REL_ IC3 SG_ 725 ESCReqESC_CtrlTrimValue_ISig_4 270;
BA_REL_ "GenSigFirstTimeoutTime" BU_SG_REL_ CIOM SG_ 725 ESCReqESC_CtrlTrimValue_ISig_4 3000;
BA_REL_ "GenSigTimeoutTime" BU_SG_REL_ CIOM SG_ 725 ESCReqESC_CtrlTrimValue_ISig_4 270;
BA_REL_ "GenSigFirstTimeoutTime" BU_SG_REL_ CIOM SG_ 725 ESCReqESC_CtrlTrimStat_ISig_4 3000;
BA_REL_ "GenSigTimeoutTime" BU_SG_REL_ CIOM SG_ 725 ESCReqESC_CtrlTrimStat_ISig_4 270;
BA_REL_ "GenSigFirstTimeoutTime" BU_SG_REL_ BBM SG_ 725 ESCReqESC_CtrlTrimStat_ISig_4 3000;
BA_REL_ "GenSigTimeoutTime" BU_SG_REL_ BBM SG_ 725 ESCReqESC_CtrlTrimStat_ISig_4 270;
BA_REL_ "GenSigFirstTimeoutTime" BU_SG_REL_ IC3 SG_ 725 ESCReqESC_CtrlTrimStat_ISig_4 3000;
BA_REL_ "GenSigTimeoutTime" BU_SG_REL_ IC3 SG_ 725 ESCReqESC_CtrlTrimStat_ISig_4 270;
BA_REL_ "GenSigFirstTimeoutTime" BU_SG_REL_ CIOM SG_ 725 SCLLogicEnable_rqst 3000;
BA_REL_ "GenSigTimeoutTime" BU_SG_REL_ CIOM SG_ 725 SCLLogicEnable_rqst 270;
BA_REL_ "GenSigFirstTimeoutTime" BU_SG_REL_ IC3 SG_ 725 ESCReqESC_CtrlTrimReq_ISig_4 3000;
BA_REL_ "GenSigTimeoutTime" BU_SG_REL_ IC3 SG_ 725 ESCReqESC_CtrlTrimReq_ISig_4 270;
BA_REL_ "GenSigFirstTimeoutTime" BU_SG_REL_ CIOM SG_ 725 ESCReqESC_CtrlTrimReq_ISig_4 3000;
BA_REL_ "GenSigTimeoutTime" BU_SG_REL_ CIOM SG_ 725 ESCReqESC_CtrlTrimReq_ISig_4 270;
BA_REL_ "GenSigFirstTimeoutTime" BU_SG_REL_ BBM SG_ 725 ESCReqESC_CtrlTrimReq_ISig_4 3000;
BA_REL_ "GenSigTimeoutTime" BU_SG_REL_ BBM SG_ 725 ESCReqESC_CtrlTrimReq_ISig_4 270;
BA_REL_ "GenSigFirstTimeoutTime" BU_SG_REL_ DACU SG_ 725 BrakeLight_rqst_ISig_4 3000;
BA_REL_ "GenSigTimeoutTime" BU_SG_REL_ DACU SG_ 725 BrakeLight_rqst_ISig_4 500;
BA_REL_ "GenSigFirstTimeoutTime" BU_SG_REL_ BBM SG_ 725 BrakeLight_rqst_ISig_4 3000;
BA_REL_ "GenSigTimeoutTime" BU_SG_REL_ BBM SG_ 725 BrakeLight_rqst_ISig_4 500;
BA_REL_ "GenSigFirstTimeoutTime" BU_SG_REL_ IC3 SG_ 725 ESCReqEMS_CtrlTrimValue_ISig_4 3000;
BA_REL_ "GenSigTimeoutTime" BU_SG_REL_ IC3 SG_ 725 ESCReqEMS_CtrlTrimValue_ISig_4 270;
BA_REL_ "GenSigFirstTimeoutTime" BU_SG_REL_ TECU SG_ 725 ESCReqEMS_CtrlTrimValue_ISig_4 3000;
BA_REL_ "GenSigTimeoutTime" BU_SG_REL_ TECU SG_ 725 ESCReqEMS_CtrlTrimValue_ISig_4 300;
BA_REL_ "GenSigFirstTimeoutTime" BU_SG_REL_ EMS SG_ 725 ESCReqEMS_CtrlTrimValue_ISig_4 3000;
BA_REL_ "GenSigTimeoutTime" BU_SG_REL_ EMS SG_ 725 ESCReqEMS_CtrlTrimValue_ISig_4 270;
BA_REL_ "GenSigFirstTimeoutTime" BU_SG_REL_ IC3 SG_ 725 ESCReqEMS_CtrlTrimReq_ISig_4 3000;
BA_REL_ "GenSigTimeoutTime" BU_SG_REL_ IC3 SG_ 725 ESCReqEMS_CtrlTrimReq_ISig_4 270;
BA_REL_ "GenSigFirstTimeoutTime" BU_SG_REL_ TECU SG_ 725 ESCReqEMS_CtrlTrimReq_ISig_4 3000;
BA_REL_ "GenSigTimeoutTime" BU_SG_REL_ TECU SG_ 725 ESCReqEMS_CtrlTrimReq_ISig_4 300;
BA_REL_ "GenSigFirstTimeoutTime" BU_SG_REL_ EMS SG_ 725 ESCReqEMS_CtrlTrimReq_ISig_4 3000;
BA_REL_ "GenSigTimeoutTime" BU_SG_REL_ EMS SG_ 725 ESCReqEMS_CtrlTrimReq_ISig_4 270;
BA_REL_ "GenSigFirstTimeoutTime" BU_SG_REL_ IC3 SG_ 721 TrailerTest_stat 3000;
BA_REL_ "GenSigTimeoutTime" BU_SG_REL_ IC3 SG_ 721 TrailerTest_stat 270;
BA_REL_ "GenSigFirstTimeoutTime" BU_SG_REL_ CIOM SG_ 721 Washing_HMI_rqst_ISig_4 3000;
BA_REL_ "GenSigTimeoutTime" BU_SG_REL_ CIOM SG_ 721 Washing_HMI_rqst_ISig_4 270;
BA_REL_ "GenSigFirstTimeoutTime" BU_SG_REL_ IC3 SG_ 721 AuxBrakesDwngrdModeInd_rqst 3000;
BA_REL_ "GenSigTimeoutTime" BU_SG_REL_ IC3 SG_ 721 AuxBrakesDwngrdModeInd_rqst 270;
BA_REL_ "GenSigFirstTimeoutTime" BU_SG_REL_ EMS SG_ 721 XRSLTargetSpeedRequest 3000;
BA_REL_ "GenSigTimeoutTime" BU_SG_REL_ EMS SG_ 721 XRSLTargetSpeedRequest 270;
BA_REL_ "GenSigFirstTimeoutTime" BU_SG_REL_ IC3 SG_ 721 DirInd_StalkStatus_1_ISig_4 3000;
BA_REL_ "GenSigTimeoutTime" BU_SG_REL_ IC3 SG_ 721 DirInd_StalkStatus_1_ISig_4 270;
BA_REL_ "GenSigFirstTimeoutTime" BU_SG_REL_ DACU SG_ 721 XPRsystemstate_ISig_4 3000;
BA_REL_ "GenSigTimeoutTime" BU_SG_REL_ DACU SG_ 721 XPRsystemstate_ISig_4 270;
BA_REL_ "GenSigFirstTimeoutTime" BU_SG_REL_ BBM SG_ 721 XPRsystemstate_ISig_4 3000;
BA_REL_ "GenSigTimeoutTime" BU_SG_REL_ BBM SG_ 721 XPRsystemstate_ISig_4 270;
BA_REL_ "GenSigFirstTimeoutTime" BU_SG_REL_ CIOM SG_ 721 KeyAuthentication_rqst 3000;
BA_REL_ "GenSigTimeoutTime" BU_SG_REL_ CIOM SG_ 721 KeyAuthentication_rqst 270;
BA_REL_ "GenSigFirstTimeoutTime" BU_SG_REL_ CIOM SG_ 721 EngineSpeedControlStatus 3000;
BA_REL_ "GenSigTimeoutTime" BU_SG_REL_ CIOM SG_ 721 EngineSpeedControlStatus 270;
BA_REL_ "GenSigFirstTimeoutTime" BU_SG_REL_ IC3 SG_ 721 EngineSpeedControlStatus 3000;
BA_REL_ "GenSigTimeoutTime" BU_SG_REL_ IC3 SG_ 721 EngineSpeedControlStatus 270;
BA_REL_ "GenSigFirstTimeoutTime" BU_SG_REL_ BBM SG_ 721 EngineSpeedControlStatus 3000;
BA_REL_ "GenSigTimeoutTime" BU_SG_REL_ BBM SG_ 721 EngineSpeedControlStatus 270;
BA_REL_ "GenSigFirstTimeoutTime" BU_SG_REL_ EMS SG_ 721 SecondThrottle 3000;
BA_REL_ "GenSigTimeoutTime" BU_SG_REL_ EMS SG_ 721 SecondThrottle 270;
BA_REL_ "GenSigFirstTimeoutTime" BU_SG_REL_ DACU SG_ 721 SecondThrottle 3000;
BA_REL_ "GenSigTimeoutTime" BU_SG_REL_ DACU SG_ 721 SecondThrottle 270;
BA_REL_ "GenSigFirstTimeoutTime" BU_SG_REL_ BBM SG_ 721 SecondThrottle 3000;
BA_REL_ "GenSigTimeoutTime" BU_SG_REL_ BBM SG_ 721 SecondThrottle 270;
BA_REL_ "GenSigFirstTimeoutTime" BU_SG_REL_ IC3 SG_ 721 PredeliveryModeIndication_cmd_IS 3000;
BA_REL_ "GenSigTimeoutTime" BU_SG_REL_ IC3 SG_ 721 PredeliveryModeIndication_cmd_IS 270;
BA_REL_ "GenSigFirstTimeoutTime" BU_SG_REL_ CIOM SG_ 721 PredeliveryModeIndication_cmd_IS 3000;
BA_REL_ "GenSigTimeoutTime" BU_SG_REL_ CIOM SG_ 721 PredeliveryModeIndication_cmd_IS 270;
BA_REL_ "GenSigFirstTimeoutTime" BU_SG_REL_ IC3 SG_ 721 LoadCutOffIndication_cmd_ISig_4 3000;
BA_REL_ "GenSigTimeoutTime" BU_SG_REL_ IC3 SG_ 721 LoadCutOffIndication_cmd_ISig_4 270;
BA_REL_ "GenSigFirstTimeoutTime" BU_SG_REL_ CIOM SG_ 721 ExitPreDeliveryModeHMI_rqst_ISig 3000;
BA_REL_ "GenSigTimeoutTime" BU_SG_REL_ CIOM SG_ 721 ExitPreDeliveryModeHMI_rqst_ISig 270;
BA_REL_ "GenSigFirstTimeoutTime" BU_SG_REL_ BBM SG_ 721 FdEquipmentStatus1_ISig_4 3000;
BA_REL_ "GenSigTimeoutTime" BU_SG_REL_ BBM SG_ 721 FdEquipmentStatus1_ISig_4 270;
BA_REL_ "GenSigFirstTimeoutTime" BU_SG_REL_ IC3 SG_ 721 FdEquipmentStatus1_ISig_4 3000;
BA_REL_ "GenSigTimeoutTime" BU_SG_REL_ IC3 SG_ 721 FdEquipmentStatus1_ISig_4 270;
BA_REL_ "GenSigFirstTimeoutTime" BU_SG_REL_ CIOM SG_ 721 FdEquipmentStatus1_ISig_4 3000;
BA_REL_ "GenSigTimeoutTime" BU_SG_REL_ CIOM SG_ 721 FdEquipmentStatus1_ISig_4 270;
BA_REL_ "GenSigFirstTimeoutTime" BU_SG_REL_ IC3 SG_ 534 ParkBrakeAlert_ISig_4 3000;
BA_REL_ "GenSigTimeoutTime" BU_SG_REL_ IC3 SG_ 534 ParkBrakeAlert_ISig_4 150;
BA_REL_ "GenSigFirstTimeoutTime" BU_SG_REL_ BBM SG_ 534 ParkBrakeAlert_ISig_4 3000;
BA_REL_ "GenSigTimeoutTime" BU_SG_REL_ BBM SG_ 534 ParkBrakeAlert_ISig_4 150;
BA_REL_ "GenSigFirstTimeoutTime" BU_SG_REL_ IC3 SG_ 534 IntLightMode_CoreRqst_IL_Mode 3000;
BA_REL_ "GenSigTimeoutTime" BU_SG_REL_ IC3 SG_ 534 IntLightMode_CoreRqst_IL_Mode 150;
BA_REL_ "GenSigFirstTimeoutTime" BU_SG_REL_ CIOM SG_ 534 IntLightMode_CoreRqst_IL_Mode 6000;
BA_REL_ "GenSigTimeoutTime" BU_SG_REL_ CIOM SG_ 534 IntLightMode_CoreRqst_IL_Mode 6000;
BA_REL_ "GenSigFirstTimeoutTime" BU_SG_REL_ IC3 SG_ 534 SteeringColumnLockErrInd_rqst 3000;
BA_REL_ "GenSigTimeoutTime" BU_SG_REL_ IC3 SG_ 534 SteeringColumnLockErrInd_rqst 150;
BA_REL_ "GenSigFirstTimeoutTime" BU_SG_REL_ CIOM SG_ 534 ParkingLight_Indication 6000;
BA_REL_ "GenSigTimeoutTime" BU_SG_REL_ CIOM SG_ 534 ParkingLight_Indication 6000;
BA_REL_ "GenSigFirstTimeoutTime" BU_SG_REL_ CIOM SG_ 534 DaytimeRunningLight_Indication 6000;
BA_REL_ "GenSigTimeoutTime" BU_SG_REL_ CIOM SG_ 534 DaytimeRunningLight_Indication 6000;
BA_REL_ "GenSigFirstTimeoutTime" BU_SG_REL_ IC3 SG_ 534 EPBBackupMode_ISig_4 3000;
BA_REL_ "GenSigTimeoutTime" BU_SG_REL_ IC3 SG_ 534 EPBBackupMode_ISig_4 150;
BA_REL_ "GenSigFirstTimeoutTime" BU_SG_REL_ CIOM SG_ 534 WiperModeStatus_ISig_4 3000;
BA_REL_ "GenSigTimeoutTime" BU_SG_REL_ CIOM SG_ 534 WiperModeStatus_ISig_4 500;
BA_REL_ "GenSigFirstTimeoutTime" BU_SG_REL_ DACU SG_ 534 WiperModeStatus_ISig_4 3000;
BA_REL_ "GenSigTimeoutTime" BU_SG_REL_ DACU SG_ 534 WiperModeStatus_ISig_4 500;
BA_REL_ "GenSigFirstTimeoutTime" BU_SG_REL_ IC3 SG_ 534 WiperModeStatus_ISig_4 3000;
BA_REL_ "GenSigTimeoutTime" BU_SG_REL_ IC3 SG_ 534 WiperModeStatus_ISig_4 500;
BA_REL_ "GenSigFirstTimeoutTime" BU_SG_REL_ BBM SG_ 534 WiperModeStatus_ISig_4 3000;
BA_REL_ "GenSigTimeoutTime" BU_SG_REL_ BBM SG_ 534 WiperModeStatus_ISig_4 500;
BA_REL_ "GenSigFirstTimeoutTime" BU_SG_REL_ CIOM SG_ 534 FrontFog_Indication_ISig_4 6000;
BA_REL_ "GenSigTimeoutTime" BU_SG_REL_ CIOM SG_ 534 FrontFog_Indication_ISig_4 6000;
BA_REL_ "GenSigFirstTimeoutTime" BU_SG_REL_ IC3 SG_ 534 PBReleaseAcceptance_stat_ISig_4 3000;
BA_REL_ "GenSigTimeoutTime" BU_SG_REL_ IC3 SG_ 534 PBReleaseAcceptance_stat_ISig_4 150;
BA_REL_ "GenSigFirstTimeoutTime" BU_SG_REL_ CIOM SG_ 534 DrivingLightPlus_Indication 6000;
BA_REL_ "GenSigTimeoutTime" BU_SG_REL_ CIOM SG_ 534 DrivingLightPlus_Indication 6000;
BA_REL_ "GenSigFirstTimeoutTime" BU_SG_REL_ CIOM SG_ 534 IntLightMode_CoreRqst_EventFlag 6000;
BA_REL_ "GenSigTimeoutTime" BU_SG_REL_ CIOM SG_ 534 IntLightMode_CoreRqst_EventFlag 6000;
BA_REL_ "GenSigFirstTimeoutTime" BU_SG_REL_ IC3 SG_ 534 IntLightMode_CoreRqst_EventFlag 3000;
BA_REL_ "GenSigTimeoutTime" BU_SG_REL_ IC3 SG_ 534 IntLightMode_CoreRqst_EventFlag 150;
BA_REL_ "GenSigFirstTimeoutTime" BU_SG_REL_ EMS SG_ 534 ParkingBrake_stat_ISig_4 3000;
BA_REL_ "GenSigTimeoutTime" BU_SG_REL_ EMS SG_ 534 ParkingBrake_stat_ISig_4 500;
BA_REL_ "GenSigFirstTimeoutTime" BU_SG_REL_ DACU SG_ 534 ParkingBrake_stat_ISig_4 3000;
BA_REL_ "GenSigTimeoutTime" BU_SG_REL_ DACU SG_ 534 ParkingBrake_stat_ISig_4 500;
BA_REL_ "GenSigFirstTimeoutTime" BU_SG_REL_ IC3 SG_ 534 ParkingBrake_stat_ISig_4 3000;
BA_REL_ "GenSigTimeoutTime" BU_SG_REL_ IC3 SG_ 534 ParkingBrake_stat_ISig_4 500;
BA_REL_ "GenSigFirstTimeoutTime" BU_SG_REL_ CIOM SG_ 534 ParkingBrake_stat_ISig_4 3000;
BA_REL_ "GenSigTimeoutTime" BU_SG_REL_ CIOM SG_ 534 ParkingBrake_stat_ISig_4 500;
BA_REL_ "GenSigFirstTimeoutTime" BU_SG_REL_ BBM SG_ 534 ParkingBrake_stat_ISig_4 3000;
BA_REL_ "GenSigTimeoutTime" BU_SG_REL_ BBM SG_ 534 ParkingBrake_stat_ISig_4 500;
BA_REL_ "GenSigFirstTimeoutTime" BU_SG_REL_ TECU SG_ 534 ParkingBrake_stat_ISig_4 3000;
BA_REL_ "GenSigTimeoutTime" BU_SG_REL_ TECU SG_ 534 ParkingBrake_stat_ISig_4 500;
BA_REL_ "GenSigFirstTimeoutTime" BU_SG_REL_ CIOM SG_ 534 DrivingLight_Indication 6000;
BA_REL_ "GenSigTimeoutTime" BU_SG_REL_ CIOM SG_ 534 DrivingLight_Indication 6000;
BA_REL_ "GenSigFirstTimeoutTime" BU_SG_REL_ CIOM SG_ 534 MirrorHeatingMode_ISig_4 6000;
BA_REL_ "GenSigTimeoutTime" BU_SG_REL_ CIOM SG_ 534 MirrorHeatingMode_ISig_4 6000;
BA_REL_ "GenSigFirstTimeoutTime" BU_SG_REL_ CIOM SG_ 534 RearFog_Indication 6000;
BA_REL_ "GenSigTimeoutTime" BU_SG_REL_ CIOM SG_ 534 RearFog_Indication 6000;
BA_REL_ "GenSigFirstTimeoutTime" BU_SG_REL_ CIOM SG_ 534 InteriorLightLevelInd_cmd 6000;
BA_REL_ "GenSigTimeoutTime" BU_SG_REL_ CIOM SG_ 534 InteriorLightLevelInd_cmd 6000;
BA_REL_ "GenSigFirstTimeoutTime" BU_SG_REL_ IC3 SG_ 532 LiftAxle2LiftFuncSelected_ISig_4 3000;
BA_REL_ "GenSigTimeoutTime" BU_SG_REL_ IC3 SG_ 532 LiftAxle2LiftFuncSelected_ISig_4 150;
BA_REL_ "GenSigFirstTimeoutTime" BU_SG_REL_ CIOM SG_ 532 StopLevelChangeAck_ISig_4 3000;
BA_REL_ "GenSigTimeoutTime" BU_SG_REL_ CIOM SG_ 532 StopLevelChangeAck_ISig_4 150;
BA_REL_ "GenSigFirstTimeoutTime" BU_SG_REL_ CIOM SG_ 532 HeightAdjustmentAllowed_ISig_4 3000;
BA_REL_ "GenSigTimeoutTime" BU_SG_REL_ CIOM SG_ 532 HeightAdjustmentAllowed_ISig_4 150;
BA_REL_ "GenSigFirstTimeoutTime" BU_SG_REL_ IC3 SG_ 532 LiftAxle2LowerACK_ISig_4 3000;
BA_REL_ "GenSigTimeoutTime" BU_SG_REL_ IC3 SG_ 532 LiftAxle2LowerACK_ISig_4 150;
BA_REL_ "GenSigFirstTimeoutTime" BU_SG_REL_ CIOM SG_ 532 LiftAxle2UpRequestACK_ISig_4 3000;
BA_REL_ "GenSigTimeoutTime" BU_SG_REL_ CIOM SG_ 532 LiftAxle2UpRequestACK_ISig_4 150;
BA_REL_ "GenSigFirstTimeoutTime" BU_SG_REL_ IC3 SG_ 532 LiftAxle2UpRequestACK_ISig_4 3000;
BA_REL_ "GenSigTimeoutTime" BU_SG_REL_ IC3 SG_ 532 LiftAxle2UpRequestACK_ISig_4 150;
BA_REL_ "GenSigFirstTimeoutTime" BU_SG_REL_ CIOM SG_ 532 RideHeightStatus_ISig_4 3000;
BA_REL_ "GenSigTimeoutTime" BU_SG_REL_ CIOM SG_ 532 RideHeightStatus_ISig_4 150;
BA_REL_ "GenSigFirstTimeoutTime" BU_SG_REL_ BBM SG_ 532 RideHeightStatus_ISig_4 3000;
BA_REL_ "GenSigTimeoutTime" BU_SG_REL_ BBM SG_ 532 RideHeightStatus_ISig_4 150;
BA_REL_ "GenSigFirstTimeoutTime" BU_SG_REL_ IC3 SG_ 532 RideHeightOutsideTargetRange_ISi 3000;
BA_REL_ "GenSigTimeoutTime" BU_SG_REL_ IC3 SG_ 532 RideHeightOutsideTargetRange_ISi 150;
BA_REL_ "GenSigFirstTimeoutTime" BU_SG_REL_ CIOM SG_ 532 RideHeightOutsideTargetRange_ISi 3000;
BA_REL_ "GenSigTimeoutTime" BU_SG_REL_ CIOM SG_ 532 RideHeightOutsideTargetRange_ISi 150;
BA_REL_ "GenSigFirstTimeoutTime" BU_SG_REL_ CIOM SG_ 532 LoadDistributionFuncSelected_ISi 3000;
BA_REL_ "GenSigTimeoutTime" BU_SG_REL_ CIOM SG_ 532 LoadDistributionFuncSelected_ISi 150;
BA_REL_ "GenSigFirstTimeoutTime" BU_SG_REL_ CIOM SG_ 532 RideHeightStorageAck_ISig_4 3000;
BA_REL_ "GenSigTimeoutTime" BU_SG_REL_ CIOM SG_ 532 RideHeightStorageAck_ISig_4 150;
BA_REL_ "GenSigFirstTimeoutTime" BU_SG_REL_ IC3 SG_ 532 LiftAxle2AutoLiftSelected_ISig_4 3000;
BA_REL_ "GenSigTimeoutTime" BU_SG_REL_ IC3 SG_ 532 LiftAxle2AutoLiftSelected_ISig_4 150;
BA_REL_ "GenSigFirstTimeoutTime" BU_SG_REL_ IC3 SG_ 532 LiftAxle1UpRequestACK_ISig_4 3000;
BA_REL_ "GenSigTimeoutTime" BU_SG_REL_ IC3 SG_ 532 LiftAxle1UpRequestACK_ISig_4 150;
BA_REL_ "GenSigFirstTimeoutTime" BU_SG_REL_ CIOM SG_ 532 LiftAxle1UpRequestACK_ISig_4 3000;
BA_REL_ "GenSigTimeoutTime" BU_SG_REL_ CIOM SG_ 532 LiftAxle1UpRequestACK_ISig_4 150;
BA_REL_ "GenSigFirstTimeoutTime" BU_SG_REL_ BBM SG_ 532 LiftAxle1PositionStatus_ISig_4 3000;
BA_REL_ "GenSigTimeoutTime" BU_SG_REL_ BBM SG_ 532 LiftAxle1PositionStatus_ISig_4 150;
BA_REL_ "GenSigFirstTimeoutTime" BU_SG_REL_ CIOM SG_ 532 LiftAxle1PositionStatus_ISig_4 3000;
BA_REL_ "GenSigTimeoutTime" BU_SG_REL_ CIOM SG_ 532 LiftAxle1PositionStatus_ISig_4 150;
BA_REL_ "GenSigFirstTimeoutTime" BU_SG_REL_ TECU SG_ 532 LiftAxle1PositionStatus_ISig_4 3000;
BA_REL_ "GenSigTimeoutTime" BU_SG_REL_ TECU SG_ 532 LiftAxle1PositionStatus_ISig_4 500;
BA_REL_ "GenSigFirstTimeoutTime" BU_SG_REL_ DACU SG_ 532 LiftAxle1PositionStatus_ISig_4 3000;
BA_REL_ "GenSigTimeoutTime" BU_SG_REL_ DACU SG_ 532 LiftAxle1PositionStatus_ISig_4 600;
BA_REL_ "GenSigFirstTimeoutTime" BU_SG_REL_ IC3 SG_ 532 LiftAxle1PositionStatus_ISig_4 3000;
BA_REL_ "GenSigTimeoutTime" BU_SG_REL_ IC3 SG_ 532 LiftAxle1PositionStatus_ISig_4 150;
BA_REL_ "GenSigFirstTimeoutTime" BU_SG_REL_ IC3 SG_ 532 LiftAxle1LowerACK_ISig_4 3000;
BA_REL_ "GenSigTimeoutTime" BU_SG_REL_ IC3 SG_ 532 LiftAxle1LowerACK_ISig_4 150;
BA_REL_ "GenSigFirstTimeoutTime" BU_SG_REL_ IC3 SG_ 532 LiftAxle1AutoLiftSelected_ISig_4 3000;
BA_REL_ "GenSigTimeoutTime" BU_SG_REL_ IC3 SG_ 532 LiftAxle1AutoLiftSelected_ISig_4 150;
BA_REL_ "GenSigFirstTimeoutTime" BU_SG_REL_ IC3 SG_ 532 LiftAxle2PositionStatus_ISig_4 3000;
BA_REL_ "GenSigTimeoutTime" BU_SG_REL_ IC3 SG_ 532 LiftAxle2PositionStatus_ISig_4 150;
BA_REL_ "GenSigFirstTimeoutTime" BU_SG_REL_ BBM SG_ 532 LiftAxle2PositionStatus_ISig_4 3000;
BA_REL_ "GenSigTimeoutTime" BU_SG_REL_ BBM SG_ 532 LiftAxle2PositionStatus_ISig_4 150;
BA_REL_ "GenSigFirstTimeoutTime" BU_SG_REL_ CIOM SG_ 532 LiftAxle2PositionStatus_ISig_4 3000;
BA_REL_ "GenSigTimeoutTime" BU_SG_REL_ CIOM SG_ 532 LiftAxle2PositionStatus_ISig_4 150;
BA_REL_ "GenSigFirstTimeoutTime" BU_SG_REL_ TECU SG_ 532 LevelControlInformation_ISig_4 3000;
BA_REL_ "GenSigTimeoutTime" BU_SG_REL_ TECU SG_ 532 LevelControlInformation_ISig_4 500;
BA_REL_ "GenSigFirstTimeoutTime" BU_SG_REL_ IC3 SG_ 532 LevelControlInformation_ISig_4 3000;
BA_REL_ "GenSigTimeoutTime" BU_SG_REL_ IC3 SG_ 532 LevelControlInformation_ISig_4 500;
BA_REL_ "GenSigFirstTimeoutTime" BU_SG_REL_ CIOM SG_ 532 LevelControlInformation_ISig_4 3000;
BA_REL_ "GenSigTimeoutTime" BU_SG_REL_ CIOM SG_ 532 LevelControlInformation_ISig_4 500;
BA_REL_ "GenSigFirstTimeoutTime" BU_SG_REL_ IC3 SG_ 532 LiftAxle1LiftFuncSelected_ISig_4 3000;
BA_REL_ "GenSigTimeoutTime" BU_SG_REL_ IC3 SG_ 532 LiftAxle1LiftFuncSelected_ISig_4 150;
BA_REL_ "GenSigFirstTimeoutTime" BU_SG_REL_ CIOM SG_ 532 LoadDistributionChangeACK_ISig_4 3000;
BA_REL_ "GenSigTimeoutTime" BU_SG_REL_ CIOM SG_ 532 LoadDistributionChangeACK_ISig_4 150;
BA_REL_ "GenSigFirstTimeoutTime" BU_SG_REL_ IC3 SG_ 532 LoadDistributionChangeACK_ISig_4 3000;
BA_REL_ "GenSigTimeoutTime" BU_SG_REL_ IC3 SG_ 532 LoadDistributionChangeACK_ISig_4 150;
BA_REL_ "GenSigFirstTimeoutTime" BU_SG_REL_ CIOM SG_ 532 RampLevelStorageAck_ISig_4 3000;
BA_REL_ "GenSigTimeoutTime" BU_SG_REL_ CIOM SG_ 532 RampLevelStorageAck_ISig_4 150;
BA_REL_ "GenSigFirstTimeoutTime" BU_SG_REL_ BBM SG_ 532 LoadDistributionSelected_ISig_4 3000;
BA_REL_ "GenSigTimeoutTime" BU_SG_REL_ BBM SG_ 532 LoadDistributionSelected_ISig_4 150;
BA_REL_ "GenSigFirstTimeoutTime" BU_SG_REL_ CIOM SG_ 532 LoadDistributionSelected_ISig_4 3000;
BA_REL_ "GenSigTimeoutTime" BU_SG_REL_ CIOM SG_ 532 LoadDistributionSelected_ISig_4 150;
BA_REL_ "GenSigFirstTimeoutTime" BU_SG_REL_ CIOM SG_ 532 RideHeightFunctionStatus_ISig_4 3000;
BA_REL_ "GenSigTimeoutTime" BU_SG_REL_ CIOM SG_ 532 RideHeightFunctionStatus_ISig_4 150;
BA_REL_ "GenSigFirstTimeoutTime" BU_SG_REL_ IC3 SG_ 520 TransmLowRangeSenseSwitch_ISig_4 3000;
BA_REL_ "GenSigTimeoutTime" BU_SG_REL_ IC3 SG_ 520 TransmLowRangeSenseSwitch_ISig_4 120;
BA_REL_ "GenSigFirstTimeoutTime" BU_SG_REL_ EMS SG_ 520 TransmLowRangeSenseSwitch_ISig_4 3000;
BA_REL_ "GenSigTimeoutTime" BU_SG_REL_ EMS SG_ 520 TransmLowRangeSenseSwitch_ISig_4 120;
BA_REL_ "GenSigFirstTimeoutTime" BU_SG_REL_ TECU SG_ 520 TransmSystemPowerDown_rqst 3000;
BA_REL_ "GenSigTimeoutTime" BU_SG_REL_ TECU SG_ 520 TransmSystemPowerDown_rqst 500;
BA_REL_ "GenSigFirstTimeoutTime" BU_SG_REL_ BBM SG_ 520 TransmissionNeutralSwitch_ISig_4 3000;
BA_REL_ "GenSigTimeoutTime" BU_SG_REL_ BBM SG_ 520 TransmissionNeutralSwitch_ISig_4 500;
BA_REL_ "GenSigFirstTimeoutTime" BU_SG_REL_ EMS SG_ 520 TransmissionNeutralSwitch_ISig_4 3000;
BA_REL_ "GenSigTimeoutTime" BU_SG_REL_ EMS SG_ 520 TransmissionNeutralSwitch_ISig_4 500;
BA_REL_ "GenSigFirstTimeoutTime" BU_SG_REL_ EMS SG_ 520 SecuredNeutralPosition_ISig_4 3000;
BA_REL_ "GenSigTimeoutTime" BU_SG_REL_ EMS SG_ 520 SecuredNeutralPosition_ISig_4 500;
BA_REL_ "GenSigFirstTimeoutTime" BU_SG_REL_ IC3 SG_ 520 SecuredNeutralPosition_ISig_4 3000;
BA_REL_ "GenSigTimeoutTime" BU_SG_REL_ IC3 SG_ 520 SecuredNeutralPosition_ISig_4 500;
BA_REL_ "GenSigFirstTimeoutTime" BU_SG_REL_ BBM SG_ 520 SecuredNeutralPosition_ISig_4 6000;
BA_REL_ "GenSigTimeoutTime" BU_SG_REL_ BBM SG_ 520 SecuredNeutralPosition_ISig_4 500;
BA_REL_ "GenSigFirstTimeoutTime" BU_SG_REL_ EMS SG_ 520 EngineStopRequest_ISig_4 3000;
BA_REL_ "GenSigTimeoutTime" BU_SG_REL_ EMS SG_ 520 EngineStopRequest_ISig_4 120;
BA_REL_ "GenSigFirstTimeoutTime" BU_SG_REL_ DACU SG_ 520 ReverseGearEngaged_ISig_4 3000;
BA_REL_ "GenSigTimeoutTime" BU_SG_REL_ DACU SG_ 520 ReverseGearEngaged_ISig_4 500;
BA_REL_ "GenSigFirstTimeoutTime" BU_SG_REL_ EMS SG_ 520 ReverseGearEngaged_ISig_4 3000;
BA_REL_ "GenSigTimeoutTime" BU_SG_REL_ EMS SG_ 520 ReverseGearEngaged_ISig_4 500;
BA_REL_ "GenSigFirstTimeoutTime" BU_SG_REL_ CIOM SG_ 520 ReverseGearEngaged_ISig_4 3000;
BA_REL_ "GenSigTimeoutTime" BU_SG_REL_ CIOM SG_ 520 ReverseGearEngaged_ISig_4 500;
BA_REL_ "GenSigFirstTimeoutTime" BU_SG_REL_ BBM SG_ 520 ReverseGearEngaged_ISig_4 3000;
BA_REL_ "GenSigTimeoutTime" BU_SG_REL_ BBM SG_ 520 ReverseGearEngaged_ISig_4 500;
BA_REL_ "GenSigFirstTimeoutTime" BU_SG_REL_ IC3 SG_ 520 ReverseGearEngaged_ISig_4 3000;
BA_REL_ "GenSigTimeoutTime" BU_SG_REL_ IC3 SG_ 520 ReverseGearEngaged_ISig_4 500;
BA_REL_ "GenSigFirstTimeoutTime" BU_SG_REL_ EMS SG_ 520 EngineCrankRequest 3000;
BA_REL_ "GenSigTimeoutTime" BU_SG_REL_ EMS SG_ 520 EngineCrankRequest 120;
BA_REL_ "GenSigFirstTimeoutTime" BU_SG_REL_ TECU SG_ 520 ParkBrakeActuationStatus_ISig_4 3000;
BA_REL_ "GenSigTimeoutTime" BU_SG_REL_ TECU SG_ 520 ParkBrakeActuationStatus_ISig_4 500;
BA_REL_ "GenSigFirstTimeoutTime" BU_SG_REL_ DACU SG_ 520 ParkBrakeActuationStatus_ISig_4 3000;
BA_REL_ "GenSigTimeoutTime" BU_SG_REL_ DACU SG_ 520 ParkBrakeActuationStatus_ISig_4 120;
BA_REL_ "GenSigFirstTimeoutTime" BU_SG_REL_ BBM SG_ 520 ParkBrakeActuationStatus_ISig_4 3000;
BA_REL_ "GenSigTimeoutTime" BU_SG_REL_ BBM SG_ 520 ParkBrakeActuationStatus_ISig_4 500;
BA_REL_ "GenSigFirstTimeoutTime" BU_SG_REL_ IC3 SG_ 520 ParkBrakeActuationStatus_ISig_4 3000;
BA_REL_ "GenSigTimeoutTime" BU_SG_REL_ IC3 SG_ 520 ParkBrakeActuationStatus_ISig_4 500;
BA_REL_ "GenSigFirstTimeoutTime" BU_SG_REL_ EMS SG_ 520 EnginePreheat_rqst 3000;
BA_REL_ "GenSigTimeoutTime" BU_SG_REL_ EMS SG_ 520 EnginePreheat_rqst 120;
BA_REL_ "GenSigFirstTimeoutTime" BU_SG_REL_ EMS SG_ 520 AcceleratorPedalPositionBackup 3000;
BA_REL_ "GenSigTimeoutTime" BU_SG_REL_ EMS SG_ 520 AcceleratorPedalPositionBackup 120;
BA_REL_ "GenSigFirstTimeoutTime" BU_SG_REL_ TECU SG_ 520 AcceleratorPedalPositionBackup 3000;
BA_REL_ "GenSigTimeoutTime" BU_SG_REL_ TECU SG_ 520 AcceleratorPedalPositionBackup 120;
BA_REL_ "GenSigFirstTimeoutTime" BU_SG_REL_ CIOM SG_ 520 KeyPosition_ISig_4 3000;
BA_REL_ "GenSigTimeoutTime" BU_SG_REL_ CIOM SG_ 520 KeyPosition_ISig_4 120;
BA_REL_ "GenSigFirstTimeoutTime" BU_SG_REL_ IC3 SG_ 520 KeyPosition_ISig_4 3000;
BA_REL_ "GenSigTimeoutTime" BU_SG_REL_ IC3 SG_ 520 KeyPosition_ISig_4 120;
BA_REL_ "GenSigFirstTimeoutTime" BU_SG_REL_ IC3 SG_ 520 GearSplit_Status_ISig_4 3000;
BA_REL_ "GenSigTimeoutTime" BU_SG_REL_ IC3 SG_ 520 GearSplit_Status_ISig_4 500;
BA_REL_ "GenSigFirstTimeoutTime" BU_SG_REL_ BBM SG_ 520 GearSplit_Status_ISig_4 3000;
BA_REL_ "GenSigTimeoutTime" BU_SG_REL_ BBM SG_ 520 GearSplit_Status_ISig_4 500;
BA_REL_ "GenSigFirstTimeoutTime" BU_SG_REL_ CIOM SG_ 520 FerryFunctionSwitchChangeACK_ISi 3000;
BA_REL_ "GenSigTimeoutTime" BU_SG_REL_ CIOM SG_ 520 FerryFunctionSwitchChangeACK_ISi 120;
BA_REL_ "GenSigFirstTimeoutTime" BU_SG_REL_ IC3 SG_ 520 DirectionIndication_cmd 3000;
BA_REL_ "GenSigTimeoutTime" BU_SG_REL_ IC3 SG_ 520 DirectionIndication_cmd 120;
BA_REL_ "GenSigFirstTimeoutTime" BU_SG_REL_ IC3 SG_ 520 IdleShutdownWarning 3000;
BA_REL_ "GenSigTimeoutTime" BU_SG_REL_ IC3 SG_ 520 IdleShutdownWarning 120;
BA_REL_ "GenSigFirstTimeoutTime" BU_SG_REL_ CIOM SG_ 520 BackToDriveReqACK_ISig_4 3000;
BA_REL_ "GenSigTimeoutTime" BU_SG_REL_ CIOM SG_ 520 BackToDriveReqACK_ISig_4 120;
BA_REL_ "GenSigFirstTimeoutTime" BU_SG_REL_ EMS SG_ 520 EngineSystemPowerDownRequest_ISi 3000;
BA_REL_ "GenSigTimeoutTime" BU_SG_REL_ EMS SG_ 520 EngineSystemPowerDownRequest_ISi 120;
BA_REL_ "GenSigFirstTimeoutTime" BU_SG_REL_ IC3 SG_ 520 EngineSystemPowerDownRequest_ISi 3000;
BA_REL_ "GenSigTimeoutTime" BU_SG_REL_ IC3 SG_ 520 EngineSystemPowerDownRequest_ISi 120;
BA_REL_ "GenSigFirstTimeoutTime" BU_SG_REL_ DACU SG_ 1283 TrafficSitPathExecSta_Type 3000;
BA_REL_ "GenSigTimeoutTime" BU_SG_REL_ DACU SG_ 1283 TrafficSitPathExecSta_Type 600;
BA_REL_ "GenSigFirstTimeoutTime" BU_SG_REL_ DACU SG_ 1283 TrafficSitPathExecSta_Speed 3000;
BA_REL_ "GenSigTimeoutTime" BU_SG_REL_ DACU SG_ 1283 TrafficSitPathExecSta_Speed 600;
BA_REL_ "GenSigFirstTimeoutTime" BU_SG_REL_ DACU SG_ 1283 TrafficSitPathExecSta_Distance 3000;
BA_REL_ "GenSigTimeoutTime" BU_SG_REL_ DACU SG_ 1283 TrafficSitPathExecSta_Distance 600;
BA_REL_ "GenSigFirstTimeoutTime" BU_SG_REL_ IC3 SG_ 1463 TECU_Available_Log_ISig_4 60000;
BA_REL_ "GenSigTimeoutTime" BU_SG_REL_ IC3 SG_ 1463 TECU_Available_Log_ISig_4 30000;
BA_REL_ "GenSigFirstTimeoutTime" BU_SG_REL_ IC3 SG_ 1249 OilLevelDrvInstr_IncorrEngSpe 12000;
BA_REL_ "GenSigTimeoutTime" BU_SG_REL_ IC3 SG_ 1249 OilLevelDrvInstr_IncorrEngSpe 3000;
BA_REL_ "GenSigFirstTimeoutTime" BU_SG_REL_ IC3 SG_ 1249 OilLevelDrvInstr_StopVehicle 12000;
BA_REL_ "GenSigTimeoutTime" BU_SG_REL_ IC3 SG_ 1249 OilLevelDrvInstr_StopVehicle 3000;
BA_REL_ "GenSigFirstTimeoutTime" BU_SG_REL_ VMCU SG_ 1249 SchwungStatus 12000;
BA_REL_ "GenSigTimeoutTime" BU_SG_REL_ VMCU SG_ 1249 SchwungStatus 3000;
BA_REL_ "GenSigFirstTimeoutTime" BU_SG_REL_ IC3 SG_ 1249 HillDataCtrlTECU_State_ISig_4 12000;
BA_REL_ "GenSigTimeoutTime" BU_SG_REL_ IC3 SG_ 1249 HillDataCtrlTECU_State_ISig_4 3000;
BA_REL_ "GenSigFirstTimeoutTime" BU_SG_REL_ IC3 SG_ 1249 OilLevelDrvInstr_Wait60SecTxt 12000;
BA_REL_ "GenSigTimeoutTime" BU_SG_REL_ IC3 SG_ 1249 OilLevelDrvInstr_Wait60SecTxt 3000;
BA_REL_ "GenSigFirstTimeoutTime" BU_SG_REL_ IC3 SG_ 1249 ClutchAbuseStatus 12000;
BA_REL_ "GenSigTimeoutTime" BU_SG_REL_ IC3 SG_ 1249 ClutchAbuseStatus 3000;
BA_REL_ "GenSigFirstTimeoutTime" BU_SG_REL_ IC3 SG_ 1249 TransmissionSplitboxPTOMode 12000;
BA_REL_ "GenSigTimeoutTime" BU_SG_REL_ IC3 SG_ 1249 TransmissionSplitboxPTOMode 3000;
BA_REL_ "GenSigFirstTimeoutTime" BU_SG_REL_ DACU SG_ 1249 CACCSuitability 12000;
BA_REL_ "GenSigTimeoutTime" BU_SG_REL_ DACU SG_ 1249 CACCSuitability 3000;
BA_REL_ "GenSigFirstTimeoutTime" BU_SG_REL_ IC3 SG_ 1249 ClutchCalibration_stat 12000;
BA_REL_ "GenSigTimeoutTime" BU_SG_REL_ IC3 SG_ 1249 ClutchCalibration_stat 3000;
BA_REL_ "GenSigFirstTimeoutTime" BU_SG_REL_ IC3 SG_ 1249 OilLevelDrvInstr_ChangeGearTxt 12000;
BA_REL_ "GenSigTimeoutTime" BU_SG_REL_ IC3 SG_ 1249 OilLevelDrvInstr_ChangeGearTxt 3000;
BA_REL_ "GenSigFirstTimeoutTime" BU_SG_REL_ IC3 SG_ 1249 OilLevelDrvInstr_NotHorizonTxt 12000;
BA_REL_ "GenSigTimeoutTime" BU_SG_REL_ IC3 SG_ 1249 OilLevelDrvInstr_NotHorizonTxt 3000;
BA_REL_ "GenSigFirstTimeoutTime" BU_SG_REL_ IC3 SG_ 1249 ISeeStatus 12000;
BA_REL_ "GenSigTimeoutTime" BU_SG_REL_ IC3 SG_ 1249 ISeeStatus 3000;
BA_REL_ "GenSigFirstTimeoutTime" BU_SG_REL_ DACU SG_ 1249 ISeeStatus 12000;
BA_REL_ "GenSigTimeoutTime" BU_SG_REL_ DACU SG_ 1249 ISeeStatus 3000;
BA_REL_ "GenSigFirstTimeoutTime" BU_SG_REL_ IC3 SG_ 1249 EcoRollEnabledStatus 12000;
BA_REL_ "GenSigTimeoutTime" BU_SG_REL_ IC3 SG_ 1249 EcoRollEnabledStatus 3000;
BA_REL_ "GenSigFirstTimeoutTime" BU_SG_REL_ IC3 SG_ 1249 OilLevelDrvInstr_OilTempTxt 12000;
BA_REL_ "GenSigTimeoutTime" BU_SG_REL_ IC3 SG_ 1249 OilLevelDrvInstr_OilTempTxt 3000;
BA_REL_ "GenSigFirstTimeoutTime" BU_SG_REL_ IC3 SG_ 1249 HillDataCtrlTECU_AckCnt_ISig_4 12000;
BA_REL_ "GenSigTimeoutTime" BU_SG_REL_ IC3 SG_ 1249 HillDataCtrlTECU_AckCnt_ISig_4 3000;
VAL_ 1416 WasherFluidLevel_ISig_4 7 "WasherFluidLevel_NotAvailable" 6 "WasherFluidLevel_ErrorIndicator" 5 "WasherFluidLevel_Spare_02" 4 "WasherFluidLevel_Spare_01" 3 "WasherFluidLevel_Spare" 2 "WasherFluidLevel_Level2" 1 "WasherFluidLevel_Level1" 0 "WasherFluidLevel_Level0" ;
VAL_ 1416 EngSpeedGreenAreaMode_ISig_4 7 "EngSpeedGreenAreaMode_NotAvailable" 6 "EngSpeedGreenAreaMode_Error" 5 "EngSpeedGreenAreaMode_Spare3" 4 "EngSpeedGreenAreaMode_Spare2" 3 "EngSpeedGreenAreaMode_Spare1" 2 "EngSpeedGreenAreaMode_Above" 1 "EngSpeedGreenAreaMode_Within" 0 "EngSpeedGreenAreaMode_Below" ;
VAL_ 1050 CabRoofSignLightFeedback_stat 3 "OffOn_NotAvailable" 2 "OffOn_Error" 1 "OffOn_On" 0 "OffOn_Off" ;
VAL_ 1050 CabExtraSideWrknLightFdbk_stat_I 3 "OffOn_NotAvailable" 2 "OffOn_Error" 1 "OffOn_On" 0 "OffOn_Off" ;
VAL_ 1050 CabWrknLightChassisFdbk_stat_ISi 3 "OffOn_NotAvailable" 2 "OffOn_Error" 1 "OffOn_On" 0 "OffOn_Off" ;
VAL_ 1050 CabTrailerBodyLgthnFdbk_stat 3 "OffOn_NotAvailable" 2 "OffOn_Error" 1 "OffOn_On" 0 "OffOn_Off" ;
VAL_ 1050 DiffLockInterWhlStatusSplitBox_I 3 "DisengageEngage_NotAvailable" 2 "DisengageEngage_Error" 1 "DisengageEngage_Engage" 0 "DisengageEngage_Disengage" ;
VAL_ 1050 BodyOrCabWorkingLightFdbk_stat_I 3 "OffOn_NotAvailable" 2 "OffOn_Error" 1 "OffOn_On" 0 "OffOn_Off" ;
VAL_ 1050 CabFrontSpotFeedback_Status 3 "OffOn_NotAvailable" 2 "OffOn_Error" 1 "OffOn_On" 0 "OffOn_Off" ;
VAL_ 1050 CabTiltEnableStatus 3 "DisableEnable_NotAvailable" 2 "DisableEnable_Error" 1 "DisableEnable_Enable" 0 "DisableEnable_Disable" ;
VAL_ 1050 TransmReverseDirectionSw_stat_IS 3 "OffOn_NotAvailable" 2 "OffOn_Error" 1 "OffOn_On" 0 "OffOn_Off" ;
VAL_ 1050 CabRoofSpotFeedback_Status 3 "OffOn_NotAvailable" 2 "OffOn_Error" 1 "OffOn_On" 0 "OffOn_Off" ;
VAL_ 1050 CabBeaconLightFeedback_Status_IS 3 "OffOn_NotAvailable" 2 "OffOn_Error" 1 "OffOn_On" 0 "OffOn_Off" ;
VAL_ 1050 ExtraAxleSteeringFunctionStat_IS 7 "RearAxleSteeringFunctionStatus_NotAvailable" 6 "RearAxleSteeringFunctionStatus_Error" 5 "RearAxleSteeringFunctionStatus_SpareValue_01" 4 "RearAxleSteeringFunctionStatus_SpareValue" 3 "RearAxleSteeringFunctionStatus_ActiveFailureMode" 2 "RearAxleSteeringFunctionStatus_PassiveFailureMode" 1 "RearAxleSteeringFunctionStatus_Active" 0 "RearAxleSteeringFunctionStatus_NotActive" ;
VAL_ 1050 CabTiltLockStatus_ISig_4 3 "UnlockedLocked_NotAvailable" 2 "UnlockedLocked_Error" 1 "UnlockedLocked_Locked" 0 "UnlockedLocked_Unlocked" ;
VAL_ 1050 PositionLightRearLamp_stat_ISig_ 7 "LampCheckLeftRight_stat_NotAvailable" 6 "LampCheckLeftRight_stat_Error" 5 "LampCheckLeftRight_stat_Spare" 4 "LampCheckLeftRight_stat_TestedLeftAndRightLampNOK" 3 "LampCheckLeftRight_stat_TestedRightLampNOK" 2 "LampCheckLeftRight_stat_TestedLeftLampNOK" 1 "LampCheckLeftRight_stat_TestedLampOK" 0 "LampCheckLeftRight_stat_NotTested" ;
VAL_ 931 Pto1BadCondition 15 "PtoBadCondition_NotAvailable" 14 "PtoBadCondition_Error" 13 "PtoBadCondition_Spare_02" 12 "PtoBadCondition_TransferBoxNotInNeutral" 11 "PtoBadCondition_CrossCountryAlreadyactive" 10 "PtoBadCondition_AirPressureTooLow" 9 "PtoBadCondition_WrongGearSplitSelected" 8 "PtoBadCondition_ClutchPedalNotPressed" 7 "PtoBadCondition_ServiceBrakeNotApplied" 6 "PtoBadCondition_ParkbrakeNotActive" 5 "PtoBadCondition_VehicleSpeedTooHigh" 4 "PtoBadCondition_EngineSpeedTooLow" 3 "PtoBadCondition_EngineSpeedTooHigh" 2 "PtoBadCondition_GearboxNotInNeutral" 1 "PtoBadCondition_BadConditionsForEngagementGeneric" 0 "PtoBadCondition_NoBadConditionForEngagement" ;
VAL_ 931 Pto4BadCondition 15 "PtoBadCondition_NotAvailable" 14 "PtoBadCondition_Error" 13 "PtoBadCondition_Spare_02" 12 "PtoBadCondition_TransferBoxNotInNeutral" 11 "PtoBadCondition_CrossCountryAlreadyactive" 10 "PtoBadCondition_AirPressureTooLow" 9 "PtoBadCondition_WrongGearSplitSelected" 8 "PtoBadCondition_ClutchPedalNotPressed" 7 "PtoBadCondition_ServiceBrakeNotApplied" 6 "PtoBadCondition_ParkbrakeNotActive" 5 "PtoBadCondition_VehicleSpeedTooHigh" 4 "PtoBadCondition_EngineSpeedTooLow" 3 "PtoBadCondition_EngineSpeedTooHigh" 2 "PtoBadCondition_GearboxNotInNeutral" 1 "PtoBadCondition_BadConditionsForEngagementGeneric" 0 "PtoBadCondition_NoBadConditionForEngagement" ;
VAL_ 931 Pto2BadCondition 15 "PtoBadCondition_NotAvailable" 14 "PtoBadCondition_Error" 13 "PtoBadCondition_Spare_02" 12 "PtoBadCondition_TransferBoxNotInNeutral" 11 "PtoBadCondition_CrossCountryAlreadyactive" 10 "PtoBadCondition_AirPressureTooLow" 9 "PtoBadCondition_WrongGearSplitSelected" 8 "PtoBadCondition_ClutchPedalNotPressed" 7 "PtoBadCondition_ServiceBrakeNotApplied" 6 "PtoBadCondition_ParkbrakeNotActive" 5 "PtoBadCondition_VehicleSpeedTooHigh" 4 "PtoBadCondition_EngineSpeedTooLow" 3 "PtoBadCondition_EngineSpeedTooHigh" 2 "PtoBadCondition_GearboxNotInNeutral" 1 "PtoBadCondition_BadConditionsForEngagementGeneric" 0 "PtoBadCondition_NoBadConditionForEngagement" ;
VAL_ 931 PtoRequest 3 "InactiveActive_NotAvailable" 2 "InactiveActive_Error" 1 "InactiveActive_Active" 0 "InactiveActive_Inactive" ;
VAL_ 931 Pto2ConsentRequest 3 "PtoConsentRequest_NotAvailable" 2 "PtoConsentRequest_Error" 1 "PtoConsentRequest_PTOOperationDesired" 0 "PtoConsentRequest_PTOOperationNotDesired" ;
VAL_ 931 PBStatusDisplay_cmd_ISig_4 3 "DisableEnable_NotAvailable" 2 "DisableEnable_Error" 1 "DisableEnable_Enable" 0 "DisableEnable_Disable" ;
VAL_ 931 Pto4DrivingRequest 3 "OffOn_NotAvailable" 2 "OffOn_Error" 1 "OffOn_On" 0 "OffOn_Off" ;
VAL_ 931 Pto3Indication 3 "Request_NotAvailable" 2 "Request_Error" 1 "Request_RequestActive" 0 "Request_NotRequested" ;
VAL_ 931 Pto2Status_ISig_4 3 "InactiveActive_NotAvailable" 2 "InactiveActive_Error" 1 "InactiveActive_Active" 0 "InactiveActive_Inactive" ;
VAL_ 931 Pto4Status_ISig_4 3 "InactiveActive_NotAvailable" 2 "InactiveActive_Error" 1 "InactiveActive_Active" 0 "InactiveActive_Inactive" ;
VAL_ 931 RampLevelRequestACK_ISig_4 3 "ChangeRequest2Bit_NotAvailable" 2 "ChangeRequest2Bit_Error" 1 "ChangeRequest2Bit_Change" 0 "ChangeRequest2Bit_TakeNoAction" ;
VAL_ 931 Pto3BadCondition 15 "PtoBadCondition_NotAvailable" 14 "PtoBadCondition_Error" 13 "PtoBadCondition_Spare_02" 12 "PtoBadCondition_TransferBoxNotInNeutral" 11 "PtoBadCondition_CrossCountryAlreadyactive" 10 "PtoBadCondition_AirPressureTooLow" 9 "PtoBadCondition_WrongGearSplitSelected" 8 "PtoBadCondition_ClutchPedalNotPressed" 7 "PtoBadCondition_ServiceBrakeNotApplied" 6 "PtoBadCondition_ParkbrakeNotActive" 5 "PtoBadCondition_VehicleSpeedTooHigh" 4 "PtoBadCondition_EngineSpeedTooLow" 3 "PtoBadCondition_EngineSpeedTooHigh" 2 "PtoBadCondition_GearboxNotInNeutral" 1 "PtoBadCondition_BadConditionsForEngagementGeneric" 0 "PtoBadCondition_NoBadConditionForEngagement" ;
VAL_ 931 PtosStatus_ISig_4 3 "PtosStatus_NotAvailable" 2 "PtosStatus_Error" 1 "PtosStatus_OneOrMorePTOEngaged" 0 "PtosStatus_NoPTOEngaged" ;
VAL_ 931 FrontWheelDriveAutoStatus_ISig_4 3 "OffAutomatic_NotAvailable" 2 "OffAutomatic_Error" 1 "OffAutomatic_Automatic" 0 "OffAutomatic_Off" ;
VAL_ 931 Pto1ConsentRequest 3 "PtoConsentRequest_NotAvailable" 2 "PtoConsentRequest_Error" 1 "PtoConsentRequest_PTOOperationDesired" 0 "PtoConsentRequest_PTOOperationNotDesired" ;
VAL_ 931 Pto4Indication 3 "Request_NotAvailable" 2 "Request_Error" 1 "Request_RequestActive" 0 "Request_NotRequested" ;
VAL_ 931 Pto1Indication 3 "Request_NotAvailable" 2 "Request_Error" 1 "Request_RequestActive" 0 "Request_NotRequested" ;
VAL_ 931 Pto3Status_ISig_4 3 "InactiveActive_NotAvailable" 2 "InactiveActive_Error" 1 "InactiveActive_Active" 0 "InactiveActive_Inactive" ;
VAL_ 931 Pto2Indication 3 "Request_NotAvailable" 2 "Request_Error" 1 "Request_RequestActive" 0 "Request_NotRequested" ;
VAL_ 931 Pto1FeedbackStatus_ISig_4 3 "OffOn_NotAvailable" 2 "OffOn_Error" 1 "OffOn_On" 0 "OffOn_Off" ;
VAL_ 931 TransferCaseOrSplitboxPTOMode_IS 3 "InactiveActive_NotAvailable" 2 "InactiveActive_Error" 1 "InactiveActive_Active" 0 "InactiveActive_Inactive" ;
VAL_ 931 DirIndRearLamp_Stat_ISig_4 7 "LampCheckLeftRight_stat_NotAvailable" 6 "LampCheckLeftRight_stat_Error" 5 "LampCheckLeftRight_stat_Spare" 4 "LampCheckLeftRight_stat_TestedLeftAndRightLampNOK" 3 "LampCheckLeftRight_stat_TestedRightLampNOK" 2 "LampCheckLeftRight_stat_TestedLeftLampNOK" 1 "LampCheckLeftRight_stat_TestedLampOK" 0 "LampCheckLeftRight_stat_NotTested" ;
VAL_ 931 Pto1Status_ISig_4 3 "InactiveActive_NotAvailable" 2 "InactiveActive_Error" 1 "InactiveActive_Active" 0 "InactiveActive_Inactive" ;
VAL_ 931 Pto3DrivingRequest 3 "OffOn_NotAvailable" 2 "OffOn_Error" 1 "OffOn_On" 0 "OffOn_Off" ;
VAL_ 725 StoreIdleValue 3 "StoreIdleValue_NotAvailable" 2 "StoreIdleValue_Error" 1 "StoreIdleValue_StoreSetValue" 0 "StoreIdleValue_DoNOTStoreValue" ;
VAL_ 725 HeightControlMode_ISig_4 15 "HeightControlMode_NotAvailable" 14 "HeightControlMode_ErrorIndicator" 13 "HeightControlMode_DumpFunction" 12 "HeightControlMode_FactorySupportMode" 11 "HeightControlMode_Calibration" 10 "HeightControlMode_Prohibit" 9 "HeightControlMode_FunctionTest" 8 "HeightControlMode_Stop" 7 "HeightControlMode_LimpHome" 6 "HeightControlMode_FerryFunction" 5 "HeightControlMode_KneelingHeight" 4 "HeightControlMode_DriveHeight" 3 "HeightControlMode_DockingRampHeight" 2 "HeightControlMode_HeightAdjustment" 1 "HeightControlMode_StartUpHeight" 0 "HeightControlMode_TakeNoAction" ;
VAL_ 725 ESCReqEMS_CtrlTrimMode_ISig_4 15 "CtrlTrimMode_NotAvailable" 14 "CtrlTrimMode_Error" 13 "CtrlTrimMode_Spare_08" 12 "CtrlTrimMode_Spare_07" 11 "CtrlTrimMode_Spare_06" 10 "CtrlTrimMode_Spare_05" 9 "CtrlTrimMode_Spare_04" 8 "CtrlTrimMode_Spare_03" 7 "CtrlTrimMode_Spare_02" 6 "CtrlTrimMode_Spare_01" 5 "CtrlTrimMode_Spare" 4 "CtrlTrimMode_MuddySiteEngineSpeedControl" 3 "CtrlTrimMode_AirManagementEngineSpeedControl" 2 "CtrlTrimMode_IdleAdjust" 1 "CtrlTrimMode_PTOEngineSpeedControl" 0 "CtrlTrimMode_NoRequest" ;
VAL_ 725 ESCReqESC_CtrlTrimMode_ISig_4 15 "CtrlTrimMode_NotAvailable" 14 "CtrlTrimMode_Error" 13 "CtrlTrimMode_Spare_08" 12 "CtrlTrimMode_Spare_07" 11 "CtrlTrimMode_Spare_06" 10 "CtrlTrimMode_Spare_05" 9 "CtrlTrimMode_Spare_04" 8 "CtrlTrimMode_Spare_03" 7 "CtrlTrimMode_Spare_02" 6 "CtrlTrimMode_Spare_01" 5 "CtrlTrimMode_Spare" 4 "CtrlTrimMode_MuddySiteEngineSpeedControl" 3 "CtrlTrimMode_AirManagementEngineSpeedControl" 2 "CtrlTrimMode_IdleAdjust" 1 "CtrlTrimMode_PTOEngineSpeedControl" 0 "CtrlTrimMode_NoRequest" ;
VAL_ 725 ESCReqEMS_CtrlTrimStat_ISig_4 7 "CtrlTrimStat_NotAvailable" 6 "CtrlTrimStat_Error" 5 "CtrlTrimStat_Spare_02" 4 "CtrlTrimStat_Spare_01" 3 "CtrlTrimStat_Spare" 2 "CtrlTrimStat_TrimActive" 1 "CtrlTrimStat_ControlActive" 0 "CtrlTrimStat_NoRequestActive" ;
VAL_ 725 TrailerConnected_ISig_4 3 "NoYes_NotAvailable" 2 "NoYes_Error" 1 "NoYes_Yes" 0 "NoYes_No" ;
VAL_ 725 ESCReqESC_CtrlTrimStat_ISig_4 7 "CtrlTrimStat_NotAvailable" 6 "CtrlTrimStat_Error" 5 "CtrlTrimStat_Spare_02" 4 "CtrlTrimStat_Spare_01" 3 "CtrlTrimStat_Spare" 2 "CtrlTrimStat_TrimActive" 1 "CtrlTrimStat_ControlActive" 0 "CtrlTrimStat_NoRequestActive" ;
VAL_ 725 SCLLogicEnable_rqst 7 "SCLLogicEnable_rqst_NotAvailable" 6 "SCLLogicEnable_rqst_Error" 5 "SCLLogicEnable_rqst_Spare_disable_value_02" 4 "SCLLogicEnable_rqst_Spare_disable_value_01" 3 "SCLLogicEnable_rqst_Enable_locking" 2 "SCLLogicEnable_rqst_Enable_unlocking" 1 "SCLLogicEnable_rqst_Retry_disable" 0 "SCLLogicEnable_rqst_Disable" ;
VAL_ 725 ESCReqESC_CtrlTrimReq_ISig_4 7 "CtrlTrimReq_NotAvailable" 6 "CtrlTrimReq_Error" 5 "CtrlTrimReq_Spare_02" 4 "CtrlTrimReq_Spare_01" 3 "CtrlTrimReq_Spare" 2 "CtrlTrimReq_TrimRampDown" 1 "CtrlTrimReq_TrimRampUp" 0 "CtrlTrimReq_NoRamp" ;
VAL_ 725 BrakeLight_rqst_ISig_4 7 "BrakeLight_rqst_NotAvailable" 6 "BrakeLight_rqst_SpareValue_03" 5 "BrakeLight_rqst_SpareValue_02" 4 "BrakeLight_rqst_SpareValue_01" 3 "BrakeLight_rqst_SpareValue" 2 "BrakeLight_rqst_EmergencyBrakeLightOn" 1 "BrakeLight_rqst_BrakeLightOn" 0 "BrakeLight_rqst_BrakeLightAndEmergencyBrakeLightOff" ;
VAL_ 725 ESCReqEMS_CtrlTrimReq_ISig_4 7 "CtrlTrimReq_NotAvailable" 6 "CtrlTrimReq_Error" 5 "CtrlTrimReq_Spare_02" 4 "CtrlTrimReq_Spare_01" 3 "CtrlTrimReq_Spare" 2 "CtrlTrimReq_TrimRampDown" 1 "CtrlTrimReq_TrimRampUp" 0 "CtrlTrimReq_NoRamp" ;
VAL_ 721 TrailerTest_stat 7 "TrailerTest_stat_NotAvailable" 6 "TrailerTest_stat_Error" 5 "TrailerTest_stat_InProgress_TrailerNotConnected" 4 "TrailerTest_stat_NotPossibleLowVoltgeOrLowPressure" 3 "TrailerTest_stat_TrailerTestIncentive" 2 "TrailerTest_stat_NotPossibleServiceBrakeApplied" 1 "TrailerTest_stat_InProgress" 0 "TrailerTest_stat_IdleNoTrailerTest" ;
VAL_ 721 Washing_HMI_rqst_ISig_4 3 "InactiveActive_NotAvailable" 2 "InactiveActive_Error" 1 "InactiveActive_Active" 0 "InactiveActive_Inactive" ;
VAL_ 721 AuxBrakesDwngrdModeInd_rqst 7 "AuxBrakesDwngrdModeInd_rqst_NotAvailable" 6 "AuxBrakesDwngrdModeInd_rqst_Error" 5 "AuxBrakesDwngrdModeInd_rqst_Spare_3" 4 "AuxBrakesDwngrdModeInd_rqst_Spare_2" 3 "AuxBrakesDwngrdModeInd_rqst_Spare_1" 2 "AuxBrakesDwngrdModeInd_rqst_AuxiliaryBrakesShutdown" 1 "AuxBrakesDwngrdModeInd_rqst_ABSDowngradedMode" 0 "AuxBrakesDwngrdModeInd_rqst_NoRequest" ;
VAL_ 721 DirInd_StalkStatus_1_ISig_4 7 "DirInd_StalkStatus_NotAvailable" 6 "DirInd_StalkStatus_Error" 5 "DirInd_StalkStatus_Spare" 4 "DirInd_StalkStatus_RightTemporaryTurningIndication" 3 "DirInd_StalkStatus_LeftTemporaryTurningIndication" 2 "DirInd_StalkStatus_RightTurningIndication" 1 "DirInd_StalkStatus_LeftTurningIndication" 0 "DirInd_StalkStatus_NeutralRestingPositon" ;
VAL_ 721 KeyAuthentication_rqst 7 "KeyAuthentication_rqst_NotAvailable" 6 "KeyAuthentication_rqst_Error" 5 "KeyAuthentication_rqst_Spare02" 4 "KeyAuthentication_rqst_Spare01" 3 "KeyAuthentication_rqst_Spare" 2 "KeyAuthentication_rqst_RequestAuthentication" 1 "KeyAuthentication_rqst_KeyIsInserted" 0 "KeyAuthentication_rqst_KeyNotPresent" ;
VAL_ 721 EngineSpeedControlStatus 7 "EngineSpeedControlStatus_NotAvailable" 6 "EngineSpeedControlStatus_Error" 5 "EngineSpeedControlStatus_Spare_01" 4 "EngineSpeedControlStatus_AutoPtoMin_AutoNeutral" 3 "EngineSpeedControlStatus_CrossCountryEngineSpeedControlActive" 2 "EngineSpeedControlStatus_ActiveExternalSource" 1 "EngineSpeedControlStatus_ActiveManual" 0 "EngineSpeedControlStatus_Inactive" ;
VAL_ 721 SecondThrottle 3 "InactiveActive_NotAvailable" 2 "InactiveActive_Error" 1 "InactiveActive_Active" 0 "InactiveActive_Inactive" ;
VAL_ 721 PredeliveryModeIndication_cmd_IS 3 "DeactivateActivate_NotAvailable" 2 "DeactivateActivate_Error" 1 "DeactivateActivate_Activate" 0 "DeactivateActivate_Deactivate" ;
VAL_ 721 LoadCutOffIndication_cmd_ISig_4 3 "LoadCutOffIndication_cmd_NotAvailable" 2 "LoadCutOffIndication_cmd_Error" 1 "LoadCutOffIndication_cmd_LoadCutOffIndication" 0 "LoadCutOffIndication_cmd_NoIndication" ;
VAL_ 721 ExitPreDeliveryModeHMI_rqst_ISig 3 "FalseTrue_NotAvaiable" 2 "FalseTrue_Error" 1 "FalseTrue_True" 0 "FalseTrue_False" ;
VAL_ 721 FdEquipmentStatus1_ISig_4 3 "InactiveActive_NotAvailable" 2 "InactiveActive_Error" 1 "InactiveActive_Active" 0 "InactiveActive_Inactive" ;
VAL_ 534 ParkBrakeAlert_ISig_4 3 "Alert_NotAvailable" 2 "Alert_Error" 1 "Alert_Alert" 0 "Alert_NoAlert" ;
VAL_ 534 IntLightMode_CoreRqst_IL_Mode 7 "IL_ModeReq_NotAvailable" 6 "IL_ModeReq_ErrorIndicator" 5 "IL_ModeReq_NonHMIModeMax" 4 "IL_ModeReq_NonHMIModeResting" 3 "IL_ModeReq_Max" 2 "IL_ModeReq_Resting" 1 "IL_ModeReq_NightDriving" 0 "IL_ModeReq_OFF" ;
VAL_ 534 SteeringColumnLockErrInd_rqst 7 "SteeringColumnLockErrInd_rqst_NotAvailable" 6 "SteeringColumnLockErrInd_rqst_Error" 5 "SteeringColumnLockErrInd_rqst_SpareValue01" 4 "SteeringColumnLockErrInd_rqst_SpareValue" 3 "SteeringColumnLockErrInd_rqst_OtherError" 2 "SteeringColumnLockErrInd_rqst_NotPossibleToUnlock" 1 "SteeringColumnLockErrInd_rqst_NotPossibleToLock" 0 "SteeringColumnLockErrInd_rqst_NoErrorIndication" ;
VAL_ 534 ParkingLight_Indication 3 "DeviceIndication_SpareValue" 2 "DeviceIndication_Blink" 1 "DeviceIndication_On" 0 "DeviceIndication_Off" ;
VAL_ 534 DaytimeRunningLight_Indication 3 "DeviceIndication_SpareValue" 2 "DeviceIndication_Blink" 1 "DeviceIndication_On" 0 "DeviceIndication_Off" ;
VAL_ 534 EPBBackupMode_ISig_4 15 "EPBBackupMode_NotAvailable" 14 "EPBBackupMode_Error" 13 "EPBBackupMode_Level13" 12 "EPBBackupMode_Level12" 11 "EPBBackupMode_Level11" 10 "EPBBackupMode_Level10" 9 "EPBBackupMode_Level9" 8 "EPBBackupMode_Level8" 7 "EPBBackupMode_Level7" 6 "EPBBackupMode_Level6" 5 "EPBBackupMode_Level5" 4 "EPBBackupMode_Level4" 3 "EPBBackupMode_Level3" 2 "EPBBackupMode_Level2" 1 "EPBBackupMode_Level1" 0 "EPBBackupMode_Level0_NoBackUp" ;
VAL_ 534 WiperModeStatus_ISig_4 7 "WiperModeStatus_NotAvailable" 6 "WiperModeStatus_ErrorIndicator" 5 "WiperModeStatus_Spare02" 4 "WiperModeStatus_Spare01" 3 "WiperModeStatus_Spare" 2 "WiperModeStatus_HighSpeedWiping" 1 "WiperModeStatus_LowSpeedWiping" 0 "WiperModeStatus_WiperOff" ;
VAL_ 534 FrontFog_Indication_ISig_4 3 "DeviceIndication_SpareValue" 2 "DeviceIndication_Blink" 1 "DeviceIndication_On" 0 "DeviceIndication_Off" ;
VAL_ 534 PBReleaseAcceptance_stat_ISig_4 7 "PBReleaseAcceptance_stat_NotAvailable" 6 "PBReleaseAcceptance_stat_Error" 5 "PBReleaseAcceptance_stat_Spare_03" 4 "PBReleaseAcceptance_stat_AccelPedalOrHCURequested" 3 "PBReleaseAcceptance_stat_ReleaseRequestAccepted" 2 "PBReleaseAcceptance_stat_BrakeOrAccelPedalRequested" 1 "PBReleaseAcceptance_stat_BrakePedalRequested" 0 "PBReleaseAcceptance_stat_NoRequestDetectedOrRequestAborted" ;
VAL_ 534 DrivingLightPlus_Indication 3 "DeviceIndication_SpareValue" 2 "DeviceIndication_Blink" 1 "DeviceIndication_On" 0 "DeviceIndication_Off" ;
VAL_ 534 IntLightMode_CoreRqst_EventFlag 1 "EventFlag_High" 0 "EventFlag_Low" ;
VAL_ 534 ParkingBrake_stat_ISig_4 3 "ParkingBrake_stat_NotAvailable" 2 "ParkingBrake_stat_Error" 1 "ParkingBrake_stat_ParkingBrakeActivated" 0 "ParkingBrake_stat_ParkingBrakeReleased" ;
VAL_ 534 DrivingLight_Indication 3 "DeviceIndication_SpareValue" 2 "DeviceIndication_Blink" 1 "DeviceIndication_On" 0 "DeviceIndication_Off" ;
VAL_ 534 MirrorHeatingMode_ISig_4 7 "MirrorHeat_NotAvailable" 6 "MirrorHeat_ErrorIndicator" 5 "MirrorHeat_SpareValue_02" 4 "MirrorHeat_SpareValue_01" 3 "MirrorHeat_SpareValue" 2 "MirrorHeat_ONExtendedMode" 1 "MirrorHeat_ONNormalMode" 0 "MirrorHeat_OFF" ;
VAL_ 534 RearFog_Indication 3 "DeviceIndication_SpareValue" 2 "DeviceIndication_Blink" 1 "DeviceIndication_On" 0 "DeviceIndication_Off" ;
VAL_ 532 LiftAxle2LiftFuncSelected_ISig_4 7 "LiftAxleLiftAutoFuncSelected_NotAvailable" 6 "LiftAxleLiftAutoFuncSelected_Error" 5 "LiftAxleLiftAutoFuncSelected_Reserved" 4 "LiftAxleLiftAutoFuncSelected_UnlimitedLift" 3 "LiftAxleLiftAutoFuncSelected_LiftOverload" 2 "LiftAxleLiftAutoFuncSelected_LiftPlus30" 1 "LiftAxleLiftAutoFuncSelected_Lift" 0 "LiftAxleLiftAutoFuncSelected_NoLift" ;
VAL_ 532 StopLevelChangeAck_ISig_4 3 "StopLevelChangeStatus_NotAvailable" 2 "StopLevelChangeStatus_ErrorIndicator" 1 "StopLevelChangeStatus_LevelChangedStopped" 0 "StopLevelChangeStatus_NoStopRequest" ;
VAL_ 532 HeightAdjustmentAllowed_ISig_4 3 "FalseTrue_NotAvaiable" 2 "FalseTrue_Error" 1 "FalseTrue_True" 0 "FalseTrue_False" ;
VAL_ 532 LiftAxle2LowerACK_ISig_4 7 "LiftAxle2LowerACK_NotAvailable" 6 "LiftAxle2LowerACK_Error" 5 "LiftAxle2LowerACK_SystemDeniedVersatile" 4 "LiftAxle2LowerACK_Spare_01" 3 "LiftAxle2LowerACK_Spare" 2 "LiftAxle2LowerACK_LowerDeniedRAS_EC" 1 "LiftAxle2LowerACK_ChangeAcknowledged" 0 "LiftAxle2LowerACK_NoAction" ;
VAL_ 532 LiftAxle2UpRequestACK_ISig_4 7 "LiftAxleUpRequestACK_NotAvailable" 6 "LiftAxleUpRequestACK_Error" 5 "LiftAxleUpRequestACK_SystemDeniedVersatile" 4 "LiftAxleUpRequestACK_LiftDeniedPBrakeActive" 3 "LiftAxleUpRequestACK_LiftDeniedRearOverload" 2 "LiftAxleUpRequestACK_LiftDeniedFrontOverload" 1 "LiftAxleUpRequestACK_ChangeAcknowledged" 0 "LiftAxleUpRequestACK_NoAction" ;
VAL_ 532 RideHeightStatus_ISig_4 15 "RideHeightStatus_NotAvailable" 14 "RideHeightStatus_ErrorIndicator" 13 "RideHeightStatus_NotDefined_03" 12 "RideHeightStatus_NotDefined_02" 11 "RideHeightStatus_NotDefined_01" 10 "RideHeightStatus_NotDefined" 9 "RideHeightStatus_AlternativeDrivePosition2" 8 "RideHeightStatus_AlternativeDrivePosition1" 7 "RideHeightStatus_AlternativeDrivePosition" 6 "RideHeightStatus_HighDrivePosition" 5 "RideHeightStatus_LowDrivePosition" 4 "RideHeightStatus_SpeedDependentDrivePositionHighSpeed" 3 "RideHeightStatus_SpeedDependentDrivePositionLowSpeed" 2 "RideHeightStatus_StandardUserDrivePosition" 1 "RideHeightStatus_StandardFactoryDrivePosition" 0 "RideHeightStatus_Inactive" ;
VAL_ 532 RideHeightOutsideTargetRange_ISi 7 "HeightOutsideTargetRange_NotAvailable" 6 "HeightOutsideTargetRange_Error" 5 "HeightOutsideTargetRange_NotDefined_02" 4 "HeightOutsideTargetRange_NotDefined_01" 3 "HeightOutsideTargetRange_NotDefined" 2 "HeightOutsideTargetRange_ToHigh" 1 "HeightOutsideTargetRange_ToLow" 0 "HeightOutsideTargetRange_Inactive" ;
VAL_ 532 LoadDistributionFuncSelected_ISi 15 "LoadDistributionFuncSelected_NotAvaiable" 14 "LoadDistributionFuncSelected_ErrorIndicator" 13 "LoadDistributionFuncSelected_SpareValue_08" 12 "LoadDistributionFuncSelected_SpareValue_07" 11 "LoadDistributionFuncSelected_SpareValue_06" 10 "LoadDistributionFuncSelected_SpareValue_05" 9 "LoadDistributionFuncSelected_SpareValue_04" 8 "LoadDistributionFuncSelected_SpareValue_03" 7 "LoadDistributionFuncSelected_SpareValue_02" 6 "LoadDistributionFuncSelected_MaximumTractionStartingHelp" 5 "LoadDistributionFuncSelected_VariableAxleLoad" 4 "LoadDistributionFuncSelected_NoLoadDistribution" 3 "LoadDistributionFuncSelected_AlternativeLoad" 2 "LoadDistributionFuncSelected_MaximumTractionTractionHelp" 1 "LoadDistributionFuncSelected_OptimisedTraction" 0 "LoadDistributionFuncSelected_NormalLoad" ;
VAL_ 532 RideHeightStorageAck_ISig_4 3 "StorageAck_NotAvaiable" 2 "StorageAck_Error" 1 "StorageAck_ChangeAcknowledged" 0 "StorageAck_TakeNoAction" ;
VAL_ 532 LiftAxle2AutoLiftSelected_ISig_4 3 "FalseTrue_NotAvaiable" 2 "FalseTrue_Error" 1 "FalseTrue_True" 0 "FalseTrue_False" ;
VAL_ 532 LiftAxle1UpRequestACK_ISig_4 7 "LiftAxleUpRequestACK_NotAvailable" 6 "LiftAxleUpRequestACK_Error" 5 "LiftAxleUpRequestACK_SystemDeniedVersatile" 4 "LiftAxleUpRequestACK_LiftDeniedPBrakeActive" 3 "LiftAxleUpRequestACK_LiftDeniedRearOverload" 2 "LiftAxleUpRequestACK_LiftDeniedFrontOverload" 1 "LiftAxleUpRequestACK_ChangeAcknowledged" 0 "LiftAxleUpRequestACK_NoAction" ;
VAL_ 532 LiftAxle1PositionStatus_ISig_4 7 "LiftAxlePositionStatus_NotAvailable" 6 "LiftAxlePositionStatus_Error" 5 "LiftAxlePositionStatus_Reserved_01" 4 "LiftAxlePositionStatus_Reserved" 3 "LiftAxlePositionStatus_Lifting" 2 "LiftAxlePositionStatus_Lowering" 1 "LiftAxlePositionStatus_Lifted" 0 "LiftAxlePositionStatus_Lowered" ;
VAL_ 532 LiftAxle1LowerACK_ISig_4 7 "LiftAxle1LowerACK_NotAvailable" 6 "LiftAxle1LowerACK_Error" 5 "LiftAxle1LowerACK_SystemDeniedVersatile" 4 "LiftAxle1LowerACK_Spare_01" 3 "LiftAxle1LowerACK_Spare" 2 "LiftAxle1LowerACK_LowerDeniedRAS_EC" 1 "LiftAxle1LowerACK_ChangeAcknowledged" 0 "LiftAxle1LowerACK_NoAction" ;
VAL_ 532 LiftAxle1AutoLiftSelected_ISig_4 3 "FalseTrue_NotAvaiable" 2 "FalseTrue_Error" 1 "FalseTrue_True" 0 "FalseTrue_False" ;
VAL_ 532 LiftAxle2PositionStatus_ISig_4 7 "LiftAxlePositionStatus_NotAvailable" 6 "LiftAxlePositionStatus_Error" 5 "LiftAxlePositionStatus_Reserved_01" 4 "LiftAxlePositionStatus_Reserved" 3 "LiftAxlePositionStatus_Lifting" 2 "LiftAxlePositionStatus_Lowering" 1 "LiftAxlePositionStatus_Lifted" 0 "LiftAxlePositionStatus_Lowered" ;
VAL_ 532 LevelControlInformation_ISig_4 15 "LevelControlInformation_NotAvailable" 14 "LevelControlInformation_Error" 13 "LevelControlInformation_Reserved_06" 12 "LevelControlInformation_Reserved_05" 11 "LevelControlInformation_Reserved_04" 10 "LevelControlInformation_Reserved_03" 9 "LevelControlInformation_Reserved_02" 8 "LevelControlInformation_Reserved_01" 7 "LevelControlInformation_Reserved" 6 "LevelControlInformation_LimpHome" 5 "LevelControlInformation_FerryFunction" 4 "LevelControlInformation_KneelingHeight" 3 "LevelControlInformation_DriveHeight" 2 "LevelControlInformation_DockingHeight" 1 "LevelControlInformation_HeightAdjustment" 0 "LevelControlInformation_Prohibit" ;
VAL_ 532 LiftAxle1LiftFuncSelected_ISig_4 7 "LiftAxleLiftAutoFuncSelected_NotAvailable" 6 "LiftAxleLiftAutoFuncSelected_Error" 5 "LiftAxleLiftAutoFuncSelected_Reserved" 4 "LiftAxleLiftAutoFuncSelected_UnlimitedLift" 3 "LiftAxleLiftAutoFuncSelected_LiftOverload" 2 "LiftAxleLiftAutoFuncSelected_LiftPlus30" 1 "LiftAxleLiftAutoFuncSelected_Lift" 0 "LiftAxleLiftAutoFuncSelected_NoLift" ;
VAL_ 532 LoadDistributionChangeACK_ISig_4 7 "LoadDistributionChangeACK_NotAvailable" 6 "LoadDistributionChangeACK_Error" 5 "LoadDistributionChangeACK_SystemDeniedVersatile" 4 "LoadDistributionChangeACK_Reserved_2" 3 "LoadDistributionChangeACK_DeniedDueToDisengagedDifflock" 2 "LoadDistributionChangeACK_LoadShiftDeniedFALIMOverload" 1 "LoadDistributionChangeACK_ChangeAcknowledged" 0 "LoadDistributionChangeACK_NoAction" ;
VAL_ 532 RampLevelStorageAck_ISig_4 3 "StorageAck_NotAvaiable" 2 "StorageAck_Error" 1 "StorageAck_ChangeAcknowledged" 0 "StorageAck_TakeNoAction" ;
VAL_ 532 LoadDistributionSelected_ISig_4 15 "LoadDistributionSelected_NotAvailable" 14 "LoadDistributionSelected_Error" 13 "LoadDistributionSelected_Reserved_05" 12 "LoadDistributionSelected_Reserved_04" 11 "LoadDistributionSelected_Reserved_03" 10 "LoadDistributionSelected_TractionHelp2" 9 "LoadDistributionSelected_StartingHelp2" 8 "LoadDistributionSelected_VariableAxleLoad" 7 "LoadDistributionSelected_NoLoadDistribution" 6 "LoadDistributionSelected_TractionHelpInterDiff" 5 "LoadDistributionSelected_StartingHelpInterDiff" 4 "LoadDistributionSelected_AlternativeLoad" 3 "LoadDistributionSelected_TractionHelp" 2 "LoadDistributionSelected_StartingHelp" 1 "LoadDistributionSelected_OptimisedTraction" 0 "LoadDistributionSelected_NormalLoad" ;
VAL_ 532 RideHeightFunctionStatus_ISig_4 15 "RideHeightFunction_NotAvailable" 14 "RideHeightFunction_ErrorIndicator" 13 "RideHeightFunction_NotDefined_05" 12 "RideHeightFunction_NotDefined_04" 11 "RideHeightFunction_NotDefined_03" 10 "RideHeightFunction_NotDefined_02" 9 "RideHeightFunction_NotDefined_01" 8 "RideHeightFunction_NotDefined" 7 "RideHeightFunction_AlternativeDrivePosition2" 6 "RideHeightFunction_AlternativeDrivePosition1" 5 "RideHeightFunction_LowDrivePosition" 4 "RideHeightFunction_HighDrivePosition" 3 "RideHeightFunction_SpeedDependentDrivePosition" 2 "RideHeightFunction_AlternativeDrivePosition" 1 "RideHeightFunction_StandardDrivePosition" 0 "RideHeightFunction_Inactive" ;
VAL_ 520 TransmLowRangeSenseSwitch_ISig_4 3 "OffOn_NotAvailable" 2 "OffOn_Error" 1 "OffOn_On" 0 "OffOn_Off" ;
VAL_ 520 TransmSystemPowerDown_rqst 3 "TransmSystemPowerDown_rqst_DontCare" 2 "TransmSystemPowerDown_rqst_NotDefined" 1 "TransmSystemPowerDown_rqst_PowerDownRequestActive" 0 "TransmSystemPowerDown_rqst_PowerDownRequestInactive" ;
VAL_ 520 TransmissionNeutralSwitch_ISig_4 3 "TransmissionNeutralSwitch_NotAvailable" 2 "TransmissionNeutralSwitch_Error" 1 "TransmissionNeutralSwitch_TransmissionInNeutral" 0 "TransmissionNeutralSwitch_TransmissionNotInNeutral" ;
VAL_ 520 SecuredNeutralPosition_ISig_4 3 "SecuredNeutralPosition_NotAvailable" 2 "SecuredNeutralPosition_Error" 1 "SecuredNeutralPosition_SecuredNeutralPosition" 0 "SecuredNeutralPosition_NotInSecuredNeutralPosition" ;
VAL_ 520 EngineStopRequest_ISig_4 3 "Request_NotAvailable" 2 "Request_Error" 1 "Request_RequestActive" 0 "Request_NotRequested" ;
VAL_ 520 ReverseGearEngaged_ISig_4 3 "ReverseGearEngaged_NotAvailable" 2 "ReverseGearEngaged_Error" 1 "ReverseGearEngaged_ReverseGearEngaged" 0 "ReverseGearEngaged_ReverseGearNotEngaged" ;
VAL_ 520 EngineCrankRequest 3 "Request_NotAvailable" 2 "Request_Error" 1 "Request_RequestActive" 0 "Request_NotRequested" ;
VAL_ 520 ParkBrakeActuationStatus_ISig_4 7 "ParkBrakeActuationStatus_NotAvailable" 6 "ParkBrakeActuationStatus_Error" 5 "ParkBrakeActuationStatus_SpareValue_01" 4 "ParkBrakeActuationStatus_SpareValue" 3 "ParkBrakeActuationStatus_AntiCompound" 2 "ParkBrakeActuationStatus_Parked" 1 "ParkBrakeActuationStatus_PartiallyParked" 0 "ParkBrakeActuationStatus_Released" ;
VAL_ 520 EnginePreheat_rqst 3 "Request_NotAvailable" 2 "Request_Error" 1 "Request_RequestActive" 0 "Request_NotRequested" ;
VAL_ 520 KeyPosition_ISig_4 7 "KeyPosition_NotAvailable" 6 "KeyPosition_ErrorIndicator" 5 "KeyPosition_IgnitionKeyInCrankPosition" 4 "KeyPosition_IgnitionKeyInPreheatPosition" 3 "KeyPosition_IgnitionKeyIn15PositionNormalDrivingPosition" 2 "KeyPosition_IgnitionKeyInAccessoryPosition" 1 "KeyPosition_IgnitionKeyInOffPosition" 0 "KeyPosition_KeyOut" ;
VAL_ 520 GearSplit_Status_ISig_4 3 "GearSplit_Status_NotAvailable" 2 "GearSplit_Status_Error" 1 "GearSplit_Status_HighSplit" 0 "GearSplit_Status_LowSplit" ;
VAL_ 520 FerryFunctionSwitchChangeACK_ISi 3 "Ack2Bit_NotAvailable" 2 "Ack2Bit_Error" 1 "Ack2Bit_ChangeAcknowledged" 0 "Ack2Bit_NoAction" ;
VAL_ 520 DirectionIndication_cmd 15 "DirectionIndication_cmd_NotAvailable" 14 "DirectionIndication_cmd_Error" 13 "DirectionIndication_cmd_ActBothTruckTrailerTelltalesFaultInd" 12 "DirectionIndication_cmd_ActBothTruckTelltalesFaultInd" 11 "DirectionIndication_cmd_ActRghtTruckRghtTrailTelltaleFaultInd" 10 "DirectionIndication_cmd_ActLeftTruckLeftTrailTelltaleFaultInd" 9 "DirectionIndication_cmd_ActRghtTruckTelltaleFaultInd" 8 "DirectionIndication_cmd_ActLeftTruckTelltaleFaultInd" 7 "DirectionIndication_cmd_ActivateBothTruckAndTrailer_Hazard" 6 "DirectionIndication_cmd_ActivateBothTruck_Hazard" 5 "DirectionIndication_cmd_ActivateRightTruckAndTrailer" 4 "DirectionIndication_cmd_ActivateLeftTruckAndTrailer" 3 "DirectionIndication_cmd_ActivateRightTruck" 2 "DirectionIndication_cmd_ActivateLeftTruck" 1 "DirectionIndication_cmd_ActivateLow" 0 "DirectionIndication_cmd_Deactivate" ;
VAL_ 520 IdleShutdownWarning 3 "InactiveActive_NotAvailable" 2 "InactiveActive_Error" 1 "InactiveActive_Active" 0 "InactiveActive_Inactive" ;
VAL_ 520 BackToDriveReqACK_ISig_4 3 "BackToDriveReqACK_NotAvailable" 2 "BackToDriveReqACK_Error" 1 "BackToDriveReqACK_ChangeAcknowledged" 0 "BackToDriveReqACK_TakNoAction" ;
VAL_ 520 EngineSystemPowerDownRequest_ISi 3 "Request_NotAvailable" 2 "Request_Error" 1 "Request_RequestActive" 0 "Request_NotRequested" ;
VAL_ 1283 TrafficSitPathExecSta_Type 255 "TrafficSitEventType_NotAvailable" 254 "TrafficSitEventType_Error" 253 "TrafficSitEventType_NotUsed3" 252 "TrafficSitEventType_NotUsed2" 251 "TrafficSitEventType_NotUsed1" 250 "TrafficSitEventType_GeneralEvent" 249 "TrafficSitEventType_spare242" 248 "TrafficSitEventType_spare241" 247 "TrafficSitEventType_spare240" 246 "TrafficSitEventType_spare239" 245 "TrafficSitEventType_spare238" 244 "TrafficSitEventType_spare237" 243 "TrafficSitEventType_spare236" 242 "TrafficSitEventType_spare235" 241 "TrafficSitEventType_spare234" 240 "TrafficSitEventType_spare233" 239 "TrafficSitEventType_spare232" 238 "TrafficSitEventType_spare231" 237 "TrafficSitEventType_spare230" 236 "TrafficSitEventType_spare229" 235 "TrafficSitEventType_spare228" 234 "TrafficSitEventType_spare227" 233 "TrafficSitEventType_spare226" 232 "TrafficSitEventType_spare225" 231 "TrafficSitEventType_spare224" 230 "TrafficSitEventType_spare223" 229 "TrafficSitEventType_spare222" 228 "TrafficSitEventType_spare221" 227 "TrafficSitEventType_spare220" 226 "TrafficSitEventType_spare219" 225 "TrafficSitEventType_spare218" 224 "TrafficSitEventType_spare217" 223 "TrafficSitEventType_spare216" 222 "TrafficSitEventType_spare215" 221 "TrafficSitEventType_spare214" 220 "TrafficSitEventType_spare213" 219 "TrafficSitEventType_spare212" 218 "TrafficSitEventType_spare211" 217 "TrafficSitEventType_spare210" 216 "TrafficSitEventType_spare209" 215 "TrafficSitEventType_spare208" 214 "TrafficSitEventType_spare207" 213 "TrafficSitEventType_spare206" 212 "TrafficSitEventType_spare205" 211 "TrafficSitEventType_spare204" 210 "TrafficSitEventType_spare203" 209 "TrafficSitEventType_spare202" 208 "TrafficSitEventType_spare201" 207 "TrafficSitEventType_spare200" 206 "TrafficSitEventType_spare199" 205 "TrafficSitEventType_spare198" 204 "TrafficSitEventType_spare197" 203 "TrafficSitEventType_spare196" 202 "TrafficSitEventType_spare195" 201 "TrafficSitEventType_spare194" 200 "TrafficSitEventType_spare193" 199 "TrafficSitEventType_spare192" 198 "TrafficSitEventType_spare191" 197 "TrafficSitEventType_spare190" 196 "TrafficSitEventType_spare189" 195 "TrafficSitEventType_spare188" 194 "TrafficSitEventType_spare187" 193 "TrafficSitEventType_spare186" 192 "TrafficSitEventType_spare185" 191 "TrafficSitEventType_spare184" 190 "TrafficSitEventType_spare183" 189 "TrafficSitEventType_spare182" 188 "TrafficSitEventType_spare181" 187 "TrafficSitEventType_spare180" 186 "TrafficSitEventType_spare179" 185 "TrafficSitEventType_spare178" 184 "TrafficSitEventType_spare177" 183 "TrafficSitEventType_spare176" 182 "TrafficSitEventType_spare175" 181 "TrafficSitEventType_spare174" 180 "TrafficSitEventType_spare173" 179 "TrafficSitEventType_spare172" 178 "TrafficSitEventType_spare171" 177 "TrafficSitEventType_spare170" 176 "TrafficSitEventType_spare169" 175 "TrafficSitEventType_spare168" 174 "TrafficSitEventType_spare167" 173 "TrafficSitEventType_spare166" 172 "TrafficSitEventType_spare165" 171 "TrafficSitEventType_spare164" 170 "TrafficSitEventType_spare163" 169 "TrafficSitEventType_spare162" 168 "TrafficSitEventType_spare161" 167 "TrafficSitEventType_spare160" 166 "TrafficSitEventType_spare159" 165 "TrafficSitEventType_spare158" 164 "TrafficSitEventType_spare157" 163 "TrafficSitEventType_spare156" 162 "TrafficSitEventType_spare155" 161 "TrafficSitEventType_spare154" 160 "TrafficSitEventType_spare153" 159 "TrafficSitEventType_spare152" 158 "TrafficSitEventType_spare151" 157 "TrafficSitEventType_spare150" 156 "TrafficSitEventType_spare149" 155 "TrafficSitEventType_spare148" 154 "TrafficSitEventType_spare147" 153 "TrafficSitEventType_spare146" 152 "TrafficSitEventType_spare145" 151 "TrafficSitEventType_spare144" 150 "TrafficSitEventType_spare143" 149 "TrafficSitEventType_spare142" 148 "TrafficSitEventType_spare141" 147 "TrafficSitEventType_spare140" 146 "TrafficSitEventType_spare139" 145 "TrafficSitEventType_spare138" 144 "TrafficSitEventType_spare137" 143 "TrafficSitEventType_spare136" 142 "TrafficSitEventType_spare135" 141 "TrafficSitEventType_spare134" 140 "TrafficSitEventType_spare133" 139 "TrafficSitEventType_spare132" 138 "TrafficSitEventType_spare131" 137 "TrafficSitEventType_spare130" 136 "TrafficSitEventType_spare129" 135 "TrafficSitEventType_spare128" 134 "TrafficSitEventType_spare127" 133 "TrafficSitEventType_spare126" 132 "TrafficSitEventType_spare125" 131 "TrafficSitEventType_spare124" 130 "TrafficSitEventType_spare123" 129 "TrafficSitEventType_spare122" 128 "TrafficSitEventType_spare121" 127 "TrafficSitEventType_spare120" 126 "TrafficSitEventType_spare119" 125 "TrafficSitEventType_spare118" 124 "TrafficSitEventType_spare117" 123 "TrafficSitEventType_spare116" 122 "TrafficSitEventType_spare115" 121 "TrafficSitEventType_spare114" 120 "TrafficSitEventType_spare113" 119 "TrafficSitEventType_spare112" 118 "TrafficSitEventType_spare111" 117 "TrafficSitEventType_spare110" 116 "TrafficSitEventType_spare109" 115 "TrafficSitEventType_spare108" 114 "TrafficSitEventType_spare107" 113 "TrafficSitEventType_spare106" 112 "TrafficSitEventType_spare105" 111 "TrafficSitEventType_spare104" 110 "TrafficSitEventType_spare103" 109 "TrafficSitEventType_spare102" 108 "TrafficSitEventType_spare101" 107 "TrafficSitEventType_spare100" 106 "TrafficSitEventType_spare99" 105 "TrafficSitEventType_spare98" 104 "TrafficSitEventType_spare97" 103 "TrafficSitEventType_spare96" 102 "TrafficSitEventType_spare95" 101 "TrafficSitEventType_spare94" 100 "TrafficSitEventType_spare93" 99 "TrafficSitEventType_spare92" 98 "TrafficSitEventType_spare91" 97 "TrafficSitEventType_spare90" 96 "TrafficSitEventType_spare89" 95 "TrafficSitEventType_spare88" 94 "TrafficSitEventType_spare87" 93 "TrafficSitEventType_spare86" 92 "TrafficSitEventType_spare85" 91 "TrafficSitEventType_spare84" 90 "TrafficSitEventType_spare83" 89 "TrafficSitEventType_spare82" 88 "TrafficSitEventType_spare81" 87 "TrafficSitEventType_spare80" 86 "TrafficSitEventType_spare79" 85 "TrafficSitEventType_spare78" 84 "TrafficSitEventType_spare77" 83 "TrafficSitEventType_spare76" 82 "TrafficSitEventType_spare75" 81 "TrafficSitEventType_spare74" 80 "TrafficSitEventType_spare73" 79 "TrafficSitEventType_spare72" 78 "TrafficSitEventType_spare71" 77 "TrafficSitEventType_spare70" 76 "TrafficSitEventType_spare69" 75 "TrafficSitEventType_spare68" 74 "TrafficSitEventType_spare67" 73 "TrafficSitEventType_spare66" 72 "TrafficSitEventType_spare65" 71 "TrafficSitEventType_spare64" 70 "TrafficSitEventType_spare63" 69 "TrafficSitEventType_spare62" 68 "TrafficSitEventType_spare61" 67 "TrafficSitEventType_spare60" 66 "TrafficSitEventType_spare59" 65 "TrafficSitEventType_spare58" 64 "TrafficSitEventType_spare57" 63 "TrafficSitEventType_spare56" 62 "TrafficSitEventType_spare55" 61 "TrafficSitEventType_spare54" 60 "TrafficSitEventType_spare53" 59 "TrafficSitEventType_spare52" 58 "TrafficSitEventType_spare51" 57 "TrafficSitEventType_spare50" 56 "TrafficSitEventType_spare49" 55 "TrafficSitEventType_spare48" 54 "TrafficSitEventType_spare47" 53 "TrafficSitEventType_spare46" 52 "TrafficSitEventType_spare45" 51 "TrafficSitEventType_spare44" 50 "TrafficSitEventType_spare43" 49 "TrafficSitEventType_spare42" 48 "TrafficSitEventType_spare41" 47 "TrafficSitEventType_spare40" 46 "TrafficSitEventType_spare39" 45 "TrafficSitEventType_spare38" 44 "TrafficSitEventType_spare37" 43 "TrafficSitEventType_spare36" 42 "TrafficSitEventType_spare35" 41 "TrafficSitEventType_spare34" 40 "TrafficSitEventType_spare33" 39 "TrafficSitEventType_spare32" 38 "TrafficSitEventType_spare31" 37 "TrafficSitEventType_spare30" 36 "TrafficSitEventType_spare29" 35 "TrafficSitEventType_spare28" 34 "TrafficSitEventType_spare27" 33 "TrafficSitEventType_spare26" 32 "TrafficSitEventType_spare25" 31 "TrafficSitEventType_spare24" 30 "TrafficSitEventType_spare23" 29 "TrafficSitEventType_spare22" 28 "TrafficSitEventType_spare21" 27 "TrafficSitEventType_spare20" 26 "TrafficSitEventType_spare19" 25 "TrafficSitEventType_spare18" 24 "TrafficSitEventType_spare17" 23 "TrafficSitEventType_spare16" 22 "TrafficSitEventType_spare15" 21 "TrafficSitEventType_spare14" 20 "TrafficSitEventType_spare13" 19 "TrafficSitEventType_spare12" 18 "TrafficSitEventType_spare11" 17 "TrafficSitEventType_spare10" 16 "TrafficSitEventType_spare9" 15 "TrafficSitEventType_spare8" 14 "TrafficSitEventType_spare7" 13 "TrafficSitEventType_spare6" 12 "TrafficSitEventType_spare5" 11 "TrafficSitEventType_spare4" 10 "TrafficSitEventType_spare3" 9 "TrafficSitEventType_spare2" 8 "TrafficSitEventType_spare1" 7 "TrafficSitEventType_NarrowRoad" 6 "TrafficSitEventType_TrafficJam_OR_SlowTraffic" 5 "TrafficSitEventType_Crossing" 4 "TrafficSitEventType_Roundabout" 3 "TrafficSitEventType_CurveRight" 2 "TrafficSitEventType_CurveLeft" 1 "TrafficSitEventType_SpeedLimit" 0 "TrafficSitEventType_NoEvent" ;
VAL_ 1249 OilLevelDrvInstr_IncorrEngSpe 3 "DisplayText_NotAvailable" 2 "DisplayText_Error" 1 "DisplayText_DisplayText" 0 "DisplayText_DoNotDisplayText" ;
VAL_ 1249 OilLevelDrvInstr_StopVehicle 3 "DisplayText_NotAvailable" 2 "DisplayText_Error" 1 "DisplayText_DisplayText" 0 "DisplayText_DoNotDisplayText" ;
VAL_ 1249 SchwungStatus 3 "InactiveActive_NotAvailable" 2 "InactiveActive_Error" 1 "InactiveActive_Active" 0 "InactiveActive_Inactive" ;
VAL_ 1249 HillDataCtrlTECU_State_ISig_4 7 "HillDataState_NotAvailable" 6 "HillDataState_Error" 5 "HillDataState_Spare_03" 4 "HillDataState_Spare_02" 3 "HillDataState_Spare_01" 2 "HillDataState_Receive" 1 "HillDataState_Request" 0 "HillDataState_Idle" ;
VAL_ 1249 OilLevelDrvInstr_Wait60SecTxt 3 "DisplayText_NotAvailable" 2 "DisplayText_Error" 1 "DisplayText_DisplayText" 0 "DisplayText_DoNotDisplayText" ;
VAL_ 1249 ClutchAbuseStatus 3 "ClutchAbuseStatus_NotAvailable" 2 "ClutchAbuseStatus_Error" 1 "ClutchAbuseStatus_ClutchAbused" 0 "ClutchAbuseStatus_ClutchNotAbused" ;
VAL_ 1249 TransmissionSplitboxPTOMode 7 "TransmissionSplitboxPTOMode_NotAvailable" 6 "TransmissionSplitboxPTOMode_Error" 5 "TransmissionSplitboxPTOMode_Spare3" 4 "TransmissionSplitboxPTOMode_Spare2" 3 "TransmissionSplitboxPTOMode_Spare1" 2 "TransmissionSplitboxPTOMode_Running" 1 "TransmissionSplitboxPTOMode_Standby" 0 "TransmissionSplitboxPTOMode_Inactive" ;
VAL_ 1249 CACCSuitability 3 "Suitable_NotAvailable" 2 "Suitable_Error" 1 "Suitable_Suitable" 0 "Suitable_NotSuitable" ;
VAL_ 1249 ClutchCalibration_stat 3 "InactiveActive_NotAvailable" 2 "InactiveActive_Error" 1 "InactiveActive_Active" 0 "InactiveActive_Inactive" ;
VAL_ 1249 OilLevelDrvInstr_ChangeGearTxt 3 "DisplayText_NotAvailable" 2 "DisplayText_Error" 1 "DisplayText_DisplayText" 0 "DisplayText_DoNotDisplayText" ;
VAL_ 1249 OilLevelDrvInstr_NotHorizonTxt 3 "DisplayText_NotAvailable" 2 "DisplayText_Error" 1 "DisplayText_DisplayText" 0 "DisplayText_DoNotDisplayText" ;
VAL_ 1249 ISeeStatus 7 "ISeeStatus_NotAvailable" 6 "ISeeStatus_Error" 5 "ISeeStatus_Spare2" 4 "ISeeStatus_Spare1" 3 "ISeeStatus_EnabledAndActive" 2 "ISeeStatus_EnabledButInactive" 1 "ISeeStatus_Disabled" 0 "ISeeStatus_Off" ;
VAL_ 1249 EcoRollEnabledStatus 3 "DisableEnable_NotAvailable" 2 "DisableEnable_Error" 1 "DisableEnable_Enable" 0 "DisableEnable_Disable" ;
VAL_ 1249 OilLevelDrvInstr_OilTempTxt 3 "DisplayText_NotAvailable" 2 "DisplayText_Error" 1 "DisplayText_DisplayText" 0 "DisplayText_DoNotDisplayText" ;
SIG_GROUP_ 725 ESCReqEMS_sg_ISig_4 1 : ESCReqEMS_CtrlTrimMode_ISig_4 ESCReqEMS_CtrlTrimStat_ISig_4 ESCReqEMS_CtrlTrimValue_ISig_4 ESCReqEMS_CtrlTrimReq_ISig_4;
SIG_GROUP_ 725 ESCReqESC_sg_ISig_4 1 : ESCReqESC_CtrlTrimMode_ISig_4 ESCReqESC_CtrlTrimValue_ISig_4 ESCReqESC_CtrlTrimStat_ISig_4 ESCReqESC_CtrlTrimReq_ISig_4;
SIG_GROUP_ 534 IntLightMode_CoreRqst_sg 1 : IntLightMode_CoreRqst_IL_Mode IntLightMode_CoreRqst_EventFlag;
SIG_GROUP_ 1283 TrafficSitPathExecSta_sg 1 : TrafficSitPathExecSta_Type TrafficSitPathExecSta_Speed TrafficSitPathExecSta_Distance;
SIG_GROUP_ 1249 OilLevelDrvInstr_sg 1 : OilLevelDrvInstr_IncorrEngSpe OilLevelDrvInstr_StopVehicle OilLevelDrvInstr_Wait60SecTxt OilLevelDrvInstr_ChangeGearTxt OilLevelDrvInstr_NotHorizonTxt OilLevelDrvInstr_OilTempTxt;
SIG_GROUP_ 1249 HillDataCtrlTECU_sg_ISig_4 1 : HillDataCtrlTECU_State_ISig_4 HillDataCtrlTECU_AckCnt_ISig_4;
